VERSION ""

NS_ :

BS_:

BU_: BPCM ECM EVCU2 IDCM MCPA MCPB SGCP

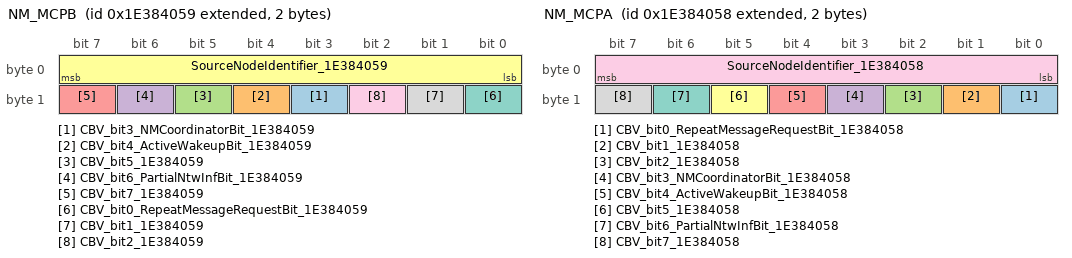
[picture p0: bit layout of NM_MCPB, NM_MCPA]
BO_ 2654486617 NM_MCPB: 2 MCPB
 SG_ CBV_bit3_NMCoordinatorBit_1E384059 : 11|1@0+ (1,0) [0|1] "" SGCP,EVCU2,MCPA,IDCM,BPCM,ECM
 SG_ CBV_bit4_ActiveWakeupBit_1E384059 : 12|1@0+ (1,0) [0|1] "" SGCP,EVCU2,MCPA,IDCM,BPCM,ECM
 SG_ CBV_bit5_1E384059 : 13|1@0+ (1,0) [0|1] "" SGCP,EVCU2,MCPA,IDCM,BPCM,ECM
 SG_ CBV_bit6_PartialNtwInfBit_1E384059 : 14|1@0+ (1,0) [0|1] "" SGCP,EVCU2,MCPA,IDCM,BPCM,ECM
 SG_ CBV_bit7_1E384059 : 15|1@0+ (1,0) [0|1] "" SGCP,EVCU2,MCPA,IDCM,BPCM,ECM
 SG_ SourceNodeIdentifier_1E384059 : 7|8@0+ (1,0) [0|255] "-"  SGCP,EVCU2,MCPA,IDCM,BPCM,ECM
 SG_ CBV_bit0_RepeatMessageRequestBit_1E384059 : 8|1@0+ (1,0) [0|1] "" SGCP,EVCU2,MCPA,IDCM,BPCM,ECM
 SG_ CBV_bit1_1E384059 : 9|1@0+ (1,0) [0|1] "" SGCP,EVCU2,MCPA,IDCM,BPCM,ECM
 SG_ CBV_bit2_1E384059 : 10|1@0+ (1,0) [0|1] "" SGCP,EVCU2,MCPA,IDCM,BPCM,ECM

BO_ 2654486616 NM_MCPA: 2 MCPA
 SG_ CBV_bit0_RepeatMessageRequestBit_1E384058 : 8|1@0+ (1,0) [0|1] "" SGCP,EVCU2,MCPB,IDCM,BPCM,ECM
 SG_ CBV_bit1_1E384058 : 9|1@0+ (1,0) [0|1] "" SGCP,EVCU2,MCPB,IDCM,BPCM,ECM
 SG_ CBV_bit2_1E384058 : 10|1@0+ (1,0) [0|1] "" SGCP,EVCU2,MCPB,IDCM,BPCM,ECM
 SG_ CBV_bit3_NMCoordinatorBit_1E384058 : 11|1@0+ (1,0) [0|1] "" SGCP,EVCU2,MCPB,IDCM,BPCM,ECM
 SG_ CBV_bit4_ActiveWakeupBit_1E384058 : 12|1@0+ (1,0) [0|1] "" SGCP,EVCU2,MCPB,IDCM,BPCM,ECM
 SG_ CBV_bit5_1E384058 : 13|1@0+ (1,0) [0|1] "" SGCP,EVCU2,MCPB,IDCM,BPCM,ECM
 SG_ CBV_bit6_PartialNtwInfBit_1E384058 : 14|1@0+ (1,0) [0|1] "" SGCP,EVCU2,MCPB,IDCM,BPCM,ECM
 SG_ CBV_bit7_1E384058 : 15|1@0+ (1,0) [0|1] "" SGCP,EVCU2,MCPB,IDCM,BPCM,ECM
 SG_ SourceNodeIdentifier_1E384058 : 7|8@0+ (1,0) [0|255] "-"  SGCP,EVCU2,MCPB,IDCM,BPCM,ECM

BO_ 2564682005 DIAGNOSTIC_ROE_MCPB: 8 MCPB
 SG_ N_PDU_18DDF115 : 7|64@0+ (1,0) [0|0] "" EVCU2

BO_ 2564682004 DIAGNOSTIC_ROE_MCPA: 8 MCPA
 SG_ N_PDU_18DDF114 : 7|64@0+ (1,0) [0|0] "" EVCU2

BO_ 2564682261 DIAGNOSTIC_ROE_FD_MCPB: 64 MCPB
 SG_ N_PDU_18DDF215 : 7|64@0+ (1,0) [0|0] "" EVCU2

BO_ 2564682260 DIAGNOSTIC_ROE_FD_MCPA: 64 MCPA
 SG_ N_PDU_18DDF214 : 7|64@0+ (1,0) [0|0] "" EVCU2

BO_ 2564485396 DIAGNOSTIC_RESPONSE_MCPA: 8 MCPA
 SG_ N_PDU_18DAF114 : 7|64@0+ (1,0) [0|0] "" EVCU2

BO_ 2564485653 DIAGNOSTIC_RESPONSE_FD_MCPB: 64 MCPB
 SG_ N_PDU_18DAF215 : 7|64@0+ (1,0) [0|0] "" EVCU2

BO_ 2564485652 DIAGNOSTIC_RESPONSE_FD_MCPA: 64 MCPA
 SG_ N_PDU_18DAF214 : 7|64@0+ (1,0) [0|0] "" EVCU2

BO_ 2564429297 DIAGNOSTIC_REQUEST_MCPB: 8 EVCU2
 SG_ N_PDU_18DA15F1 : 7|64@0+ (1,0) [0|0] "" MCPB

BO_ 2564429041 DIAGNOSTIC_REQUEST_MCPA: 8 EVCU2
 SG_ N_PDU_18DA14F1 : 7|64@0+ (1,0) [0|0] "" MCPA

BO_ 2564429298 DIAGNOSTIC_REQUEST_FD_MCPB: 64 EVCU2
 SG_ N_PDU_18DA15F2 : 7|64@0+ (1,0) [0|0] "" MCPB

BO_ 2564429042 DIAGNOSTIC_REQUEST_FD_MCPA: 64 EVCU2
 SG_ N_PDU_18DA14F2 : 7|64@0+ (1,0) [0|0] "" MCPA

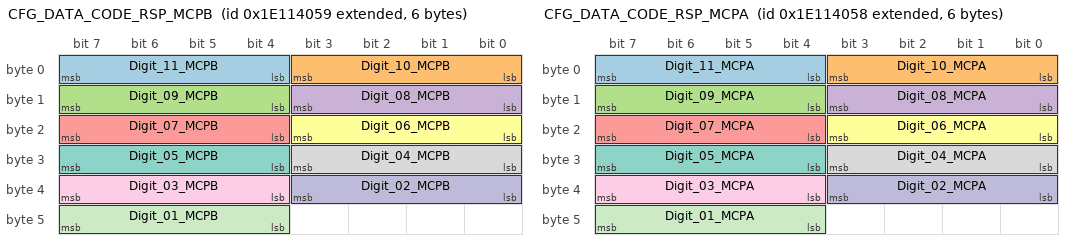
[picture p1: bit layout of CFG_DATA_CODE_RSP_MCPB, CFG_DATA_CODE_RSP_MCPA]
BO_ 2651930713 CFG_DATA_CODE_RSP_MCPB: 6 MCPB
 SG_ Digit_11_MCPB : 7|4@0+ (1,0) [0|15] "-"  EVCU2
 SG_ Digit_10_MCPB : 3|4@0+ (1,0) [0|15] "-"  EVCU2
 SG_ Digit_09_MCPB : 15|4@0+ (1,0) [0|15] "-"  EVCU2
 SG_ Digit_08_MCPB : 11|4@0+ (1,0) [0|15] "-"  EVCU2
 SG_ Digit_07_MCPB : 23|4@0+ (1,0) [0|15] "-"  EVCU2
 SG_ Digit_06_MCPB : 19|4@0+ (1,0) [0|15] "-"  EVCU2
 SG_ Digit_05_MCPB : 31|4@0+ (1,0) [0|15] "-"  EVCU2
 SG_ Digit_04_MCPB : 27|4@0+ (1,0) [0|15] "-"  EVCU2
 SG_ Digit_03_MCPB : 39|4@0+ (1,0) [0|15] "-"  EVCU2
 SG_ Digit_02_MCPB : 35|4@0+ (1,0) [0|15] "-"  EVCU2
 SG_ Digit_01_MCPB : 47|4@0+ (1,0) [0|15] "-"  EVCU2

BO_ 2651930712 CFG_DATA_CODE_RSP_MCPA: 6 MCPA
 SG_ Digit_11_MCPA : 7|4@0+ (1,0) [0|15] "-"  EVCU2
 SG_ Digit_10_MCPA : 3|4@0+ (1,0) [0|15] "-"  EVCU2
 SG_ Digit_09_MCPA : 15|4@0+ (1,0) [0|15] "-"  EVCU2
 SG_ Digit_08_MCPA : 11|4@0+ (1,0) [0|15] "-"  EVCU2
 SG_ Digit_07_MCPA : 23|4@0+ (1,0) [0|15] "-"  EVCU2
 SG_ Digit_06_MCPA : 19|4@0+ (1,0) [0|15] "-"  EVCU2
 SG_ Digit_05_MCPA : 31|4@0+ (1,0) [0|15] "-"  EVCU2
 SG_ Digit_04_MCPA : 27|4@0+ (1,0) [0|15] "-"  EVCU2
 SG_ Digit_03_MCPA : 39|4@0+ (1,0) [0|15] "-"  EVCU2
 SG_ Digit_02_MCPA : 35|4@0+ (1,0) [0|15] "-"  EVCU2
 SG_ Digit_01_MCPA : 47|4@0+ (1,0) [0|15] "-"  EVCU2

BO_ 244 BATTERY_HV: 64 BPCM
 SG_ ImpactHardwireV : 500|1@0+ (1,0) [0|1] "" EVCU2,MCPB,MCPA,IDCM
 SG_ ImpactHardwire : 501|1@0+ (1,0) [0|1] "" EVCU2,MCPB,MCPA,IDCM

BO_ 250 APM_VDCM: 32 IDCM
 SG_ APM_Water_Temp : 95|8@0+ (1,-40) [-40|214] "°C"  EVCU2
 SG_ APM_RecoveryAction : 101|8@0+ (1,0) [0|255] "" EVCU2
 SG_ APM_PSFB_Temp2 : 75|12@0+ (0.1,-40) [-40|369.4] "°C"  EVCU2
 SG_ APM_PSFB_Temp1 : 71|12@0+ (0.1,-40) [-40|369.4] "°C"  EVCU2
 SG_ APM_LV_V_Fbk : 47|12@0+ (0.009143,0) [0|37.431442] "V"  EVCU2
 SG_ APM_LV_I_Fbk : 23|12@0+ (0.076917,0) [0|314.898198] "A"  EVCU2
 SG_ APM_HV_V_Fbk : 51|12@0+ (0.445636,0) [0|1824.433784] "V"  EVCU2
 SG_ APM_HV_I_Fbk : 27|12@0+ (0.002718,0) [0|11.127492] "A"  EVCU2
 SG_ APM_Buck_Temp : 3|12@0+ (0.1,-40) [-40|369.4] "°C"  EVCU2
 SG_ APM_UtilPctOfDCDC : 154|7@0+ (1,0) [0|127] "%"  EVCU2
 SG_ APM_TempColdPlate : 146|8@0+ (1,-40) [-40|215] "degC"  EVCU2
 SG_ APM_PowerLimitMode : 112|1@0+ (1,0) [0|1] "" EVCU2
 SG_ APM_OutputPower : 179|10@0+ (3,0) [0|3069] "W"  EVCU2
 SG_ APM_InputPower : 173|10@0+ (3,0) [0|3069] "W"  EVCU2
 SG_ APM_IdcHvSetPFdbk : 140|10@0+ (0.2,-100) [-100|104.6] "Amp"  EVCU2
 SG_ APM_HvVsetPFdbk : 185|9@0+ (1,0) [0|511] "V"  EVCU2
 SG_ APM_HvOverVStatus : 114|1@0+ (1,0) [0|1] "" EVCU2
 SG_ APM_FailureType : 103|2@0+ (1,0) [0|3] "" EVCU2
 SG_ APM_FailureReason : 122|6@0+ (1,0) [0|63] "" EVCU2
 SG_ APM_EstPwrLoss : 132|8@0+ (2,0) [0|510] "W"  EVCU2
 SG_ APM_DeratingReason : 127|5@0+ (1,0) [0|31] "" EVCU2
 SG_ APM_DeratingModeStatus : 109|3@0+ (1,0) [0|7] "" EVCU2
 SG_ APM_CurrentLimitMode : 113|1@0+ (1,0) [0|1] "" EVCU2
 SG_ APM_CtrlSts_Fbk : 7|4@0+ (1,0) [0|15] "" EVCU2
 SG_ MessageCounter_APM_VDCM : 243|4@0+ (1,0) [0|15] "-"  EVCU2
 SG_ CRC_APM_VDCM : 255|8@0+ (1,0) [0|255] "-"  EVCU2
 SG_ APM_DeratingPower : 163|6@0+ (50,0) [0|3100] "W"  EVCU2

BO_ 2564485397 DIAGNOSTIC_RESPONSE_MCPB: 8 MCPB
 SG_ N_PDU_18DAF115 : 7|64@0+ (1,0) [0|0] "" EVCU2

BO_ 546 VDCM_OBCM2: 64 EVCU2
 SG_ VDCM_MaxChrgTime_sec : 47|8@0+ (10,0) [0|2550] "sec"  IDCM
 SG_ VDCM_MaxChrgTime_min : 39|8@0+ (1,0) [0|255] "min"  IDCM
 SG_ VDCM_EV_Batt_Max_T_Limit : 23|8@0+ (1,0) [0|255] "°C"  IDCM
 SG_ VDCM_EstChrgTime_min : 31|8@0+ (1,0) [0|255] "min"  IDCM
 SG_ VDCM_ChrgMode_Req : 15|8@0+ (1,0) [0|255] "" IDCM
 SG_ VDCM_ChrgCurrDeviationErr : 48|1@0+ (1,0) [0|1] "" IDCM
 SG_ VDCM_ChrgCompleteReason : 63|3@0+ (1,0) [0|7] "" IDCM
 SG_ VDCM_BattUnderVolt : 51|1@0+ (1,0) [0|1] "" IDCM
 SG_ VDCM_BattOverVolt : 52|1@0+ (1,0) [0|1] "" IDCM
 SG_ VDCM_BattFullSOC_prc : 7|8@0+ (1,0) [0|255] "%"  IDCM
 SG_ CPIM_Over_Temperature : 54|1@0+ (1,0) [0|1] "" IDCM
 SG_ CPIM_Error : 55|1@0+ (1,0) [0|1] "" IDCM
 SG_ WeldCheck_Complete : 258|1@0+ (1,0) [0|1] "" IDCM
 SG_ VDCM_SOCIsOOR : 273|2@0+ (1,0) [0|3] "" IDCM
 SG_ VDCM_ChargeCurrIsOOR : 287|2@0+ (1,0) [0|3] "" IDCM
 SG_ VDCM_CellVoltIsOOR : 275|2@0+ (1,0) [0|3] "" IDCM
 SG_ VDCM_BattTempIsOOR : 285|2@0+ (1,0) [0|3] "" IDCM
 SG_ ReadyToChargeState : 259|1@0+ (1,0) [0|1] "" IDCM
 SG_ HCP_SessionStopCmd : 260|1@0+ (1,0) [0|1] "" IDCM
 SG_ HCP_DC_Retry : 249|5@0+ (1,0) [0|31] "" IDCM
 SG_ DCChrg_BatSideCurrent_VDCM : 237|10@0+ (1,-50) [-50|973] "A"  IDCM
 SG_ BMS_Max_Pk_Volt_Allowed_VDCM : 196|10@0+ (1,0) [0|1022] "V"  IDCM
 SG_ BMS_Max_Cell_Volt_Allowed_Vldty : 98|1@0+ (1,0) [0|1] "" IDCM
 SG_ BMS_Max_Cell_Volt_Allowed_VDCM : 95|13@0+ (0.001,0) [0|8.19] "V"  IDCM
 SG_ BMS_HV_Trac_PreCha_Contac_Sts_V : 176|3@0+ (1,0) [0|7] "" MCPB,MCPA,IDCM,BPCM
 SG_ BMS_HV_Trac_Main_Contac_Sts_VDCM : 189|3@0+ (1,0) [0|7] "" MCPB,MCPA,IDCM,BPCM
 SG_ BMS_HV_Temperature_Min_VDCM : 118|11@0+ (0.1,-40) [-40|164.6] "°C"  IDCM
 SG_ BMS_HV_Temperature_Max_VDCM : 97|11@0+ (0.1,-40) [-40|164.6] "°C"  IDCM
 SG_ BMS_HV_SOC_AccuracySts_VDCM : 161|2@0+ (1,0) [0|2] "-"  IDCM
 SG_ BMS_HV_NumCellMinTemp_VDCM : 123|9@0+ (1,0) [0|510] "" IDCM
 SG_ BMS_HV_NumCellMaxVolt_VDCM : 130|8@0+ (1,0) [0|255] "" IDCM
 SG_ BMS_HV_NumCellMaxTemp_VDCM : 172|9@0+ (1,0) [0|510] "" IDCM
 SG_ BMS_HV_Low_Temp_Thrsh_VDCM : 159|11@0+ (0.1,-40) [-40|164.7] "°C"  IDCM
 SG_ BMS_HV_InternalVoltage_VDCM : 213|13@0+ (0.1,90.9) [90.9|910] "V"  MCPB,MCPA,IDCM,BPCM
 SG_ BMS_HV_High_Temp_Thrsh_VDCM : 138|11@0+ (0.1,-40) [-40|164.7] "°C"  IDCM
 SG_ BMS_HV_Common_Contactor_Sts_VDCM : 164|3@0+ (1,0) [0|6] "" MCPB,MCPA,IDCM,BPCM
 SG_ BMS_HV_Battery_GFD_Sts_VDCM : 179|3@0+ (1,0) [0|7] "" MCPB,MCPA,IDCM,BPCM
 SG_ BMS_HV_BatIntrlk_InternalStat_V : 175|3@0+ (1,0) [0|7] "" MCPB,MCPA,IDCM,BPCM
 SG_ BMS_HV_AC_Char_Main_Contac_Sts_ : 200|3@0+ (1,0) [0|7] "" MCPB,MCPA,IDCM,BPCM
 SG_ BMS_Cell_Volt_Min_Vldty_VDCM : 80|1@0+ (1,0) [0|1] "" IDCM
 SG_ BMS_Cell_Volt_Min_VDCM : 77|13@0+ (0.001,0) [0|8.19] "V"  IDCM
 SG_ BMS_Cell_Volt_Max_Vldty_VDCM : 78|1@0+ (1,0) [0|1] "" IDCM
 SG_ BMS_Cell_Volt_Max_VDCM : 59|13@0+ (0.001,0) [0|8.19] "V"  IDCM
 SG_ AC_Chrg_Branch_Voltage_VDCM : 243|10@0+ (1,0) [0|1023] "V"  IDCM
 SG_ BMS_HV_Char_PreCha_Contac_Sts_V : 199|3@0+ (1,0) [0|7] "" MCPB,MCPA,IDCM,BPCM
 SG_ BMS_HV_Char_Main_Contac_Sts_VDCM : 186|3@0+ (1,0) [0|7] "" MCPB,MCPA,IDCM,BPCM
 SG_ BMS_HV_TractionBusVoltage_VDCM : 311|10@0+ (1,0) [0|1023] "V"  MCPB,MCPA,IDCM,BPCM
 SG_ BMS_HV_Trac_Bus_Sts_VDCM : 283|3@0+ (1,0) [0|7] "" MCPB,MCPA,IDCM,BPCM
 SG_ BMS_HV_ChargingBusVoltage_VDCM : 289|10@0+ (1,0) [0|1023] "V"  MCPB,MCPA,IDCM,BPCM
 SG_ BMS_HV_Char_Bus_Sts_VDCM : 280|3@0+ (1,0) [0|7] "" MCPB,MCPA,IDCM,BPCM
 SG_ BMS_HV_BatState_VDCM : 293|4@0+ (1,0) [0|15] "" MCPB,MCPA,IDCM,BPCM
 SG_ BMS_HV_BatActualPower_VDCM : 317|15@0+ (0.1,-1638.3) [-1638.3|1638.4] "kW"  MCPB,MCPA,IDCM,BPCM
 SG_ VDCM_ChargingPermitting : 53|1@0+ (1,0) [0|1] "" IDCM
 SG_ GBT_Target_Voltage_Reached : 334|2@0+ (1,0) [0|3] "" IDCM
 SG_ GBT_Target_Cell_Voltage_Reached : 332|2@0+ (1,0) [0|3] "" IDCM
 SG_ GBT_Ready_to_Charge : 60|1@0+ (1,0) [0|1] "" IDCM
 SG_ GBT_Desired_SOC_Reached : 50|2@0+ (1,0) [0|3] "" IDCM
 SG_ GBT_Charger_Active_Interruption : 330|2@0+ (1,0) [0|3] "" IDCM
 SG_ MessageCounter_VO2 : 435|4@0+ (1,0) [0|15] "" IDCM,BPCM
 SG_ CRC_VO2 : 447|8@0+ (1,0) [0|255] "" IDCM,BPCM

BO_ 496 PARK_DATA: 24 MCPB
 SG_ MessageCounter_PARK_DATA : 115|4@0+ (1,0) [0|15] "" EVCU2
 SG_ CRC_PARK_DATA : 127|8@0+ (1,0) [0|255] "" EVCU2
 SG_ PlockFailSts : 4|3@0+ (1,0) [0|6] "" EVCU2
 SG_ Plock_PosSensor : 1|3@0+ (1,0) [0|6] "" EVCU2
 SG_ Plock_MotorPosSts : 29|3@0+ (1,0) [0|6] "" EVCU2
 SG_ MPR_PosSensor : 14|3@0+ (1,0) [0|6] "" EVCU2
 SG_ Plock_fdbk_sts : 7|3@0+ (1,0) [0|7] "" EVCU2

BO_ 544 OBCM_VDCM2: 64 IDCM
 SG_ Plug_Locked_by_EVSE : 52|2@0+ (1,0) [0|2] "" EVCU2
 SG_ HVCMS_EVSEID : 7|32@0+ (1,0) [0|4294967294] "" EVCU2
 SG_ ExtChargerSts : 42|2@0+ (1,0) [0|2] "" EVCU2
 SG_ EVSE_Error : 54|2@0+ (1,0) [0|2] "" EVCU2
 SG_ EVSE_ChrgStopControl : 40|2@0+ (1,0) [0|2] "" EVCU2
 SG_ Charger_WeldingDetectAvail : 44|2@0+ (1,0) [0|2] "" EVCU2
 SG_ Charger_StndbyReqReason : 47|3@0+ (1,0) [0|6] "" EVCU2
 SG_ Charger_StndbyReq : 33|2@0+ (1,0) [0|2] "" EVCU2
 SG_ Charger_FaultStates : 37|4@0+ (1,0) [0|14] "" EVCU2
 SG_ CC2VoltDetError : 39|2@0+ (1,0) [0|2] "" EVCU2
 SG_ OBCM_CSSts : 152|2@0+ (1,0) [0|3] "" EVCU2
 SG_ OBCM_CP3Sts : 158|3@0+ (1,0) [0|7] "" EVCU2
 SG_ OBCM_CP2Sts : 145|3@0+ (1,0) [0|7] "" EVCU2
 SG_ OBCM_CCSts : 155|3@0+ (1,0) [0|7] "" EVCU2
 SG_ OBCM_APAMSts : 147|2@0+ (1,0) [0|3] "" EVCU2
 SG_ TCP_Communication_Terminated : 162|1@0+ (1,0) [0|1] "" EVCU2
 SG_ OBCM_CP1Sts : 166|3@0+ (1,0) [0|7] "" EVCU2
 SG_ TxGBTMessageResponse : 61|5@0+ (1,0) [0|31] "" EVCU2
 SG_ TxGBTMessageRequest : 50|5@0+ (1,0) [0|31] "" EVCU2
 SG_ OBCM_Timeout : 56|1@0+ (1,0) [0|1] "" EVCU2
 SG_ EVCC_FailureSts : 163|1@0+ (1,0) [0|1] "" EVCU2
 SG_ CC2_VoltageValue : 71|8@0+ (0.1,0) [0|25.5] "V"  EVCU2
 SG_ GBT_EVSE_Charge_Permitting : 79|1@0+ (1,0) [0|1] "" EVCU2
 SG_ MessageCounter_OV2 : 435|4@0+ (1,0) [0|15] "" EVCU2
 SG_ CRC_OV2 : 447|8@0+ (1,0) [0|255] "" EVCU2
 SG_ EVSE_NotificationMaxDelay : 87|18@0+ (1,0) [0|262143] "s"  EVCU2

BO_ 1454 MCPB_DATA: 16 MCPB
 SG_ MCPB_Service_Lamp_Request : 22|1@0+ (1,0) [0|1] "" EVCU2

BO_ 1444 MCPA_DATA: 16 MCPA
 SG_ MCPA_Service_Lamp_Request : 22|1@0+ (1,0) [0|1] "" EVCU2

BO_ 1790 BATTERY_HV2: 32 BPCM
 SG_ BMS_HV_SOC_AccuracySts : 17|2@0+ (1,0) [0|2] "-"  EVCU2
 SG_ BMS_HV_Low_Temp_Thrsh : 12|11@0+ (0.1,-40) [-40|164.7] "°C"  EVCU2
 SG_ BMS_HV_High_Temp_Thrsh : 7|11@0+ (0.1,-40) [-40|164.7] "°C"  EVCU2
 SG_ HVBatCell_Voltage_Low_Thrsh : 49|13@0+ (0.001,0) [0|8.191] "" EVCU2
 SG_ HVBatCell_Voltage_High_Thrsh : 46|13@0+ (0.001,0) [0|8.191] "" EVCU2
 SG_ HEV_OnRq_BPCM : 31|1@0+ (1,0) [0|1] "" EVCU2
 SG_ BMS_HV_SOC_Min : 30|8@0+ (0.391257,0) [0|100] "%"  EVCU2
 SG_ BMS_HV_SOC_Max : 38|8@0+ (0.392157,0) [0|100] "%"  EVCU2

BO_ 105 VDCM_PWT3: 64 EVCU2
 SG_ T7_Sensor_Temp : 330|11@0+ (0.1,-40) [-40|164.7] "°C"  SGCP,MCPB,MCPA
 SG_ T7_CoolantTempVldty : 331|1@0+ (1,0) [0|1] "" SGCP,MCPB,MCPA
 SG_ T4_Sensor_Temp : 378|11@0+ (0.1,-40) [-40|164.7] "°C"  SGCP,MCPB,MCPA
 SG_ PwrElecSnsr_TEMP : 55|8@0+ (1,-40) [-40|215] "°C"  SGCP
 SG_ PwrElecPmp_TEMP : 47|8@0+ (1,-40) [-40|215] "°C"  SGCP
 SG_ ClrLgsDiagInfo : 431|1@0+ (1,0) [0|1] "" IDCM
 SG_ PIMRR_CoolantFlow : 318|7@0+ (0.5,0) [0|63.5] "Lpm"  SGCP

BO_ 260 PIM_RR: 64 MCPB
 SG_ INVRRInterlockSts : 253|2@0+ (1,0) [0|3] "" EVCU2
 SG_ InvRR_DC_Voltage : 191|10@0+ (1,0) [0|1022] "V"  EVCU2
 SG_ InvRR_DerateReason : 143|4@0+ (1,0) [0|15] "-"  EVCU2
 SG_ InvRR_ACVoltage : 104|10@0+ (1,0) [0|1022] "V"  EVCU2
 SG_ RPM_MCPB : 22|16@0+ (1,-32768) [-32768|32767] "rpm"  EVCU2
 SG_ MCPB_Torque_Achieved_V : 38|1@0+ (1,0) [0|1] "" EVCU2
 SG_ MCPB_Torque_Achieved : 251|13@0+ (0.125,-512) [-512|511.875] "Nm"  EVCU2
 SG_ MCPB_TorqAchieved_AEMD_V : 35|1@0+ (1,0) [0|1] "" EVCU2
 SG_ MCPB_TorqAchieved_AEMD : 302|13@0+ (0.125,-512) [-512|511.875] "Nm"  EVCU2
 SG_ MCPB_Spd_Lim : 343|16@0+ (1,-32767) [-32767|32678] "rpm"  EVCU2
 SG_ MCPB_RPM_V : 204|1@0+ (1,0) [0|1] "" EVCU2
 SG_ MCPB_MtrMinCpbltyTrq : 324|13@0+ (0.125,-512) [-512|511.875] "Nm"  EVCU2
 SG_ MCPB_MtrMaxCpbltyTrq : 305|13@0+ (0.125,-512) [-512|511.875] "Nm"  EVCU2
 SG_ MCPB_MtrIndex : 147|5@0+ (1,0) [0|31] "" EVCU2
 SG_ MCPB_MinTorq : 283|13@0+ (0.125,-512) [-512|511.875] "Nm"  EVCU2
 SG_ MCPB_MaxTorq : 264|13@0+ (0.125,-512) [-512|511.875] "Nm"  EVCU2
 SG_ MCPB_Invrtr_State : 151|4@0+ (1,0) [0|15] "" EVCU2
 SG_ MCPB_HV_CnctrOpn_Req : 34|1@0+ (1,0) [0|1] "" EVCU2
 SG_ MCPB_Dschrge_Status : 102|2@0+ (1,0) [0|3] "" EVCU2
 SG_ MCPB_DeratingFactor : 270|6@0+ (0.02,0) [0|1.26] "" EVCU2
 SG_ MCPB_DC_Volt_V : 36|1@0+ (1,0) [0|1] "" EVCU2
 SG_ MCPB_DC_Current_V : 37|1@0+ (1,0) [0|1] "" EVCU2
 SG_ MCPB_DC_Current : 391|15@0+ (0.1,-1638.4) [-1638.4|1638.3] "A"  EVCU2,BPCM
 SG_ MCPB_CpbltySpdDivVolt : 392|16@0+ (1,0) [0|65535] "V"  EVCU2
 SG_ MCPB_AccelRawV : 32|1@0+ (1,0) [0|1] "" EVCU2
 SG_ MCPB_AccelRaw : 359|16@0+ (1,0) [0|65535] "" EVCU2
 SG_ MCPB_6SO_Status : 47|2@0+ (1,0) [0|3] "" EVCU2
 SG_ MCPB_3PS_Pos : 33|1@0+ (1,0) [0|1] "" EVCU2
 SG_ MC_PRR1 : 499|4@0+ (1,0) [0|15] "" EVCU2,BPCM
 SG_ InvRR_CoolantTemp : 375|11@0+ (0.1,-40) [-40|164.7] "°C"  EVCU2
 SG_ CRC_PRR1 : 511|8@0+ (1,0) [0|255] "" EVCU2,BPCM
 SG_ MCPB_SPT_Stat : 158|2@0+ (1,0) [0|3] "" EVCU2

BO_ 1062 MCPA_DATA2: 64 MCPA
 SG_ MCPA_Temp : 7|8@0+ (1,-40) [-40|215] "°C"  EVCU2
 SG_ MCPA_Rotor_Temperature : 31|8@0+ (1,-40) [-40|215] "°C"  EVCU2
 SG_ MCPA_Inverter_Temp : 15|8@0+ (1,-40) [-40|215] "°C"  EVCU2
 SG_ MCPA_Control_Board_Temperature : 23|8@0+ (1,-40) [-40|215] "°C"  EVCU2
 SG_ CLrDiagInfo_MCPA : 248|1@0+ (1,0) [0|1] "" EVCU2
 SG_ MessageCounter_MCPA_DATA2 : 435|4@0+ (1,0) [0|15] "" EVCU2
 SG_ CRC_MCPA_DATA2 : 447|8@0+ (1,0) [0|255] "" EVCU2
 SG_ MCPA_PIM_DC_Side_Busbar_Temp : 423|8@0+ (1,-40) [-40|215] "°C"  EVCU2
 SG_ MCPA_Service_Lamp_Request_2 : 47|1@0+ (1,0) [0|1] "" EVCU2

BO_ 1031 HV_CHARGER1: 64 IDCM
 SG_ InputCurrentAvailable : 96|9@0+ (1,0) [0|300] "Amp"  EVCU2
 SG_ AC_Side_Volt3 : 164|13@0+ (0.1,0) [0|819] "Volts"  EVCU2
 SG_ AC_Side_Volt2 : 145|13@0+ (0.1,0) [0|819] "Volts"  EVCU2
 SG_ AC_Side_Volt1 : 142|13@0+ (0.1,0) [0|819] "Volts"  EVCU2
 SG_ AC_Side_Curr3 : 121|11@0+ (0.1,-100) [-100|104.6] "Amp"  EVCU2
 SG_ AC_Side_Curr2 : 65|11@0+ (0.1,-100) [-100|104.6] "Amp"  EVCU2
 SG_ AC_Side_Curr1 : 19|11@0+ (0.1,-100) [-100|104.6] "Amp"  EVCU2
 SG_ ProximitySts : 39|3@0+ (1,0) [0|7] "-"  EVCU2
 SG_ OBCM_SlacSts : 54|2@0+ (1,0) [0|3] "-"  EVCU2
 SG_ OBCM_SdpSts : 102|2@0+ (1,0) [0|3] "" EVCU2
 SG_ OBCInterlockSts : 86|2@0+ (1,0) [0|3] "" EVCU2
 SG_ OBC_DeratingReason : 7|4@0+ (1,0) [0|15] "-"  EVCU2
 SG_ J1772_State : 22|3@0+ (1,0) [0|7] "-"  EVCU2
 SG_ J1772_S2_Sts : 23|1@0+ (1,0) [0|1] "-"  EVCU2
 SG_ InputVoltage_isAC : 82|1@0+ (1,0) [0|1] "-"  EVCU2
 SG_ InputVoltage_is60Hz : 71|1@0+ (1,0) [0|1] "-"  EVCU2
 SG_ HV_Overvoltage : 69|1@0+ (1,0) [0|1] "-"  EVCU2
 SG_ HV_Overcurrent : 68|1@0+ (1,0) [0|1] "-"  EVCU2
 SG_ ControlPilotSts : 36|3@0+ (1,0) [0|7] "-"  EVCU2
 SG_ ChargeEnableSts : 181|2@0+ (1,0) [0|2] "-"  EVCU2
 SG_ ChargeCurrentAvailable : 49|10@0+ (0.1,0) [0|102.3] "Amp"  EVCU2
 SG_ ChargeCurrent : 33|10@0+ (0.1,0) [0|102.3] "Amp"  EVCU2
 SG_ BatterySideCurrent : 81|11@0+ (0.1,-50) [-50|154.7] "Amp"  EVCU2
 SG_ AC_Present : 70|1@0+ (1,0) [0|1] "-"  EVCU2
 SG_ AC_HighLoadWarning : 51|1@0+ (1,0) [0|1] "-"  EVCU2
 SG_ Supported_VerNumberMinor : 264|3@0+ (1,0) [0|7] "" EVCU2
 SG_ Supported_VerNumberMajor : 267|3@0+ (1,0) [0|7] "" EVCU2
 SG_ Supported_SchemaID : 270|3@0+ (1,0) [0|7] "" EVCU2
 SG_ Supported_ProtocolName : 257|3@0+ (1,0) [0|7] "" EVCU2
 SG_ MessageCounter_HV_CHARGER1 : 179|4@0+ (1,0) [0|15] "-"  EVCU2
 SG_ EVCC_FailureReason : 263|6@0+ (1,0) [0|63] "" EVCU2
 SG_ CRC_HV_CHARGER1 : 191|8@0+ (1,0) [0|255] "-"  EVCU2
 SG_ BatterySideVoltage : 119|14@0+ (0.1,0) [0|1638.3] "Volts"  EVCU2
 SG_ AC_LnLow : 50|1@0+ (1,0) [0|1] "" EVCU2
 SG_ AC_LnHi : 183|1@0+ (1,0) [0|1] "" EVCU2
 SG_ RCD : 274|1@0+ (1,0) [0|1] "-"  EVCU2
 SG_ EVSENominalVoltage : 273|10@0+ (1,0) [0|1023] "V"  EVCU2
 SG_ EVSEMaxCurrent : 288|9@0+ (1,0) [0|511] "A"  EVCU2

BO_ 300 INVTARGET1: 64 EVCU2
 SG_ UDCMax_Unlim_MCPB : 113|16@0+ (0.01,0) [0|655.35] "V"  MCPB
 SG_ UDCMax_Unlim_MCPA : 65|16@0+ (0.01,0) [0|655.35] "V"  MCPA
 SG_ TqGrdtLim_MCPB : 144|16@0+ (0.1,0) [0|6553.5] "Nm/s"  MCPB
 SG_ TqGrdtLim_MCPA : 97|16@0+ (0.1,0) [0|6553.5] "Nm/s"  MCPA
 SG_ TorqueCommand_MCPB : 201|13@0+ (0.125,-512) [-512|511.875] "Nm"  MCPB
 SG_ TorqueCommand_MCPA : 7|13@0+ (0.125,-512) [-512|511.875] "Nm"  MCPA
 SG_ TargetMotorRPM_MCPB : 216|16@0+ (0.5,-16384) [-16384|16383.5] "rpm"  MCPB
 SG_ TargetMotorRPM_MCPA : 22|16@0+ (0.5,-16384) [-16384|16383.5] "rpm"  MCPA
 SG_ SpdGrdtLim_MCPB : 273|11@0+ (20,0) [0|40940] "rpm/s"  MCPB
 SG_ SpdGrdtLim_MCPA : 160|11@0+ (20,0) [0|40940] "rpm/s"  MCPA
 SG_ Mtr_6SO_Request_MCPB : 145|1@0+ (1,0) [0|1] "" MCPB
 SG_ Mtr_6SO_Request_MCPA : 38|1@0+ (1,0) [0|1] "" MCPA
 SG_ ModeCommand_MCPB : 220|4@0+ (1,0) [0|15] "" MCPB
 SG_ ModeCommand_MCPA : 10|4@0+ (1,0) [0|15] "" MCPA
 SG_ MessageCounter_INVTARGET1 : 435|4@0+ (1,0) [0|15] "" SGCP,MCPB,MCPA
 SG_ CRC_INVTARGET1 : 447|8@0+ (1,0) [0|255] "" SGCP,MCPB,MCPA
 SG_ AEMD_MinOffset_MCPB : 252|12@0+ (0.125,-511.875) [-511.875|0] "Nm"  MCPB
 SG_ AEMD_MinOffset_MCPA : 41|12@0+ (0.125,-511.875) [-511.875|0] "Nm"  MCPA
 SG_ AEMD_MaxOffset_MCPB : 232|12@0+ (0.125,0) [0|511.875] "Nm"  MCPB
 SG_ AEMD_MaxOffset_MCPA : 37|12@0+ (0.125,0) [0|511.875] "Nm"  MCPA
 SG_ AEMD_Sclr_Gn_MCPB : 356|9@0+ (0.01,0) [0|5.11] "rad/s"  MCPB
 SG_ AEMD_Sclr_Gn_MCPA : 349|9@0+ (0.01,0) [0|5.11] "rad/s"  MCPA
 SG_ AEMD_Cutoff_FreqHigh_MCPB : 383|8@0+ (0.1,0) [0|25.5] "Hz"  MCPB
 SG_ AEMD_Cutoff_FreqHigh_MCPA : 375|8@0+ (0.1,0) [0|25.5] "Hz"  MCPA
 SG_ Pwr_Electronics_Loop_FlwRate_MC : 57|8@0+ (0.1,0) [0|25.5] "LPM"  MCPA
 SG_ AEMD_Cutoff_FreqLow_MCPB : 407|8@0+ (0.1,4.5) [4.5|30] "Hz"  MCPB
 SG_ AEMD_Cutoff_FreqLow_MCPA : 399|8@0+ (0.1,4.5) [4.5|30] "Hz"  MCPA
 SG_ Pwr_Elec_Loop_FlwRate_MC : 265|8@0+ (0.1,0) [0|25.5] "LPM"  MCPB

CM_ SG_ 1031 InputCurrentAvailable "J1772 input curent available";
CM_ SG_ 1031 AC_Side_Volt3 "AC line voltage3p, p3";
CM_ SG_ 1031 AC_Side_Volt2 "AC line voltage3p, p2";
CM_ SG_ 1031 AC_Side_Volt1 "AC line voltage3p, p1";
CM_ SG_ 1031 AC_Side_Curr3 "AC line current3p, p3";
CM_ SG_ 1031 AC_Side_Curr2 "AC line current3p, p2";
CM_ SG_ 1031 AC_Side_Curr1 "AC line current3p, p1";
CM_ SG_ 260 INVRRInterlockSts "Rear right inverter interlock state";
CM_ SG_ 260 InvRR_DC_Voltage "This signal indicates the Inverter Rear Right DC Voltage.";
CM_ SG_ 1031 ProximitySts "Proximity status based on the voltage level";
CM_ SG_ 1031 OBCM_SlacSts "Communication PLC protocol status, SLAC process";
CM_ SG_ 1031 OBCM_SdpSts "Network protocol implementation status";
CM_ SG_ 1031 OBCInterlockSts "OBCM interlock state";
CM_ SG_ 1031 OBC_DeratingReason "OBCM recovery action";
CM_ SG_ 1031 J1772_State "J1772 status";
CM_ SG_ 1031 InputVoltage_isAC "Input voltage is a/c (dc - [0], ac - [1])";
CM_ SG_ 1031 InputVoltage_is60Hz "Input voltage frrequency is 60 hz (50 hz - [0], 60 hz - [1])";
CM_ SG_ 1031 HV_Overvoltage "High voltage - over voltage";
CM_ SG_ 1031 HV_Overcurrent "High voltage over current";
CM_ SG_ 1031 ControlPilotSts "EVSE pilot status";
CM_ SG_ 1031 ChargeEnableSts "OBCM Feedback status.";
CM_ SG_ 1031 ChargeCurrentAvailable ".";
CM_ SG_ 1031 ChargeCurrent ".";
CM_ SG_ 1031 BatterySideCurrent "Battery side current";
CM_ SG_ 1031 AC_Present "AC line detection";
CM_ SG_ 1031 AC_HighLoadWarning "Infrastructure overload";
CM_ SG_ 250 APM_Water_Temp "This signal indicates the Estimated water temperature  into the cooling channel.";
CM_ SG_ 250 APM_RecoveryAction "This signal indicates the APM recovery action according to fault error";
CM_ SG_ 250 APM_PSFB_Temp2 "This signal indicates the Measured temperature on the phase shift full bridge converter hot spot 2";
CM_ SG_ 250 APM_PSFB_Temp1 "This signal indicates the Measured temperature on the phase shift full bridge converter hot spot 1";
CM_ SG_ 250 APM_LV_V_Fbk "This signal indicates the LV voltage feedback.";
CM_ SG_ 250 APM_LV_I_Fbk "This signal indicates the LV bus current feedback.";
CM_ SG_ 250 APM_HV_V_Fbk "This signal indicates the HV voltage feedback.";
CM_ SG_ 250 APM_HV_I_Fbk "This signal indicates the HV bus current feedback.";
CM_ SG_ 250 APM_Buck_Temp "This signal indicates the Buck stage hot spot temperature.";
CM_ SG_ 546 VDCM_MaxChrgTime_sec "For comm with charging station type A";
CM_ SG_ 546 VDCM_MaxChrgTime_min "For comm with charging station type A";
CM_ SG_ 546 VDCM_EV_Batt_Max_T_Limit "For comm with charging station type B";
CM_ SG_ 546 VDCM_EstChrgTime_min "For comm with charging station type A";
CM_ SG_ 546 VDCM_ChrgMode_Req "For comm with charging station type B";
CM_ SG_ 546 VDCM_BattFullSOC_prc "For comm with charging station type B";
CM_ SG_ 260 InvRR_DerateReason "Inverter Derating Reason.";
CM_ SG_ 260 InvRR_ACVoltage "AC RMS Voltage.";
CM_ SG_ 496 MessageCounter_PARK_DATA "This signal is a counter used for safety checks strategies. This counter is incremented of 1 (one) unit at each frame transmission.";
CM_ SG_ 496 CRC_PARK_DATA "CRC according to SAE J1850 standard at each frame transmission.";
CM_ SG_ 544 Charger_StndbyReq "For communication with charging station type B";
CM_ SG_ 544 CC2VoltDetError "For communication with charging station type B";
CM_ SG_ 1790 BMS_HV_SOC_AccuracySts "This signal indicates the Validity of the SOC value read";
CM_ SG_ 1790 BMS_HV_Low_Temp_Thrsh "This signal indicates the lowest battery pack temperature allowed.";
CM_ SG_ 1790 BMS_HV_High_Temp_Thrsh "This signal indicates the highest battery pack temperature allowed.";
CM_ SG_ 105 T7_Sensor_Temp "T7 Temperature sensor";
CM_ SG_ 105 T7_CoolantTempVldty "Inlet inverter temperature validity";
CM_ SG_ 105 T4_Sensor_Temp "T4 Temperature sensor";
CM_ SG_ 105 PwrElecSnsr_TEMP "PwrElecSensor_TEMP";
CM_ SG_ 105 PwrElecPmp_TEMP "PwrElecPmp temperature";
CM_ SG_ 105 ClrLgsDiagInfo "Clear Legislated Diagnostic Information";
CM_ SG_ 546 WeldCheck_Complete "Weld check complete";
CM_ SG_ 546 ReadyToChargeState "Bit to indicate if EV is ready to charge or not";
CM_ SG_ 546 HCP_SessionStopCmd "Session stop command to stop charging";
CM_ SG_ 546 HCP_DC_Retry "Retry command";
CM_ SG_ 546 DCChrg_BatSideCurrent_VDCM "DC Charging Current, measured in boost, read from EVSE in bypass";
CM_ SG_ 546 BMS_Max_Pk_Volt_Allowed_VDCM "This signal indicates the Maximum battery pack voltage allowed.";
CM_ SG_ 546 BMS_Max_Cell_Volt_Allowed_Vldty "This signal indicates the Max cell voltage allowed valid.";
CM_ SG_ 546 BMS_Max_Cell_Volt_Allowed_VDCM "This signal indicates the Max cell voltage allowed.";
CM_ SG_ 546 BMS_HV_Trac_PreCha_Contac_Sts_V "Traction pre-charge contactor Physical relay status";
CM_ SG_ 546 BMS_HV_Trac_Main_Contac_Sts_VDCM "Traction main contactor physical relay status";
CM_ SG_ 546 BMS_HV_Temperature_Min_VDCM "Battery Minimum Temperature";
CM_ SG_ 546 BMS_HV_Temperature_Max_VDCM "Battery Average Temperature";
CM_ SG_ 546 BMS_HV_SOC_AccuracySts_VDCM "This signal indicates the Validity of the SOC value read";
CM_ SG_ 546 BMS_HV_NumCellMinTemp_VDCM "This signal indicates the Numner of the battery cell with the lowest temperature.";
CM_ SG_ 546 BMS_HV_NumCellMaxVolt_VDCM "This signal indicates the ID No. of cell with max. voltage";
CM_ SG_ 546 BMS_HV_NumCellMaxTemp_VDCM "This signal indicates the Number of the battery cell with the highest temperature.";
CM_ SG_ 546 BMS_HV_Low_Temp_Thrsh_VDCM "This signal indicates the lowest battery pack temperature allowed.";
CM_ SG_ 546 BMS_HV_InternalVoltage_VDCM "This signal indicates the Battery internal voltage as interpreted from VDCM.";
CM_ SG_ 546 BMS_HV_High_Temp_Thrsh_VDCM "This signal indicates the highest battery pack temperature allowed.";
CM_ SG_ 546 BMS_HV_Common_Contactor_Sts_VDCM "HV Bus common contactor status";
CM_ SG_ 546 BMS_HV_Battery_GFD_Sts_VDCM "HV Battery ground fault detection(Isolation)";
CM_ SG_ 546 BMS_HV_BatIntrlk_InternalStat_V "HVIL Status internal";
CM_ SG_ 546 BMS_HV_AC_Char_Main_Contac_Sts_ "AC Charging main contactor physical relay status from VDCM";
CM_ SG_ 546 BMS_Cell_Volt_Min_Vldty_VDCM "This signal indicates the Min cell voltage validity.";
CM_ SG_ 546 BMS_Cell_Volt_Min_VDCM "This signal indicates the Min cell voltage.";
CM_ SG_ 546 BMS_Cell_Volt_Max_Vldty_VDCM "This signal indicates the Max cell voltage validity.";
CM_ SG_ 546 BMS_Cell_Volt_Max_VDCM "This signal indicates the Max cell voltage.";
CM_ SG_ 546 AC_Chrg_Branch_Voltage_VDCM "Voltage measured after AC charge switch interpreted by VDCM";
CM_ SG_ 260 RPM_MCPB "Motor B Speed Raw";
CM_ SG_ 260 MCPB_Torque_Achieved_V "Achieved Torque value Validity, [1] = True";
CM_ SG_ 260 MCPB_Torque_Achieved "Motr B Torque Achieved";
CM_ SG_ 260 MCPB_TorqAchieved_AEMD_V "Motor Torque Achieved Validity";
CM_ SG_ 260 MCPB_TorqAchieved_AEMD "Motor Torque Achieved";
CM_ SG_ 260 MCPB_Spd_Lim "Limited motor speed during reduced performance from MCP B";
CM_ SG_ 260 MCPB_RPM_V "Motor B Speed Validity, [1] = True";
CM_ SG_ 260 MCPB_MtrMinCpbltyTrq "Motor B Min Capability Torque";
CM_ SG_ 260 MCPB_MtrMaxCpbltyTrq "Motor B Max Capability Torque";
CM_ SG_ 260 MCPB_MtrIndex "Motor B Capability Curve Array Index";
CM_ SG_ 260 MCPB_MinTorq "Motor B Minimum Torque";
CM_ SG_ 260 MCPB_MaxTorq "Motor B Maximum Torque";
CM_ SG_ 260 MCPB_Invrtr_State "Inverter State of Operation of Motor B";
CM_ SG_ 260 MCPB_HV_CnctrOpn_Req "HV Battery pack contactor request";
CM_ SG_ 260 MCPB_Dschrge_Status "The active discharge status of MCPB";
CM_ SG_ 260 MCPB_DeratingFactor "Motor B Derating Factor";
CM_ SG_ 260 MCPB_DC_Volt_V "Achieved Torque value Validity, [1] = True";
CM_ SG_ 260 MCPB_DC_Current_V "Achieved Torque value Validity, [1] = True";
CM_ SG_ 260 MCPB_DC_Current "Motor B DC Current";
CM_ SG_ 260 MCPB_CpbltySpdDivVolt "Motor B Speed at Capability Curve";
CM_ SG_ 260 MCPB_AccelRawV "Motor B Acceleration Validity";
CM_ SG_ 260 MCPB_AccelRaw "Motor B Acceleration";
CM_ SG_ 260 MCPB_6SO_Status "Motor B 6SO Status";
CM_ SG_ 260 MCPB_3PS_Pos "3 phase motor short possible from MCP B; True = [1]";
CM_ SG_ 496 PlockFailSts "Park Lock Fail Sts";
CM_ SG_ 496 Plock_PosSensor "Par lock physical position sensor feedback";
CM_ SG_ 496 Plock_MotorPosSts "Park lock motor position status";
CM_ SG_ 496 MPR_PosSensor "Manual Park Release sensor feedback";
CM_ SG_ 544 OBCM_CSSts "Proximity signal of CHAdeMO charging Plug";
CM_ SG_ 544 OBCM_CP3Sts "CP3 line status for CHAdeMO";
CM_ SG_ 544 OBCM_CP2Sts "CP2 line status for CHAdeMO";
CM_ SG_ 544 OBCM_CCSts "Proximity signal of GBT charging contact";
CM_ SG_ 544 OBCM_APAMSts "Status of charging station LV supply on terminals A plus and A minus for GB/T charging";
CM_ SG_ 1454 MCPB_Service_Lamp_Request "The Service Lamp Request from the MCPB";
CM_ SG_ 1062 MCPA_Temp "Motor A temperature";
CM_ SG_ 1062 MCPA_Rotor_Temperature "Rotor Temperature from Motor";
CM_ SG_ 1062 MCPA_Inverter_Temp "Inverter B Temperature";
CM_ SG_ 1062 MCPA_Control_Board_Temperature "Control Board temperature from Motor";
CM_ SG_ 1062 CLrDiagInfo_MCPA "Legislative Diagnostic Clear information for MCPA";
CM_ SG_ 1444 MCPA_Service_Lamp_Request "The Service Light Request from the MCPA";
CM_ SG_ 300 UDCMax_Unlim_MCPB "Maximum DC voltage limit before linear generator derating Consider Max or Min torque. Default 52V";
CM_ SG_ 300 UDCMax_Unlim_MCPA "Maximum DC voltage limit before linear generator derating Consider Max or Min torque. Default 52V";
CM_ SG_ 300 TqGrdtLim_MCPB "Positive or Negative Torque Gradient applied for Torque Control Mode and Speed Control Mode. Default 1000Nm/s";
CM_ SG_ 300 TqGrdtLim_MCPA "Positive or Negative Torque Gradient applied for Torque Control Mode and Speed Control Mode. Default 1000Nm/s";
CM_ SG_ 300 TorqueCommand_MCPB "Torque command for MCPB";
CM_ SG_ 300 TorqueCommand_MCPA "Torque command for MCPA";
CM_ SG_ 300 TargetMotorRPM_MCPB "Target Motor RPM for MCPB";
CM_ SG_ 300 TargetMotorRPM_MCPA "Target Motor RPM for MCPA";
CM_ SG_ 300 SpdGrdtLim_MCPB "Positive or negative (symetric) Speed Request Gradient applicable on both sign only for Speed Control Mode. Default 25,000 rpm/s";
CM_ SG_ 300 SpdGrdtLim_MCPA "Positive or negative (symetric) Speed Request Gradient applicable on both sign only for Speed Control Mode. Default 25,000 rpm/s";
CM_ SG_ 300 Mtr_6SO_Request_MCPB "Six Switch Open Request  for MCPB (1=RequestActive; 0=RequestNotActive)";
CM_ SG_ 300 Mtr_6SO_Request_MCPA "Six Switch Open Request  for MCPA (1=RequestActive; 0=RequestNotActive)";
CM_ SG_ 300 ModeCommand_MCPB "Mode command for MCPB";
CM_ SG_ 300 ModeCommand_MCPA "Mode command for MCPA";
CM_ SG_ 300 MessageCounter_INVTARGET1 "This signal is a counter used for safety checks strategies. This counter is incremented of 1 (one) unit at each frame transmission.";
CM_ SG_ 300 CRC_INVTARGET1 "CRC according to SAE J1850 standard at each frame transmission.";
CM_ SG_ 300 AEMD_MinOffset_MCPB "MCPB AEMD Min Offset";
CM_ SG_ 300 AEMD_MinOffset_MCPA "MCPA AEMD Min Offset";
CM_ SG_ 300 AEMD_MaxOffset_MCPB "MCPB AEMD Max Offset";
CM_ SG_ 300 AEMD_MaxOffset_MCPA "MCPA AEMD Max Offset";
CM_ SG_ 1031 Supported_VerNumberMajor "Version Number Major accepted by  EVCC to support";
CM_ SG_ 1031 Supported_SchemaID "SchemaID accepted by  EVCC to support";
CM_ SG_ 1031 Supported_ProtocolName "Protocol accepted by  EVCC to support";
CM_ SG_ 1031 MessageCounter_HV_CHARGER1 "This signal is a counter used for safety checks strategies. This counter is incremented of 1 (one) unit at each frame transmission.";
CM_ SG_ 1031 EVCC_FailureReason "EVCC failure reason";
CM_ SG_ 1031 CRC_HV_CHARGER1 "CRC according to SAE J1850 standard at each frame transmission.";
CM_ SG_ 1031 BatterySideVoltage "Battery side voltage";
CM_ SG_ 1031 AC_LnLow "AC line voltage too low";
CM_ SG_ 1031 AC_LnHi "AC line voltage too High";
CM_ SG_ 1790 HVBatCell_Voltage_Low_Thrsh "HV Battery Cell Voltage Low Thrsh";
CM_ SG_ 1790 HVBatCell_Voltage_High_Thrsh "HV Battery Cell Voltage High Thrsh";
CM_ SG_ 1790 BMS_HV_SOC_Min "Minimum HV battery cell state of charge";
CM_ SG_ 1790 BMS_HV_SOC_Max "Maximum HV battery cell state of charge";
CM_ SG_ 250 APM_UtilPctOfDCDC "Utilization of DCDC output power capability";
CM_ SG_ 250 APM_TempColdPlate "Cold Plate Temperature";
CM_ SG_ 250 APM_PowerLimitMode "Low voltage at HV side";
CM_ SG_ 250 APM_OutputPower "APM Output Power";
CM_ SG_ 250 APM_InputPower "APM Input Power";
CM_ SG_ 250 APM_IdcHvSetPFdbk "Feedback of set point high voltage current";
CM_ SG_ 250 APM_HvVsetPFdbk "APM HV  Voltage set point feedback";
CM_ SG_ 250 APM_HvOverVStatus "over voltage at HV";
CM_ SG_ 250 APM_FailureType "APM Failure type";
CM_ SG_ 250 APM_FailureReason "FailureReason";
CM_ SG_ 250 APM_EstPwrLoss "Estimated Power Loss";
CM_ SG_ 250 APM_DeratingReason "APM Derating";
CM_ SG_ 250 APM_DeratingModeStatus "APM Derating status during operation";
CM_ SG_ 250 APM_CurrentLimitMode "Derating becasuse of too high current at HV";
CM_ SG_ 250 APM_CtrlSts_Fbk "This signal indicates the DC-DC feedback mode.";
CM_ SG_ 546 BMS_HV_Char_PreCha_Contac_Sts_V "Charging pre-charge contactor physical relay status";
CM_ SG_ 546 BMS_HV_Char_Main_Contac_Sts_VDCM "Charging main contactor physical relay status";
CM_ SG_ 2564485396 N_PDU_18DAF114 "This signal is used for diagnostic purposes";
CM_ SG_ 2564429041 N_PDU_18DA14F1 "This signal is used for diagnostic purposes";
CM_ SG_ 2654486617 CBV_bit3_NMCoordinatorBit_1E384059 "NM Coordinator Sleep Bit";
CM_ SG_ 2654486617 CBV_bit4_ActiveWakeupBit_1E384059 "Active Wakeup Bit";
CM_ SG_ 2654486617 CBV_bit6_PartialNtwInfBit_1E384059 "Partial Network Information Bit (PNI)";
CM_ SG_ 2654486617 SourceNodeIdentifier_1E384059 "Source Node Identifier";
CM_ SG_ 2654486617 CBV_bit0_RepeatMessageRequestBit_1E384059 "Repeat Message Request Bit";
CM_ SG_ 2654486616 CBV_bit0_RepeatMessageRequestBit_1E384058 "Repeat Message Request Bit";
CM_ SG_ 2654486616 CBV_bit3_NMCoordinatorBit_1E384058 "NM Coordinator Sleep Bit";
CM_ SG_ 2654486616 CBV_bit4_ActiveWakeupBit_1E384058 "Active Wakeup Bit";
CM_ SG_ 2654486616 CBV_bit6_PartialNtwInfBit_1E384058 "Partial Network Information Bit (PNI)";
CM_ SG_ 2654486616 SourceNodeIdentifier_1E384058 "Source Node Identifier";
CM_ SG_ 2564682005 N_PDU_18DDF115 "This signal is used for diagnostic purposes";
CM_ SG_ 2564682004 N_PDU_18DDF114 "This signal is used for diagnostic purposes";
CM_ SG_ 2564682261 N_PDU_18DDF215 "This signal is used for diagnostic purposes";
CM_ SG_ 2564682260 N_PDU_18DDF214 "This signal is used for diagnostic purposes";
CM_ SG_ 2564485653 N_PDU_18DAF215 "This signal is used for diagnostic purposes";
CM_ SG_ 2564485652 N_PDU_18DAF214 "This signal is used for diagnostic purposes";
CM_ SG_ 2564429297 N_PDU_18DA15F1 "This signal is used for diagnostic purposes";
CM_ SG_ 2564429298 N_PDU_18DA15F2 "This signal is used for diagnostic purposes";
CM_ SG_ 2564429042 N_PDU_18DA14F2 "This signal is used for diagnostic purposes";
CM_ SG_ 546 BMS_HV_TractionBusVoltage_VDCM "Battery link traction bus voltage";
CM_ SG_ 546 BMS_HV_Trac_Bus_Sts_VDCM "HV Traction Bus Status";
CM_ SG_ 546 BMS_HV_ChargingBusVoltage_VDCM "Battery link charging bus voltage";
CM_ SG_ 546 BMS_HV_Char_Bus_Sts_VDCM "HV Traction Bus Status";
CM_ SG_ 546 BMS_HV_BatState_VDCM "Battery state";
CM_ SG_ 546 BMS_HV_BatActualPower_VDCM "Battery Pack actual power";
CM_ SG_ 260 MC_PRR1 "This signal indicates the Message Counter SaeJ1850.";
CM_ SG_ 260 InvRR_CoolantTemp "PIM Coolant Temperature";
CM_ SG_ 260 CRC_PRR1 "This signal indicates the CRC SaeJ1850.";
CM_ SG_ 544 TCP_Communication_Terminated "TCP communication terminated";
CM_ SG_ 544 OBCM_CP1Sts "CP1 line status for CHAdeMO";
CM_ SG_ 244 ImpactHardwireV "This signal is used to indicate a Valid serial line comunication";
CM_ SG_ 244 ImpactHardwire "This signal is used to indicate that a crash happened";
CM_ SG_ 250 MessageCounter_APM_VDCM "This signal is a counter used for safety checks strategies. This counter is incremented of 1 (one) unit at each frame transmission.";
CM_ SG_ 250 CRC_APM_VDCM "CRC according to SAE J1850 standard at each frame transmission.";
CM_ SG_ 260 MCPB_SPT_Stat "Inverter Isolation Status";
CM_ SG_ 544 TxGBTMessageResponse "Last message communicated from SECC to EVCC for type B.";
CM_ SG_ 544 TxGBTMessageRequest "Last message communicated from EVCC to SECC for type B.";
CM_ SG_ 544 OBCM_Timeout "This signal indicates a timeout from the OBCM side.";
CM_ SG_ 544 EVCC_FailureSts "EVCC failure status";
CM_ SG_ 544 CC2_VoltageValue "This signal indicates the voltage value measured on the CC2 pin.";
CM_ SG_ 546 VDCM_ChargingPermitting "VDCM boolean value that allows the charge process for GBT applications";
CM_ SG_ 546 GBT_Target_Voltage_Reached "BMS end of charge for Targer Voltage Reached for GBT Applications.";
CM_ SG_ 546 GBT_Target_Cell_Voltage_Reached "BMS end of charge for Targer Cell Voltage Reached for GBT Applications.";
CM_ SG_ 546 GBT_Ready_to_Charge "VDCM boolean value for starting charging phase and Ending Charge for GBT applications";
CM_ SG_ 546 GBT_Desired_SOC_Reached "BMS end of charge for Targer SOC Reached for GBT Applications.";
CM_ SG_ 546 GBT_Charger_Active_Interruption "BMS end of charge for Active Interruption for GBT applications";
CM_ SG_ 544 GBT_EVSE_Charge_Permitting "EVSE boolean value that allows to charge for GBT applications.";
CM_ SG_ 300 AEMD_Sclr_Gn_MCPB "MCPB AEMD Scalar Gain";
CM_ SG_ 300 AEMD_Sclr_Gn_MCPA "MCPA AEMD Scalar Gain";
CM_ SG_ 300 AEMD_Cutoff_FreqHigh_MCPB "AEMD cut-off Frequency High for MCPB";
CM_ SG_ 300 AEMD_Cutoff_FreqHigh_MCPA "AEMD cut-off Frequency High for MCPA";
CM_ SG_ 496 Plock_fdbk_sts "Park lock status";
CM_ SG_ 2564485397 N_PDU_18DAF115 "This signal is used for diagnostic purposes";
CM_ SG_ 1031 RCD "Used to Indicate the current status of the Residual Current Device (RCD)";
CM_ SG_ 1031 EVSENominalVoltage "RMS of the maximum voltage vehicle can accept";
CM_ SG_ 1031 EVSEMaxCurrent "EV Maximum current supported per Phase";
CM_ SG_ 105 PIMRR_CoolantFlow "Rear PIM flow rate";
CM_ SG_ 1062 MessageCounter_MCPA_DATA2 "This signal is a counter used for safety checks strategies. This counter is incremented of 1 (one) unit at each frame transmission.";
CM_ SG_ 1062 CRC_MCPA_DATA2 "CRC according to SAE J1850 standard at each frame transmission.";
CM_ SG_ 1062 MCPA_PIM_DC_Side_Busbar_Temp "MCPA busbar temperature in DC side";
CM_ SG_ 1062 MCPA_Service_Lamp_Request_2 "The Service Light Request from the MCPA";
CM_ SG_ 300 Pwr_Electronics_Loop_FlwRate_MC "Inverter cooling liquid flow rate information";
CM_ SG_ 300 AEMD_Cutoff_FreqLow_MCPB "AEMD cut-off Frequency Low for MCPB";
CM_ SG_ 300 AEMD_Cutoff_FreqLow_MCPA "AEMD cut-off Frequency Low for MCPA";
CM_ SG_ 300 Pwr_Elec_Loop_FlwRate_MC "Inverter cooling liquid flow rate information";
CM_ SG_ 546 MessageCounter_VO2 "This signal is a counter used for safety checks strategies. This counter is incremented of 1 (one) unit at each frame transmission.";
CM_ SG_ 546 CRC_VO2 "CRC according to SAE J1850 standard at each frame transmission.";
CM_ SG_ 544 MessageCounter_OV2 "This signal is a counter used for safety checks strategies. This counter is incremented of 1 (one) unit at each frame transmission.";
CM_ SG_ 544 CRC_OV2 "CRC according to SAE J1850 standard at each frame transmission.";
CM_ SG_ 544 EVSE_NotificationMaxDelay "This signal is used to indicate the time until SECC expects the EVCC to react on the action request.";
BA_DEF_ SG_ "GenSigTimeoutTime_ECM" INT 0 65535;
BA_DEF_ SG_ "GenSigTimeoutTime_BPCM" INT 0 65535;
BA_DEF_ SG_ "SystemSignalLongSymbol" STRING ;
BA_DEF_ SG_ "GenSigSendType" ENUM "NotUsed","OnWrite","OnWriteWithRepetition","OnChange","OnChangeWithRepetition","IfActive","IfActiveWithRepetition","NoSigSendType";
BA_DEF_ SG_ "GenSigInactiveValue" INT 0 2147483647;
BA_DEF_ SG_ "GenSigStartValue" INT 0 2147483647;
BA_DEF_ BO_ "CANFD_BRS" ENUM "0","1";
BA_DEF_ BO_ "VFrameFormat" ENUM "StandardCAN","ExtendedCAN","reserved","reserved","reserved","reserved","reserved","reserved","reserved","reserved","reserved","reserved","reserved","reserved","StandardCAN_FD","ExtendedCAN_FD";
BA_DEF_ BO_ "DiagConnection" HEX 0 65535;
BA_DEF_ BO_ "DiagState" ENUM "No","Yes";
BA_DEF_ BO_ "NmAsrMessage" ENUM "No","Yes";
BA_DEF_ BO_ "GenMsgDelayTime" INT 0 65535;
BA_DEF_ BO_ "GenMsgCycleTime" INT 0 65535;
BA_DEF_ BO_ "GenMsgCycleTimeFast" INT 0 65535;
BA_DEF_ BO_ "GenMsgStartDelayTime" INT 0 65535;
BA_DEF_ BO_ "GenMsgILSupport" ENUM "No","Yes";
BA_DEF_ BO_ "GenMsgNrOfRepetition" INT 0 255;
BA_DEF_ BO_ "GenMsgSendType" ENUM "Cyclic","NotUsed","NotUsed","NotUsed","NotUsed","NotUsed","NotUsed","NotUsed","NoMsgSendType";
BA_DEF_ BO_ "NmMessage" ENUM "No","Yes";
BA_DEF_ BO_ "DiagResponse" ENUM "No","Yes";
BA_DEF_ BO_ "Type" ENUM "P","C","PE","COC","PE_Cntrl","E","E_Cntrl","OC","S","BAF","DC","EM","MM","ISO-TP","-";
BA_DEF_ BO_ "DiagRequest" ENUM "No","Yes";
BA_DEF_ SG_ "GenSigTimeoutTime_SGCP" INT 0 65535;
BA_DEF_ SG_ "GenSigTimeoutTime_MCPB" INT 0 65535;
BA_DEF_ SG_ "GenSigTimeoutTime_MCPA" INT 0 65535;
BA_DEF_ SG_ "GenSigTimeoutTime_IDCM" INT 0 65535;
BA_DEF_ SG_ "GenSigTimeoutTime_EVCU2" INT 0 65535;
BA_DEF_DEF_ "GenSigTimeoutTime_ECM" 2500;
BA_DEF_DEF_ "GenSigTimeoutTime_BPCM" 2500;
BA_DEF_DEF_ "SystemSignalLongSymbol" "";
BA_DEF_DEF_ "GenSigSendType" "NoSigSendType";
BA_DEF_DEF_ "GenSigInactiveValue" 0;
BA_DEF_DEF_ "GenSigStartValue" 0;
BA_DEF_DEF_ "CANFD_BRS" "0";
BA_DEF_DEF_ "VFrameFormat" "StandardCAN_FD";
BA_DEF_DEF_ "DiagConnection" 0;
BA_DEF_DEF_ "DiagState" "No";
BA_DEF_DEF_ "NmAsrMessage" "No";
BA_DEF_DEF_ "GenMsgDelayTime" 0;
BA_DEF_DEF_ "GenMsgCycleTime" 0;
BA_DEF_DEF_ "GenMsgCycleTimeFast" 0;
BA_DEF_DEF_ "GenMsgStartDelayTime" 0;
BA_DEF_DEF_ "GenMsgILSupport" "No";
BA_DEF_DEF_ "GenMsgNrOfRepetition" 0;
BA_DEF_DEF_ "GenMsgSendType" "NoMsgSendType";
BA_DEF_DEF_ "NmMessage" "No";
BA_DEF_DEF_ "DiagResponse" "No";
BA_DEF_DEF_ "Type" "-";
BA_DEF_DEF_ "DiagRequest" "No";
BA_DEF_DEF_ "GenSigTimeoutTime_SGCP" 2500;
BA_DEF_DEF_ "GenSigTimeoutTime_MCPB" 2500;
BA_DEF_DEF_ "GenSigTimeoutTime_MCPA" 2500;
BA_DEF_DEF_ "GenSigTimeoutTime_IDCM" 2500;
BA_DEF_DEF_ "GenSigTimeoutTime_EVCU2" 2500;
BA_ "CANFD_BRS" BO_ 2654486617 1;
BA_ "VFrameFormat" BO_ 2654486617 15;
BA_ "NmAsrMessage" BO_ 2654486617 1;
BA_ "NmMessage" BO_ 2654486617 1;
BA_ "Type" BO_ 2654486617 8;
BA_ "CANFD_BRS" BO_ 2654486616 1;
BA_ "VFrameFormat" BO_ 2654486616 15;
BA_ "NmAsrMessage" BO_ 2654486616 1;
BA_ "NmMessage" BO_ 2654486616 1;
BA_ "Type" BO_ 2654486616 8;
BA_ "VFrameFormat" BO_ 2564682005 1;
BA_ "DiagConnection" BO_ 2564682005 61717;
BA_ "DiagResponse" BO_ 2564682005 1;
BA_ "Type" BO_ 2564682005 8;
BA_ "VFrameFormat" BO_ 2564682004 1;
BA_ "DiagConnection" BO_ 2564682004 61716;
BA_ "DiagResponse" BO_ 2564682004 1;
BA_ "Type" BO_ 2564682004 8;
BA_ "CANFD_BRS" BO_ 2564682261 1;
BA_ "VFrameFormat" BO_ 2564682261 15;
BA_ "DiagConnection" BO_ 2564682261 61973;
BA_ "DiagResponse" BO_ 2564682261 1;
BA_ "Type" BO_ 2564682261 8;
BA_ "CANFD_BRS" BO_ 2564682260 1;
BA_ "VFrameFormat" BO_ 2564682260 15;
BA_ "DiagConnection" BO_ 2564682260 61972;
BA_ "DiagResponse" BO_ 2564682260 1;
BA_ "Type" BO_ 2564682260 8;
BA_ "DiagConnection" BO_ 2564485396 61716;
BA_ "DiagResponse" BO_ 2564485396 1;
BA_ "Type" BO_ 2564485396 8;
BA_ "VFrameFormat" BO_ 2564485396 1;
BA_ "CANFD_BRS" BO_ 2564485653 1;
BA_ "VFrameFormat" BO_ 2564485653 15;
BA_ "DiagConnection" BO_ 2564485653 61973;
BA_ "DiagResponse" BO_ 2564485653 1;
BA_ "Type" BO_ 2564485653 8;
BA_ "CANFD_BRS" BO_ 2564485652 1;
BA_ "VFrameFormat" BO_ 2564485652 15;
BA_ "DiagConnection" BO_ 2564485652 61972;
BA_ "DiagResponse" BO_ 2564485652 1;
BA_ "Type" BO_ 2564485652 8;
BA_ "VFrameFormat" BO_ 2564429297 1;
BA_ "DiagConnection" BO_ 2564429297 61717;
BA_ "Type" BO_ 2564429297 8;
BA_ "DiagRequest" BO_ 2564429297 1;
BA_ "Type" BO_ 2564429041 8;
BA_ "DiagRequest" BO_ 2564429041 1;
BA_ "VFrameFormat" BO_ 2564429041 1;
BA_ "DiagConnection" BO_ 2564429041 61716;
BA_ "CANFD_BRS" BO_ 2564429298 1;
BA_ "VFrameFormat" BO_ 2564429298 15;
BA_ "DiagConnection" BO_ 2564429298 61973;
BA_ "Type" BO_ 2564429298 8;
BA_ "DiagRequest" BO_ 2564429298 1;
BA_ "CANFD_BRS" BO_ 2564429042 1;
BA_ "VFrameFormat" BO_ 2564429042 15;
BA_ "DiagConnection" BO_ 2564429042 61972;
BA_ "Type" BO_ 2564429042 8;
BA_ "DiagRequest" BO_ 2564429042 1;
BA_ "CANFD_BRS" BO_ 2651930713 1;
BA_ "VFrameFormat" BO_ 2651930713 15;
BA_ "GenMsgILSupport" BO_ 2651930713 1;
BA_ "Type" BO_ 2651930713 11;
BA_ "CANFD_BRS" BO_ 2651930712 1;
BA_ "VFrameFormat" BO_ 2651930712 15;
BA_ "GenMsgILSupport" BO_ 2651930712 1;
BA_ "Type" BO_ 2651930712 11;
BA_ "CANFD_BRS" BO_ 244 1;
BA_ "GenMsgCycleTime" BO_ 244 10;
BA_ "GenMsgILSupport" BO_ 244 1;
BA_ "GenMsgSendType" BO_ 244 0;
BA_ "Type" BO_ 244 1;
BA_ "CANFD_BRS" BO_ 250 1;
BA_ "GenMsgCycleTime" BO_ 250 20;
BA_ "GenMsgILSupport" BO_ 250 1;
BA_ "GenMsgSendType" BO_ 250 0;
BA_ "Type" BO_ 250 1;
BA_ "VFrameFormat" BO_ 2564485397 1;
BA_ "DiagConnection" BO_ 2564485397 61717;
BA_ "DiagResponse" BO_ 2564485397 1;
BA_ "Type" BO_ 2564485397 8;
BA_ "CANFD_BRS" BO_ 546 1;
BA_ "GenMsgCycleTime" BO_ 546 20;
BA_ "GenMsgILSupport" BO_ 546 1;
BA_ "GenMsgSendType" BO_ 546 0;
BA_ "Type" BO_ 546 1;
BA_ "CANFD_BRS" BO_ 496 1;
BA_ "GenMsgCycleTime" BO_ 496 10;
BA_ "GenMsgILSupport" BO_ 496 1;
BA_ "GenMsgSendType" BO_ 496 0;
BA_ "Type" BO_ 496 1;
BA_ "CANFD_BRS" BO_ 544 1;
BA_ "GenMsgCycleTime" BO_ 544 20;
BA_ "GenMsgILSupport" BO_ 544 1;
BA_ "GenMsgSendType" BO_ 544 0;
BA_ "Type" BO_ 544 1;
BA_ "CANFD_BRS" BO_ 1454 1;
BA_ "GenMsgDelayTime" BO_ 1454 20;
BA_ "GenMsgCycleTime" BO_ 1454 1000;
BA_ "GenMsgCycleTimeFast" BO_ 1454 20;
BA_ "GenMsgILSupport" BO_ 1454 1;
BA_ "GenMsgNrOfRepetition" BO_ 1454 3;
BA_ "GenMsgSendType" BO_ 1454 0;
BA_ "Type" BO_ 1454 3;
BA_ "CANFD_BRS" BO_ 1444 1;
BA_ "GenMsgDelayTime" BO_ 1444 20;
BA_ "GenMsgCycleTime" BO_ 1444 1000;
BA_ "GenMsgCycleTimeFast" BO_ 1444 20;
BA_ "GenMsgILSupport" BO_ 1444 1;
BA_ "GenMsgNrOfRepetition" BO_ 1444 3;
BA_ "GenMsgSendType" BO_ 1444 0;
BA_ "Type" BO_ 1444 3;
BA_ "CANFD_BRS" BO_ 1790 1;
BA_ "GenMsgDelayTime" BO_ 1790 20;
BA_ "GenMsgCycleTime" BO_ 1790 500;
BA_ "GenMsgILSupport" BO_ 1790 1;
BA_ "GenMsgSendType" BO_ 1790 0;
BA_ "Type" BO_ 1790 3;
BA_ "GenMsgILSupport" BO_ 105 1;
BA_ "GenMsgSendType" BO_ 105 0;
BA_ "Type" BO_ 105 3;
BA_ "CANFD_BRS" BO_ 105 1;
BA_ "GenMsgDelayTime" BO_ 105 100;
BA_ "GenMsgCycleTime" BO_ 105 1000;
BA_ "CANFD_BRS" BO_ 260 1;
BA_ "GenMsgCycleTime" BO_ 260 10;
BA_ "GenMsgILSupport" BO_ 260 1;
BA_ "GenMsgSendType" BO_ 260 0;
BA_ "Type" BO_ 260 1;
BA_ "CANFD_BRS" BO_ 1062 1;
BA_ "GenMsgCycleTime" BO_ 1062 100;
BA_ "GenMsgILSupport" BO_ 1062 1;
BA_ "GenMsgSendType" BO_ 1062 0;
BA_ "Type" BO_ 1062 1;
BA_ "CANFD_BRS" BO_ 1031 1;
BA_ "GenMsgCycleTime" BO_ 1031 100;
BA_ "GenMsgILSupport" BO_ 1031 1;
BA_ "GenMsgSendType" BO_ 1031 0;
BA_ "Type" BO_ 1031 1;
BA_ "CANFD_BRS" BO_ 300 1;
BA_ "GenMsgCycleTime" BO_ 300 10;
BA_ "GenMsgILSupport" BO_ 300 1;
BA_ "GenMsgSendType" BO_ 300 0;
BA_ "Type" BO_ 300 1;
BA_ "GenSigTimeoutTime_ECM" SG_ 105 ClrLgsDiagInfo 0;
BA_ "GenSigTimeoutTime_BPCM" SG_ 105 ClrLgsDiagInfo 0;
BA_ "GenSigTimeoutTime_SGCP" SG_ 105 ClrLgsDiagInfo 0;
BA_ "GenSigTimeoutTime_MCPB" SG_ 105 ClrLgsDiagInfo 0;
BA_ "GenSigTimeoutTime_MCPA" SG_ 105 ClrLgsDiagInfo 0;
BA_ "GenSigTimeoutTime_EVCU2" SG_ 105 ClrLgsDiagInfo 0;
BA_ "GenSigTimeoutTime_BPCM" SG_ 105 PwrElecPmp_TEMP 0;
BA_ "GenSigStartValue" SG_ 105 PwrElecPmp_TEMP 255;
BA_ "GenSigTimeoutTime_MCPB" SG_ 105 PwrElecPmp_TEMP 0;
BA_ "GenSigTimeoutTime_MCPA" SG_ 105 PwrElecPmp_TEMP 0;
BA_ "GenSigTimeoutTime_IDCM" SG_ 105 PwrElecPmp_TEMP 0;
BA_ "GenSigTimeoutTime_EVCU2" SG_ 105 PwrElecPmp_TEMP 0;
BA_ "GenSigTimeoutTime_ECM" SG_ 105 T7_CoolantTempVldty 0;
BA_ "GenSigTimeoutTime_BPCM" SG_ 105 T7_CoolantTempVldty 0;
BA_ "GenSigSendType" SG_ 105 T7_CoolantTempVldty 3;
BA_ "GenSigTimeoutTime_IDCM" SG_ 105 T7_CoolantTempVldty 0;
BA_ "GenSigTimeoutTime_EVCU2" SG_ 105 T7_CoolantTempVldty 0;
BA_ "GenSigTimeoutTime_MCPB" SG_ 546 VDCM_MaxChrgTime_sec 0;
BA_ "GenSigTimeoutTime_MCPA" SG_ 546 VDCM_MaxChrgTime_sec 0;
BA_ "GenSigTimeoutTime_EVCU2" SG_ 546 VDCM_MaxChrgTime_sec 0;
BA_ "GenSigTimeoutTime_ECM" SG_ 546 VDCM_MaxChrgTime_sec 0;
BA_ "GenSigTimeoutTime_BPCM" SG_ 546 VDCM_MaxChrgTime_sec 0;
BA_ "GenSigStartValue" SG_ 546 VDCM_MaxChrgTime_sec 255;
BA_ "GenSigTimeoutTime_SGCP" SG_ 546 VDCM_MaxChrgTime_sec 0;
BA_ "GenSigTimeoutTime_ECM" SG_ 546 VDCM_MaxChrgTime_min 0;
BA_ "GenSigTimeoutTime_BPCM" SG_ 546 VDCM_MaxChrgTime_min 0;
BA_ "GenSigStartValue" SG_ 546 VDCM_MaxChrgTime_min 255;
BA_ "GenSigTimeoutTime_SGCP" SG_ 546 VDCM_MaxChrgTime_min 0;
BA_ "GenSigTimeoutTime_MCPB" SG_ 546 VDCM_MaxChrgTime_min 0;
BA_ "GenSigTimeoutTime_MCPA" SG_ 546 VDCM_MaxChrgTime_min 0;
BA_ "GenSigTimeoutTime_EVCU2" SG_ 546 VDCM_MaxChrgTime_min 0;
BA_ "GenSigTimeoutTime_ECM" SG_ 546 VDCM_EV_Batt_Max_T_Limit 0;
BA_ "GenSigTimeoutTime_BPCM" SG_ 546 VDCM_EV_Batt_Max_T_Limit 0;
BA_ "GenSigStartValue" SG_ 546 VDCM_EV_Batt_Max_T_Limit 60;
BA_ "GenSigTimeoutTime_SGCP" SG_ 546 VDCM_EV_Batt_Max_T_Limit 0;
BA_ "GenSigTimeoutTime_MCPB" SG_ 546 VDCM_EV_Batt_Max_T_Limit 0;
BA_ "GenSigTimeoutTime_MCPA" SG_ 546 VDCM_EV_Batt_Max_T_Limit 0;
BA_ "GenSigTimeoutTime_EVCU2" SG_ 546 VDCM_EV_Batt_Max_T_Limit 0;
BA_ "GenSigTimeoutTime_ECM" SG_ 546 VDCM_EstChrgTime_min 0;
BA_ "GenSigTimeoutTime_BPCM" SG_ 546 VDCM_EstChrgTime_min 0;
BA_ "GenSigStartValue" SG_ 546 VDCM_EstChrgTime_min 255;
BA_ "GenSigTimeoutTime_SGCP" SG_ 546 VDCM_EstChrgTime_min 0;
BA_ "GenSigTimeoutTime_MCPB" SG_ 546 VDCM_EstChrgTime_min 0;
BA_ "GenSigTimeoutTime_MCPA" SG_ 546 VDCM_EstChrgTime_min 0;
BA_ "GenSigTimeoutTime_EVCU2" SG_ 546 VDCM_EstChrgTime_min 0;
BA_ "GenSigTimeoutTime_ECM" SG_ 546 VDCM_BattUnderVolt 0;
BA_ "GenSigTimeoutTime_BPCM" SG_ 546 VDCM_BattUnderVolt 0;
BA_ "GenSigTimeoutTime_SGCP" SG_ 546 VDCM_BattUnderVolt 0;
BA_ "GenSigTimeoutTime_MCPB" SG_ 546 VDCM_BattUnderVolt 0;
BA_ "GenSigTimeoutTime_MCPA" SG_ 546 VDCM_BattUnderVolt 0;
BA_ "GenSigTimeoutTime_EVCU2" SG_ 546 VDCM_BattUnderVolt 0;
BA_ "GenSigTimeoutTime_ECM" SG_ 546 VDCM_BattOverVolt 0;
BA_ "GenSigTimeoutTime_BPCM" SG_ 546 VDCM_BattOverVolt 0;
BA_ "GenSigTimeoutTime_SGCP" SG_ 546 VDCM_BattOverVolt 0;
BA_ "GenSigTimeoutTime_MCPB" SG_ 546 VDCM_BattOverVolt 0;
BA_ "GenSigTimeoutTime_MCPA" SG_ 546 VDCM_BattOverVolt 0;
BA_ "GenSigTimeoutTime_EVCU2" SG_ 546 VDCM_BattOverVolt 0;
BA_ "GenSigTimeoutTime_ECM" SG_ 546 VDCM_BattFullSOC_prc 0;
BA_ "GenSigTimeoutTime_BPCM" SG_ 546 VDCM_BattFullSOC_prc 0;
BA_ "GenSigTimeoutTime_ECM" SG_ 546 WeldCheck_Complete 0;
BA_ "GenSigTimeoutTime_BPCM" SG_ 546 WeldCheck_Complete 0;
BA_ "GenSigTimeoutTime_SGCP" SG_ 546 WeldCheck_Complete 0;
BA_ "GenSigTimeoutTime_MCPB" SG_ 546 WeldCheck_Complete 0;
BA_ "GenSigTimeoutTime_MCPA" SG_ 546 WeldCheck_Complete 0;
BA_ "GenSigTimeoutTime_EVCU2" SG_ 546 WeldCheck_Complete 0;
BA_ "GenSigTimeoutTime_ECM" SG_ 546 VDCM_SOCIsOOR 0;
BA_ "GenSigTimeoutTime_BPCM" SG_ 546 VDCM_SOCIsOOR 0;
BA_ "GenSigTimeoutTime_SGCP" SG_ 546 VDCM_SOCIsOOR 0;
BA_ "GenSigTimeoutTime_MCPB" SG_ 546 VDCM_SOCIsOOR 0;
BA_ "GenSigTimeoutTime_MCPA" SG_ 546 VDCM_SOCIsOOR 0;
BA_ "GenSigTimeoutTime_EVCU2" SG_ 546 VDCM_SOCIsOOR 0;
BA_ "GenSigTimeoutTime_SGCP" SG_ 546 GBT_Charger_Active_Interruption 0;
BA_ "GenSigTimeoutTime_MCPB" SG_ 546 GBT_Charger_Active_Interruption 0;
BA_ "GenSigTimeoutTime_MCPA" SG_ 546 GBT_Charger_Active_Interruption 0;
BA_ "GenSigTimeoutTime_EVCU2" SG_ 546 GBT_Charger_Active_Interruption 0;
BA_ "GenSigTimeoutTime_ECM" SG_ 546 GBT_Ready_to_Charge 0;
BA_ "GenSigTimeoutTime_BPCM" SG_ 546 GBT_Ready_to_Charge 0;
BA_ "GenSigTimeoutTime_SGCP" SG_ 546 GBT_Ready_to_Charge 0;
BA_ "GenSigTimeoutTime_MCPB" SG_ 546 GBT_Ready_to_Charge 0;
BA_ "GenSigTimeoutTime_MCPA" SG_ 546 GBT_Ready_to_Charge 0;
BA_ "GenSigTimeoutTime_EVCU2" SG_ 546 GBT_Ready_to_Charge 0;
BA_ "GenSigTimeoutTime_ECM" SG_ 546 GBT_Target_Cell_Voltage_Reached 0;
BA_ "GenSigTimeoutTime_BPCM" SG_ 546 GBT_Target_Cell_Voltage_Reached 0;
BA_ "GenSigTimeoutTime_SGCP" SG_ 546 GBT_Target_Cell_Voltage_Reached 0;
BA_ "GenSigTimeoutTime_MCPB" SG_ 546 GBT_Target_Cell_Voltage_Reached 0;
BA_ "GenSigTimeoutTime_MCPA" SG_ 546 GBT_Target_Cell_Voltage_Reached 0;
BA_ "GenSigTimeoutTime_EVCU2" SG_ 546 GBT_Target_Cell_Voltage_Reached 0;
BA_ "GenSigTimeoutTime_ECM" SG_ 546 GBT_Target_Voltage_Reached 0;
BA_ "GenSigTimeoutTime_BPCM" SG_ 546 GBT_Target_Voltage_Reached 0;
BA_ "GenSigTimeoutTime_SGCP" SG_ 546 GBT_Target_Voltage_Reached 0;
BA_ "GenSigTimeoutTime_MCPB" SG_ 546 GBT_Target_Voltage_Reached 0;
BA_ "GenSigTimeoutTime_MCPA" SG_ 546 GBT_Target_Voltage_Reached 0;
BA_ "GenSigTimeoutTime_EVCU2" SG_ 546 GBT_Target_Voltage_Reached 0;
BA_ "GenSigTimeoutTime_ECM" SG_ 546 VDCM_ChargingPermitting 0;
BA_ "GenSigTimeoutTime_BPCM" SG_ 546 VDCM_ChargingPermitting 0;
BA_ "GenSigTimeoutTime_SGCP" SG_ 546 VDCM_ChargingPermitting 0;
BA_ "GenSigTimeoutTime_MCPB" SG_ 546 VDCM_ChargingPermitting 0;
BA_ "GenSigTimeoutTime_MCPA" SG_ 546 VDCM_ChargingPermitting 0;
BA_ "GenSigTimeoutTime_EVCU2" SG_ 546 VDCM_ChargingPermitting 0;
BA_ "GenSigTimeoutTime_ECM" SG_ 546 BMS_HV_BatActualPower_VDCM 0;
BA_ "GenSigTimeoutTime_SGCP" SG_ 546 BMS_HV_BatActualPower_VDCM 0;
BA_ "GenSigTimeoutTime_EVCU2" SG_ 546 BMS_HV_BatActualPower_VDCM 0;
BA_ "GenSigTimeoutTime_ECM" SG_ 546 BMS_HV_BatState_VDCM 0;
BA_ "GenSigTimeoutTime_SGCP" SG_ 546 BMS_HV_BatState_VDCM 0;
BA_ "GenSigTimeoutTime_EVCU2" SG_ 546 BMS_HV_BatState_VDCM 0;
BA_ "GenSigTimeoutTime_ECM" SG_ 546 BMS_HV_ChargingBusVoltage_VDCM 0;
BA_ "GenSigTimeoutTime_SGCP" SG_ 546 BMS_HV_ChargingBusVoltage_VDCM 0;
BA_ "GenSigTimeoutTime_EVCU2" SG_ 546 BMS_HV_ChargingBusVoltage_VDCM 0;
BA_ "GenSigTimeoutTime_ECM" SG_ 546 BMS_HV_Char_Bus_Sts_VDCM 0;
BA_ "GenSigTimeoutTime_SGCP" SG_ 546 BMS_HV_Char_Bus_Sts_VDCM 0;
BA_ "GenSigTimeoutTime_EVCU2" SG_ 546 BMS_HV_Char_Bus_Sts_VDCM 0;
BA_ "GenSigTimeoutTime_ECM" SG_ 546 BMS_HV_Char_PreCha_Contac_Sts_V 0;
BA_ "SystemSignalLongSymbol" SG_ 546 BMS_HV_Char_PreCha_Contac_Sts_V "BMS_HV_Char_PreCha_Contac_Sts_VDCM";
BA_ "GenSigTimeoutTime_SGCP" SG_ 546 BMS_HV_Char_PreCha_Contac_Sts_V 0;
BA_ "GenSigTimeoutTime_EVCU2" SG_ 546 BMS_HV_Char_PreCha_Contac_Sts_V 0;
BA_ "GenSigTimeoutTime_ECM" SG_ 546 AC_Chrg_Branch_Voltage_VDCM 0;
BA_ "GenSigTimeoutTime_BPCM" SG_ 546 AC_Chrg_Branch_Voltage_VDCM 0;
BA_ "GenSigTimeoutTime_SGCP" SG_ 546 AC_Chrg_Branch_Voltage_VDCM 0;
BA_ "GenSigTimeoutTime_MCPB" SG_ 546 AC_Chrg_Branch_Voltage_VDCM 0;
BA_ "GenSigTimeoutTime_MCPA" SG_ 546 AC_Chrg_Branch_Voltage_VDCM 0;
BA_ "GenSigTimeoutTime_EVCU2" SG_ 546 AC_Chrg_Branch_Voltage_VDCM 0;
BA_ "GenSigTimeoutTime_ECM" SG_ 546 BMS_Cell_Volt_Max_VDCM 0;
BA_ "GenSigTimeoutTime_BPCM" SG_ 546 BMS_Cell_Volt_Max_VDCM 0;
BA_ "GenSigTimeoutTime_SGCP" SG_ 546 BMS_Cell_Volt_Max_VDCM 0;
BA_ "GenSigTimeoutTime_MCPB" SG_ 546 BMS_Cell_Volt_Max_VDCM 0;
BA_ "GenSigTimeoutTime_MCPA" SG_ 546 BMS_Cell_Volt_Max_VDCM 0;
BA_ "GenSigTimeoutTime_EVCU2" SG_ 546 BMS_Cell_Volt_Max_VDCM 0;
BA_ "GenSigTimeoutTime_ECM" SG_ 546 BMS_Cell_Volt_Max_Vldty_VDCM 0;
BA_ "GenSigTimeoutTime_BPCM" SG_ 546 BMS_Cell_Volt_Max_Vldty_VDCM 0;
BA_ "GenSigTimeoutTime_SGCP" SG_ 546 BMS_Cell_Volt_Max_Vldty_VDCM 0;
BA_ "GenSigTimeoutTime_MCPB" SG_ 546 BMS_Cell_Volt_Max_Vldty_VDCM 0;
BA_ "GenSigTimeoutTime_MCPA" SG_ 546 BMS_Cell_Volt_Max_Vldty_VDCM 0;
BA_ "GenSigTimeoutTime_EVCU2" SG_ 546 BMS_Cell_Volt_Max_Vldty_VDCM 0;
BA_ "GenSigTimeoutTime_ECM" SG_ 546 BMS_Cell_Volt_Min_VDCM 0;
BA_ "GenSigTimeoutTime_BPCM" SG_ 546 BMS_Cell_Volt_Min_VDCM 0;
BA_ "GenSigTimeoutTime_SGCP" SG_ 546 BMS_Cell_Volt_Min_VDCM 0;
BA_ "GenSigTimeoutTime_MCPB" SG_ 546 BMS_Cell_Volt_Min_VDCM 0;
BA_ "GenSigTimeoutTime_MCPA" SG_ 546 BMS_Cell_Volt_Min_VDCM 0;
BA_ "GenSigTimeoutTime_EVCU2" SG_ 546 BMS_Cell_Volt_Min_VDCM 0;
BA_ "GenSigTimeoutTime_ECM" SG_ 546 BMS_Cell_Volt_Min_Vldty_VDCM 0;
BA_ "GenSigTimeoutTime_BPCM" SG_ 546 BMS_Cell_Volt_Min_Vldty_VDCM 0;
BA_ "GenSigTimeoutTime_SGCP" SG_ 546 BMS_Cell_Volt_Min_Vldty_VDCM 0;
BA_ "GenSigTimeoutTime_MCPB" SG_ 546 BMS_Cell_Volt_Min_Vldty_VDCM 0;
BA_ "GenSigTimeoutTime_MCPA" SG_ 546 BMS_Cell_Volt_Min_Vldty_VDCM 0;
BA_ "GenSigTimeoutTime_EVCU2" SG_ 546 BMS_Cell_Volt_Min_Vldty_VDCM 0;
BA_ "GenSigTimeoutTime_ECM" SG_ 546 BMS_HV_AC_Char_Main_Contac_Sts_ 0;
BA_ "SystemSignalLongSymbol" SG_ 546 BMS_HV_AC_Char_Main_Contac_Sts_ "BMS_HV_AC_Char_Main_Contac_Sts_VDCM";
BA_ "GenSigTimeoutTime_SGCP" SG_ 546 BMS_HV_AC_Char_Main_Contac_Sts_ 0;
BA_ "GenSigTimeoutTime_EVCU2" SG_ 546 BMS_HV_AC_Char_Main_Contac_Sts_ 0;
BA_ "GenSigTimeoutTime_ECM" SG_ 546 BMS_HV_BatIntrlk_InternalStat_V 0;
BA_ "SystemSignalLongSymbol" SG_ 546 BMS_HV_BatIntrlk_InternalStat_V "BMS_HV_BatIntrlk_InternalStat_VDCM";
BA_ "GenSigTimeoutTime_SGCP" SG_ 546 BMS_HV_BatIntrlk_InternalStat_V 0;
BA_ "GenSigTimeoutTime_EVCU2" SG_ 546 BMS_HV_BatIntrlk_InternalStat_V 0;
BA_ "GenSigTimeoutTime_ECM" SG_ 546 BMS_HV_Battery_GFD_Sts_VDCM 0;
BA_ "GenSigTimeoutTime_SGCP" SG_ 546 BMS_HV_Battery_GFD_Sts_VDCM 0;
BA_ "GenSigTimeoutTime_EVCU2" SG_ 546 BMS_HV_Battery_GFD_Sts_VDCM 0;
BA_ "GenSigTimeoutTime_ECM" SG_ 546 BMS_HV_Char_Main_Contac_Sts_VDCM 0;
BA_ "GenSigTimeoutTime_SGCP" SG_ 546 BMS_HV_Char_Main_Contac_Sts_VDCM 0;
BA_ "GenSigTimeoutTime_EVCU2" SG_ 546 BMS_HV_Char_Main_Contac_Sts_VDCM 0;
BA_ "GenSigTimeoutTime_ECM" SG_ 546 BMS_HV_InternalVoltage_VDCM 0;
BA_ "GenSigTimeoutTime_ECM" SG_ 546 BMS_HV_Low_Temp_Thrsh_VDCM 0;
BA_ "GenSigTimeoutTime_BPCM" SG_ 546 BMS_HV_Low_Temp_Thrsh_VDCM 0;
BA_ "GenSigTimeoutTime_SGCP" SG_ 546 BMS_HV_Low_Temp_Thrsh_VDCM 0;
BA_ "GenSigTimeoutTime_MCPB" SG_ 546 BMS_HV_Low_Temp_Thrsh_VDCM 0;
BA_ "GenSigTimeoutTime_MCPA" SG_ 546 BMS_HV_Low_Temp_Thrsh_VDCM 0;
BA_ "GenSigTimeoutTime_EVCU2" SG_ 546 BMS_HV_Low_Temp_Thrsh_VDCM 0;
BA_ "GenSigTimeoutTime_ECM" SG_ 546 BMS_HV_NumCellMaxTemp_VDCM 0;
BA_ "GenSigTimeoutTime_BPCM" SG_ 546 BMS_HV_NumCellMaxTemp_VDCM 0;
BA_ "GenSigTimeoutTime_SGCP" SG_ 546 BMS_HV_NumCellMaxTemp_VDCM 0;
BA_ "GenSigTimeoutTime_MCPB" SG_ 546 BMS_HV_NumCellMaxTemp_VDCM 0;
BA_ "GenSigTimeoutTime_MCPA" SG_ 546 BMS_HV_NumCellMaxTemp_VDCM 0;
BA_ "GenSigTimeoutTime_EVCU2" SG_ 546 BMS_HV_NumCellMaxTemp_VDCM 0;
BA_ "GenSigTimeoutTime_ECM" SG_ 546 BMS_HV_NumCellMaxVolt_VDCM 0;
BA_ "GenSigTimeoutTime_BPCM" SG_ 546 BMS_HV_NumCellMaxVolt_VDCM 0;
BA_ "GenSigTimeoutTime_SGCP" SG_ 546 BMS_HV_NumCellMaxVolt_VDCM 0;
BA_ "GenSigTimeoutTime_MCPB" SG_ 546 BMS_HV_NumCellMaxVolt_VDCM 0;
BA_ "GenSigTimeoutTime_MCPA" SG_ 546 BMS_HV_NumCellMaxVolt_VDCM 0;
BA_ "GenSigTimeoutTime_EVCU2" SG_ 546 BMS_HV_NumCellMaxVolt_VDCM 0;
BA_ "GenSigTimeoutTime_ECM" SG_ 546 BMS_HV_Trac_PreCha_Contac_Sts_V 0;
BA_ "SystemSignalLongSymbol" SG_ 546 BMS_HV_Trac_PreCha_Contac_Sts_V "BMS_HV_Trac_PreCha_Contac_Sts_VDCM";
BA_ "GenSigTimeoutTime_SGCP" SG_ 546 BMS_HV_Trac_PreCha_Contac_Sts_V 0;
BA_ "GenSigTimeoutTime_EVCU2" SG_ 546 BMS_HV_Trac_PreCha_Contac_Sts_V 0;
BA_ "GenSigTimeoutTime_ECM" SG_ 546 BMS_Max_Cell_Volt_Allowed_Vldty 0;
BA_ "GenSigTimeoutTime_BPCM" SG_ 546 BMS_Max_Cell_Volt_Allowed_Vldty 0;
BA_ "SystemSignalLongSymbol" SG_ 546 BMS_Max_Cell_Volt_Allowed_Vldty "BMS_Max_Cell_Volt_Allowed_Vldty_VDCM";
BA_ "GenSigTimeoutTime_SGCP" SG_ 546 BMS_Max_Cell_Volt_Allowed_Vldty 0;
BA_ "GenSigTimeoutTime_MCPB" SG_ 546 BMS_Max_Cell_Volt_Allowed_Vldty 0;
BA_ "GenSigTimeoutTime_MCPA" SG_ 546 BMS_Max_Cell_Volt_Allowed_Vldty 0;
BA_ "GenSigTimeoutTime_EVCU2" SG_ 546 BMS_Max_Cell_Volt_Allowed_Vldty 0;
BA_ "GenSigTimeoutTime_ECM" SG_ 2654486617 CBV_bit7_1E384059 0;
BA_ "GenSigTimeoutTime_BPCM" SG_ 2654486617 CBV_bit7_1E384059 0;
BA_ "GenSigTimeoutTime_SGCP" SG_ 2654486617 CBV_bit7_1E384059 0;
BA_ "GenSigTimeoutTime_MCPB" SG_ 2654486617 CBV_bit7_1E384059 0;
BA_ "GenSigTimeoutTime_MCPA" SG_ 2654486617 CBV_bit7_1E384059 0;
BA_ "GenSigTimeoutTime_IDCM" SG_ 2654486617 CBV_bit7_1E384059 0;
BA_ "GenSigTimeoutTime_EVCU2" SG_ 2654486617 CBV_bit7_1E384059 0;
BA_ "GenSigTimeoutTime_ECM" SG_ 2654486617 CBV_bit6_PartialNtwInfBit_1E384059 0;
BA_ "GenSigTimeoutTime_BPCM" SG_ 2654486617 CBV_bit6_PartialNtwInfBit_1E384059 0;
BA_ "GenSigTimeoutTime_SGCP" SG_ 2654486617 CBV_bit6_PartialNtwInfBit_1E384059 0;
BA_ "GenSigTimeoutTime_MCPB" SG_ 2654486617 CBV_bit6_PartialNtwInfBit_1E384059 0;
BA_ "GenSigTimeoutTime_MCPA" SG_ 2654486617 CBV_bit6_PartialNtwInfBit_1E384059 0;
BA_ "GenSigTimeoutTime_IDCM" SG_ 2654486617 CBV_bit6_PartialNtwInfBit_1E384059 0;
BA_ "GenSigTimeoutTime_EVCU2" SG_ 2654486617 CBV_bit6_PartialNtwInfBit_1E384059 0;
BA_ "GenSigTimeoutTime_ECM" SG_ 2654486617 CBV_bit5_1E384059 0;
BA_ "GenSigTimeoutTime_BPCM" SG_ 2654486617 CBV_bit5_1E384059 0;
BA_ "GenSigTimeoutTime_SGCP" SG_ 2654486617 CBV_bit5_1E384059 0;
BA_ "GenSigTimeoutTime_MCPB" SG_ 2654486617 CBV_bit5_1E384059 0;
BA_ "GenSigTimeoutTime_MCPA" SG_ 2654486617 CBV_bit5_1E384059 0;
BA_ "GenSigTimeoutTime_IDCM" SG_ 2654486617 CBV_bit5_1E384059 0;
BA_ "GenSigTimeoutTime_EVCU2" SG_ 2654486617 CBV_bit5_1E384059 0;
BA_ "GenSigTimeoutTime_ECM" SG_ 2654486617 CBV_bit4_ActiveWakeupBit_1E384059 0;
BA_ "GenSigTimeoutTime_BPCM" SG_ 2654486617 CBV_bit4_ActiveWakeupBit_1E384059 0;
BA_ "GenSigTimeoutTime_SGCP" SG_ 2654486617 CBV_bit4_ActiveWakeupBit_1E384059 0;
BA_ "GenSigTimeoutTime_MCPB" SG_ 2654486617 CBV_bit4_ActiveWakeupBit_1E384059 0;
BA_ "GenSigTimeoutTime_ECM" SG_ 2651930713 Digit_11_MCPB 0;
BA_ "GenSigTimeoutTime_BPCM" SG_ 2651930713 Digit_11_MCPB 0;
BA_ "GenSigTimeoutTime_SGCP" SG_ 2651930713 Digit_11_MCPB 0;
BA_ "GenSigTimeoutTime_MCPB" SG_ 2651930713 Digit_11_MCPB 0;
BA_ "GenSigTimeoutTime_MCPA" SG_ 2651930713 Digit_11_MCPB 0;
BA_ "GenSigTimeoutTime_IDCM" SG_ 2651930713 Digit_11_MCPB 0;
BA_ "GenSigTimeoutTime_ECM" SG_ 2651930713 Digit_10_MCPB 0;
BA_ "GenSigTimeoutTime_BPCM" SG_ 2651930713 Digit_10_MCPB 0;
BA_ "GenSigTimeoutTime_SGCP" SG_ 2651930713 Digit_10_MCPB 0;
BA_ "GenSigTimeoutTime_MCPB" SG_ 2651930713 Digit_10_MCPB 0;
BA_ "GenSigTimeoutTime_MCPA" SG_ 2651930713 Digit_10_MCPB 0;
BA_ "GenSigTimeoutTime_IDCM" SG_ 2651930713 Digit_10_MCPB 0;
BA_ "GenSigTimeoutTime_ECM" SG_ 2651930713 Digit_09_MCPB 0;
BA_ "GenSigTimeoutTime_BPCM" SG_ 2651930713 Digit_09_MCPB 0;
BA_ "GenSigTimeoutTime_SGCP" SG_ 2651930713 Digit_09_MCPB 0;
BA_ "GenSigTimeoutTime_MCPB" SG_ 2651930713 Digit_09_MCPB 0;
BA_ "GenSigTimeoutTime_MCPA" SG_ 2651930713 Digit_09_MCPB 0;
BA_ "GenSigTimeoutTime_IDCM" SG_ 2651930713 Digit_09_MCPB 0;
BA_ "GenSigTimeoutTime_ECM" SG_ 2651930713 Digit_08_MCPB 0;
BA_ "GenSigTimeoutTime_BPCM" SG_ 2651930713 Digit_08_MCPB 0;
BA_ "GenSigTimeoutTime_SGCP" SG_ 2651930713 Digit_08_MCPB 0;
BA_ "GenSigTimeoutTime_MCPB" SG_ 2651930713 Digit_08_MCPB 0;
BA_ "GenSigTimeoutTime_MCPA" SG_ 2651930713 Digit_08_MCPB 0;
BA_ "GenSigTimeoutTime_IDCM" SG_ 2651930713 Digit_08_MCPB 0;
BA_ "GenSigTimeoutTime_ECM" SG_ 2651930713 Digit_07_MCPB 0;
BA_ "GenSigTimeoutTime_BPCM" SG_ 2651930713 Digit_07_MCPB 0;
BA_ "GenSigTimeoutTime_SGCP" SG_ 2651930713 Digit_07_MCPB 0;
BA_ "GenSigTimeoutTime_MCPB" SG_ 2651930713 Digit_07_MCPB 0;
BA_ "GenSigTimeoutTime_MCPA" SG_ 2651930713 Digit_07_MCPB 0;
BA_ "GenSigTimeoutTime_IDCM" SG_ 2651930713 Digit_07_MCPB 0;
BA_ "GenSigTimeoutTime_ECM" SG_ 2651930713 Digit_06_MCPB 0;
BA_ "GenSigTimeoutTime_BPCM" SG_ 2651930713 Digit_06_MCPB 0;
BA_ "GenSigTimeoutTime_SGCP" SG_ 2651930713 Digit_06_MCPB 0;
BA_ "GenSigTimeoutTime_MCPB" SG_ 2651930713 Digit_06_MCPB 0;
BA_ "GenSigTimeoutTime_MCPA" SG_ 2651930713 Digit_06_MCPB 0;
BA_ "GenSigTimeoutTime_IDCM" SG_ 2651930713 Digit_06_MCPB 0;
BA_ "GenSigTimeoutTime_ECM" SG_ 2651930713 Digit_05_MCPB 0;
BA_ "GenSigTimeoutTime_BPCM" SG_ 2651930713 Digit_05_MCPB 0;
BA_ "GenSigTimeoutTime_SGCP" SG_ 2651930713 Digit_05_MCPB 0;
BA_ "GenSigTimeoutTime_MCPB" SG_ 2651930713 Digit_05_MCPB 0;
BA_ "GenSigTimeoutTime_MCPA" SG_ 2651930713 Digit_05_MCPB 0;
BA_ "GenSigTimeoutTime_IDCM" SG_ 2651930713 Digit_05_MCPB 0;
BA_ "GenSigTimeoutTime_ECM" SG_ 2651930713 Digit_04_MCPB 0;
BA_ "GenSigTimeoutTime_BPCM" SG_ 2651930713 Digit_04_MCPB 0;
BA_ "GenSigTimeoutTime_SGCP" SG_ 2651930713 Digit_04_MCPB 0;
BA_ "GenSigTimeoutTime_MCPB" SG_ 2651930713 Digit_04_MCPB 0;
BA_ "GenSigTimeoutTime_MCPA" SG_ 2651930713 Digit_04_MCPB 0;
BA_ "GenSigTimeoutTime_IDCM" SG_ 2651930713 Digit_04_MCPB 0;
BA_ "GenSigTimeoutTime_ECM" SG_ 2651930712 Digit_10_MCPA 0;
BA_ "GenSigTimeoutTime_BPCM" SG_ 2651930712 Digit_10_MCPA 0;
BA_ "GenSigTimeoutTime_SGCP" SG_ 2651930712 Digit_10_MCPA 0;
BA_ "GenSigTimeoutTime_MCPB" SG_ 2651930712 Digit_10_MCPA 0;
BA_ "GenSigTimeoutTime_MCPA" SG_ 2651930712 Digit_10_MCPA 0;
BA_ "GenSigTimeoutTime_IDCM" SG_ 2651930712 Digit_10_MCPA 0;
BA_ "GenSigTimeoutTime_ECM" SG_ 2651930712 Digit_09_MCPA 0;
BA_ "GenSigTimeoutTime_BPCM" SG_ 2651930712 Digit_09_MCPA 0;
BA_ "GenSigTimeoutTime_SGCP" SG_ 2651930712 Digit_09_MCPA 0;
BA_ "GenSigTimeoutTime_MCPB" SG_ 2651930712 Digit_09_MCPA 0;
BA_ "GenSigTimeoutTime_MCPA" SG_ 2651930712 Digit_09_MCPA 0;
BA_ "GenSigTimeoutTime_IDCM" SG_ 2651930712 Digit_09_MCPA 0;
BA_ "GenSigTimeoutTime_ECM" SG_ 2651930713 Digit_03_MCPB 0;
BA_ "GenSigTimeoutTime_BPCM" SG_ 2651930713 Digit_03_MCPB 0;
BA_ "GenSigTimeoutTime_SGCP" SG_ 2651930713 Digit_03_MCPB 0;
BA_ "GenSigTimeoutTime_MCPB" SG_ 2651930713 Digit_03_MCPB 0;
BA_ "GenSigTimeoutTime_MCPA" SG_ 2651930713 Digit_03_MCPB 0;
BA_ "GenSigTimeoutTime_IDCM" SG_ 2651930713 Digit_03_MCPB 0;
BA_ "GenSigTimeoutTime_ECM" SG_ 2651930713 Digit_02_MCPB 0;
BA_ "GenSigTimeoutTime_BPCM" SG_ 2651930713 Digit_02_MCPB 0;
BA_ "GenSigTimeoutTime_SGCP" SG_ 2651930713 Digit_02_MCPB 0;
BA_ "GenSigTimeoutTime_MCPB" SG_ 2651930713 Digit_02_MCPB 0;
BA_ "GenSigTimeoutTime_MCPA" SG_ 2651930713 Digit_02_MCPB 0;
BA_ "GenSigTimeoutTime_IDCM" SG_ 2651930713 Digit_02_MCPB 0;
BA_ "GenSigTimeoutTime_ECM" SG_ 2651930713 Digit_01_MCPB 0;
BA_ "GenSigTimeoutTime_BPCM" SG_ 2651930713 Digit_01_MCPB 0;
BA_ "GenSigSendType" SG_ 2651930713 Digit_01_MCPB 1;
BA_ "GenSigTimeoutTime_SGCP" SG_ 2651930713 Digit_01_MCPB 0;
BA_ "GenSigTimeoutTime_MCPB" SG_ 2651930713 Digit_01_MCPB 0;
BA_ "GenSigTimeoutTime_MCPA" SG_ 2651930713 Digit_01_MCPB 0;
BA_ "GenSigTimeoutTime_IDCM" SG_ 2651930713 Digit_01_MCPB 0;
BA_ "GenSigTimeoutTime_ECM" SG_ 2651930712 Digit_11_MCPA 0;
BA_ "GenSigTimeoutTime_BPCM" SG_ 2651930712 Digit_11_MCPA 0;
BA_ "GenSigTimeoutTime_SGCP" SG_ 2651930712 Digit_11_MCPA 0;
BA_ "GenSigTimeoutTime_MCPB" SG_ 2651930712 Digit_11_MCPA 0;
BA_ "GenSigTimeoutTime_MCPA" SG_ 2651930712 Digit_11_MCPA 0;
BA_ "GenSigTimeoutTime_IDCM" SG_ 2651930712 Digit_11_MCPA 0;
BA_ "GenSigTimeoutTime_SGCP" SG_ 2651930712 Digit_06_MCPA 0;
BA_ "GenSigTimeoutTime_MCPB" SG_ 2651930712 Digit_06_MCPA 0;
BA_ "GenSigTimeoutTime_MCPA" SG_ 2651930712 Digit_06_MCPA 0;
BA_ "GenSigTimeoutTime_IDCM" SG_ 2651930712 Digit_06_MCPA 0;
BA_ "GenSigTimeoutTime_ECM" SG_ 2651930712 Digit_05_MCPA 0;
BA_ "GenSigTimeoutTime_BPCM" SG_ 2651930712 Digit_05_MCPA 0;
BA_ "GenSigTimeoutTime_SGCP" SG_ 2651930712 Digit_05_MCPA 0;
BA_ "GenSigTimeoutTime_MCPB" SG_ 2651930712 Digit_05_MCPA 0;
BA_ "GenSigTimeoutTime_MCPA" SG_ 2651930712 Digit_05_MCPA 0;
BA_ "GenSigTimeoutTime_IDCM" SG_ 2651930712 Digit_05_MCPA 0;
BA_ "GenSigTimeoutTime_ECM" SG_ 1454 MCPB_Service_Lamp_Request 0;
BA_ "GenSigTimeoutTime_BPCM" SG_ 1454 MCPB_Service_Lamp_Request 0;
BA_ "GenSigTimeoutTime_SGCP" SG_ 1454 MCPB_Service_Lamp_Request 0;
BA_ "GenSigTimeoutTime_MCPB" SG_ 1454 MCPB_Service_Lamp_Request 0;
BA_ "GenSigTimeoutTime_MCPA" SG_ 1454 MCPB_Service_Lamp_Request 0;
BA_ "GenSigTimeoutTime_IDCM" SG_ 1454 MCPB_Service_Lamp_Request 0;
BA_ "GenSigTimeoutTime_ECM" SG_ 1444 MCPA_Service_Lamp_Request 0;
BA_ "GenSigTimeoutTime_BPCM" SG_ 1444 MCPA_Service_Lamp_Request 0;
BA_ "GenSigTimeoutTime_SGCP" SG_ 1444 MCPA_Service_Lamp_Request 0;
BA_ "GenSigTimeoutTime_MCPB" SG_ 1444 MCPA_Service_Lamp_Request 0;
BA_ "GenSigTimeoutTime_MCPA" SG_ 1444 MCPA_Service_Lamp_Request 0;
BA_ "GenSigTimeoutTime_IDCM" SG_ 1444 MCPA_Service_Lamp_Request 0;
BA_ "GenSigTimeoutTime_ECM" SG_ 2564682260 N_PDU_18DDF214 0;
BA_ "GenSigTimeoutTime_BPCM" SG_ 2564682260 N_PDU_18DDF214 0;
BA_ "GenSigTimeoutTime_SGCP" SG_ 2564682260 N_PDU_18DDF214 0;
BA_ "GenSigTimeoutTime_MCPB" SG_ 2564682260 N_PDU_18DDF214 0;
BA_ "GenSigTimeoutTime_MCPA" SG_ 2564682260 N_PDU_18DDF214 0;
BA_ "GenSigTimeoutTime_IDCM" SG_ 2564682260 N_PDU_18DDF214 0;
BA_ "GenSigTimeoutTime_EVCU2" SG_ 2564682260 N_PDU_18DDF214 0;
BA_ "GenSigTimeoutTime_ECM" SG_ 2564485396 N_PDU_18DAF114 0;
BA_ "GenSigTimeoutTime_BPCM" SG_ 2564485396 N_PDU_18DAF114 0;
BA_ "GenSigTimeoutTime_SGCP" SG_ 2564485396 N_PDU_18DAF114 0;
BA_ "GenSigTimeoutTime_MCPB" SG_ 2564485396 N_PDU_18DAF114 0;
BA_ "GenSigTimeoutTime_MCPA" SG_ 2564485396 N_PDU_18DAF114 0;
BA_ "GenSigTimeoutTime_IDCM" SG_ 2564485396 N_PDU_18DAF114 0;
BA_ "GenSigTimeoutTime_EVCU2" SG_ 2564485396 N_PDU_18DAF114 0;
BA_ "GenSigTimeoutTime_ECM" SG_ 2654486616 CBV_bit4_ActiveWakeupBit_1E384058 0;
BA_ "GenSigTimeoutTime_BPCM" SG_ 2654486616 CBV_bit4_ActiveWakeupBit_1E384058 0;
BA_ "GenSigTimeoutTime_SGCP" SG_ 2654486616 CBV_bit4_ActiveWakeupBit_1E384058 0;
BA_ "GenSigTimeoutTime_MCPB" SG_ 2654486616 CBV_bit4_ActiveWakeupBit_1E384058 0;
BA_ "GenSigTimeoutTime_MCPA" SG_ 2654486616 CBV_bit4_ActiveWakeupBit_1E384058 0;
BA_ "GenSigTimeoutTime_IDCM" SG_ 2654486616 CBV_bit4_ActiveWakeupBit_1E384058 0;
BA_ "GenSigTimeoutTime_EVCU2" SG_ 2654486616 CBV_bit4_ActiveWakeupBit_1E384058 0;
BA_ "GenSigTimeoutTime_ECM" SG_ 2654486616 CBV_bit5_1E384058 0;
BA_ "GenSigTimeoutTime_BPCM" SG_ 2654486616 CBV_bit5_1E384058 0;
BA_ "GenSigTimeoutTime_SGCP" SG_ 2654486616 CBV_bit5_1E384058 0;
BA_ "GenSigTimeoutTime_MCPB" SG_ 2654486616 CBV_bit5_1E384058 0;
BA_ "GenSigTimeoutTime_MCPA" SG_ 2654486616 CBV_bit5_1E384058 0;
BA_ "GenSigTimeoutTime_IDCM" SG_ 2654486616 CBV_bit5_1E384058 0;
BA_ "GenSigTimeoutTime_EVCU2" SG_ 2654486616 CBV_bit5_1E384058 0;
BA_ "GenSigTimeoutTime_IDCM" SG_ 2654486616 CBV_bit6_PartialNtwInfBit_1E384058 0;
BA_ "GenSigTimeoutTime_EVCU2" SG_ 2654486616 CBV_bit6_PartialNtwInfBit_1E384058 0;
BA_ "GenSigTimeoutTime_ECM" SG_ 2654486616 CBV_bit6_PartialNtwInfBit_1E384058 0;
BA_ "GenSigTimeoutTime_BPCM" SG_ 2654486616 CBV_bit6_PartialNtwInfBit_1E384058 0;
BA_ "GenSigTimeoutTime_SGCP" SG_ 2654486616 CBV_bit6_PartialNtwInfBit_1E384058 0;
BA_ "GenSigTimeoutTime_MCPB" SG_ 2654486616 CBV_bit6_PartialNtwInfBit_1E384058 0;
BA_ "GenSigTimeoutTime_MCPA" SG_ 2654486616 CBV_bit6_PartialNtwInfBit_1E384058 0;
BA_ "GenSigTimeoutTime_ECM" SG_ 2654486616 CBV_bit7_1E384058 0;
BA_ "GenSigTimeoutTime_BPCM" SG_ 2654486616 CBV_bit7_1E384058 0;
BA_ "GenSigTimeoutTime_SGCP" SG_ 2654486616 CBV_bit7_1E384058 0;
BA_ "GenSigTimeoutTime_MCPB" SG_ 2654486616 CBV_bit7_1E384058 0;
BA_ "GenSigTimeoutTime_MCPA" SG_ 2654486616 CBV_bit7_1E384058 0;
BA_ "GenSigTimeoutTime_IDCM" SG_ 2654486616 CBV_bit7_1E384058 0;
BA_ "GenSigTimeoutTime_EVCU2" SG_ 2654486616 CBV_bit7_1E384058 0;
BA_ "GenSigTimeoutTime_ECM" SG_ 2564682004 N_PDU_18DDF114 0;
BA_ "GenSigTimeoutTime_BPCM" SG_ 2564682004 N_PDU_18DDF114 0;
BA_ "GenSigTimeoutTime_SGCP" SG_ 2564682004 N_PDU_18DDF114 0;
BA_ "GenSigTimeoutTime_MCPB" SG_ 2564682004 N_PDU_18DDF114 0;
BA_ "GenSigTimeoutTime_MCPA" SG_ 2564682004 N_PDU_18DDF114 0;
BA_ "GenSigTimeoutTime_ECM" SG_ 2654486616 SourceNodeIdentifier_1E384058 0;
BA_ "GenSigTimeoutTime_BPCM" SG_ 2654486616 SourceNodeIdentifier_1E384058 0;
BA_ "GenSigTimeoutTime_SGCP" SG_ 2654486616 SourceNodeIdentifier_1E384058 0;
BA_ "GenSigTimeoutTime_MCPB" SG_ 2654486616 SourceNodeIdentifier_1E384058 0;
BA_ "GenSigTimeoutTime_MCPA" SG_ 2654486616 SourceNodeIdentifier_1E384058 0;
BA_ "GenSigTimeoutTime_IDCM" SG_ 2654486616 SourceNodeIdentifier_1E384058 0;
BA_ "GenSigTimeoutTime_EVCU2" SG_ 2654486616 SourceNodeIdentifier_1E384058 0;
BA_ "GenSigTimeoutTime_ECM" SG_ 2654486616 CBV_bit0_RepeatMessageRequestBit_1E384058 0;
BA_ "GenSigTimeoutTime_BPCM" SG_ 2654486616 CBV_bit0_RepeatMessageRequestBit_1E384058 0;
BA_ "GenSigTimeoutTime_SGCP" SG_ 2654486616 CBV_bit0_RepeatMessageRequestBit_1E384058 0;
BA_ "GenSigTimeoutTime_MCPB" SG_ 2654486616 CBV_bit0_RepeatMessageRequestBit_1E384058 0;
BA_ "GenSigTimeoutTime_MCPA" SG_ 2654486616 CBV_bit0_RepeatMessageRequestBit_1E384058 0;
BA_ "GenSigTimeoutTime_IDCM" SG_ 2654486616 CBV_bit0_RepeatMessageRequestBit_1E384058 0;
BA_ "GenSigTimeoutTime_EVCU2" SG_ 2654486616 CBV_bit0_RepeatMessageRequestBit_1E384058 0;
BA_ "GenSigTimeoutTime_ECM" SG_ 2654486616 CBV_bit1_1E384058 0;
BA_ "GenSigTimeoutTime_BPCM" SG_ 2654486616 CBV_bit1_1E384058 0;
BA_ "GenSigTimeoutTime_SGCP" SG_ 2654486616 CBV_bit1_1E384058 0;
BA_ "GenSigTimeoutTime_MCPB" SG_ 2654486616 CBV_bit1_1E384058 0;
BA_ "GenSigTimeoutTime_MCPA" SG_ 2654486616 CBV_bit1_1E384058 0;
BA_ "GenSigTimeoutTime_IDCM" SG_ 2654486616 CBV_bit1_1E384058 0;
BA_ "GenSigTimeoutTime_EVCU2" SG_ 2654486616 CBV_bit1_1E384058 0;
BA_ "GenSigTimeoutTime_ECM" SG_ 2654486616 CBV_bit2_1E384058 0;
BA_ "GenSigTimeoutTime_BPCM" SG_ 2654486616 CBV_bit2_1E384058 0;
BA_ "GenSigTimeoutTime_SGCP" SG_ 2654486616 CBV_bit2_1E384058 0;
BA_ "GenSigTimeoutTime_MCPB" SG_ 2654486616 CBV_bit2_1E384058 0;
BA_ "GenSigTimeoutTime_MCPA" SG_ 2654486616 CBV_bit2_1E384058 0;
BA_ "GenSigTimeoutTime_IDCM" SG_ 2654486616 CBV_bit2_1E384058 0;
BA_ "GenSigTimeoutTime_EVCU2" SG_ 2654486616 CBV_bit2_1E384058 0;
BA_ "GenSigTimeoutTime_ECM" SG_ 2654486616 CBV_bit3_NMCoordinatorBit_1E384058 0;
BA_ "GenSigTimeoutTime_BPCM" SG_ 2654486616 CBV_bit3_NMCoordinatorBit_1E384058 0;
BA_ "GenSigTimeoutTime_SGCP" SG_ 2654486616 CBV_bit3_NMCoordinatorBit_1E384058 0;
BA_ "GenSigTimeoutTime_MCPB" SG_ 2654486616 CBV_bit3_NMCoordinatorBit_1E384058 0;
BA_ "GenSigTimeoutTime_MCPA" SG_ 2654486616 CBV_bit3_NMCoordinatorBit_1E384058 0;
BA_ "GenSigTimeoutTime_IDCM" SG_ 2654486616 CBV_bit3_NMCoordinatorBit_1E384058 0;
BA_ "GenSigTimeoutTime_EVCU2" SG_ 2654486616 CBV_bit3_NMCoordinatorBit_1E384058 0;
BA_ "GenSigTimeoutTime_IDCM" SG_ 2564682004 N_PDU_18DDF114 0;
BA_ "GenSigTimeoutTime_EVCU2" SG_ 2564682004 N_PDU_18DDF114 0;
BA_ "GenSigTimeoutTime_ECM" SG_ 2564485652 N_PDU_18DAF214 0;
BA_ "GenSigTimeoutTime_BPCM" SG_ 2564485652 N_PDU_18DAF214 0;
BA_ "GenSigTimeoutTime_SGCP" SG_ 2564485652 N_PDU_18DAF214 0;
BA_ "GenSigTimeoutTime_MCPB" SG_ 2564485652 N_PDU_18DAF214 0;
BA_ "GenSigTimeoutTime_MCPA" SG_ 2564485652 N_PDU_18DAF214 0;
BA_ "GenSigTimeoutTime_IDCM" SG_ 2564485652 N_PDU_18DAF214 0;
BA_ "GenSigTimeoutTime_EVCU2" SG_ 2564485652 N_PDU_18DAF214 0;
BA_ "GenSigTimeoutTime_SGCP" SG_ 1062 MCPA_PIM_DC_Side_Busbar_Temp 0;
BA_ "GenSigTimeoutTime_MCPB" SG_ 1062 MCPA_PIM_DC_Side_Busbar_Temp 0;
BA_ "GenSigTimeoutTime_MCPA" SG_ 1062 MCPA_PIM_DC_Side_Busbar_Temp 0;
BA_ "GenSigTimeoutTime_IDCM" SG_ 1062 MCPA_PIM_DC_Side_Busbar_Temp 0;
BA_ "GenSigTimeoutTime_ECM" SG_ 1062 MCPA_PIM_DC_Side_Busbar_Temp 0;
BA_ "GenSigTimeoutTime_BPCM" SG_ 1062 MCPA_PIM_DC_Side_Busbar_Temp 0;
BA_ "GenSigTimeoutTime_ECM" SG_ 1062 MCPA_Service_Lamp_Request_2 0;
BA_ "GenSigTimeoutTime_BPCM" SG_ 1062 MCPA_Service_Lamp_Request_2 0;
BA_ "GenSigTimeoutTime_SGCP" SG_ 1062 MCPA_Service_Lamp_Request_2 0;
BA_ "GenSigTimeoutTime_MCPB" SG_ 1062 MCPA_Service_Lamp_Request_2 0;
BA_ "GenSigTimeoutTime_MCPA" SG_ 1062 MCPA_Service_Lamp_Request_2 0;
BA_ "GenSigTimeoutTime_IDCM" SG_ 1062 MCPA_Service_Lamp_Request_2 0;
BA_ "GenSigTimeoutTime_ECM" SG_ 1062 MCPA_Control_Board_Temperature 0;
BA_ "GenSigTimeoutTime_BPCM" SG_ 1062 MCPA_Control_Board_Temperature 0;
BA_ "GenSigStartValue" SG_ 1062 MCPA_Control_Board_Temperature 255;
BA_ "GenSigTimeoutTime_SGCP" SG_ 1062 MCPA_Control_Board_Temperature 0;
BA_ "GenSigTimeoutTime_MCPB" SG_ 1062 MCPA_Control_Board_Temperature 0;
BA_ "GenSigTimeoutTime_MCPA" SG_ 1062 MCPA_Control_Board_Temperature 0;
BA_ "GenSigTimeoutTime_IDCM" SG_ 1062 MCPA_Control_Board_Temperature 0;
BA_ "GenSigTimeoutTime_ECM" SG_ 1062 CLrDiagInfo_MCPA 0;
BA_ "GenSigTimeoutTime_BPCM" SG_ 1062 CLrDiagInfo_MCPA 0;
BA_ "GenSigTimeoutTime_SGCP" SG_ 1062 CLrDiagInfo_MCPA 0;
BA_ "GenSigTimeoutTime_MCPB" SG_ 1062 CLrDiagInfo_MCPA 0;
BA_ "GenSigTimeoutTime_MCPA" SG_ 1062 CLrDiagInfo_MCPA 0;
BA_ "GenSigTimeoutTime_IDCM" SG_ 1062 CLrDiagInfo_MCPA 0;
BA_ "GenSigTimeoutTime_ECM" SG_ 1062 MessageCounter_MCPA_DATA2 0;
BA_ "GenSigTimeoutTime_BPCM" SG_ 1062 MessageCounter_MCPA_DATA2 0;
BA_ "GenSigTimeoutTime_SGCP" SG_ 1062 MessageCounter_MCPA_DATA2 0;
BA_ "GenSigTimeoutTime_MCPB" SG_ 1062 MessageCounter_MCPA_DATA2 0;
BA_ "GenSigTimeoutTime_MCPA" SG_ 1062 MessageCounter_MCPA_DATA2 0;
BA_ "GenSigTimeoutTime_IDCM" SG_ 1062 MessageCounter_MCPA_DATA2 0;
BA_ "GenSigTimeoutTime_ECM" SG_ 1062 CRC_MCPA_DATA2 0;
BA_ "GenSigTimeoutTime_BPCM" SG_ 1062 CRC_MCPA_DATA2 0;
BA_ "GenSigTimeoutTime_SGCP" SG_ 1062 CRC_MCPA_DATA2 0;
BA_ "GenSigTimeoutTime_MCPB" SG_ 1062 CRC_MCPA_DATA2 0;
BA_ "GenSigTimeoutTime_MCPA" SG_ 1062 CRC_MCPA_DATA2 0;
BA_ "GenSigTimeoutTime_IDCM" SG_ 1062 CRC_MCPA_DATA2 0;
BA_ "GenSigTimeoutTime_ECM" SG_ 1062 MCPA_Rotor_Temperature 0;
BA_ "GenSigTimeoutTime_BPCM" SG_ 1062 MCPA_Rotor_Temperature 0;
BA_ "GenSigStartValue" SG_ 1062 MCPA_Rotor_Temperature 255;
BA_ "GenSigTimeoutTime_SGCP" SG_ 1062 MCPA_Rotor_Temperature 0;
BA_ "GenSigTimeoutTime_MCPB" SG_ 1062 MCPA_Rotor_Temperature 0;
BA_ "GenSigTimeoutTime_MCPA" SG_ 1062 MCPA_Rotor_Temperature 0;
BA_ "GenSigTimeoutTime_IDCM" SG_ 1062 MCPA_Rotor_Temperature 0;
BA_ "GenSigTimeoutTime_ECM" SG_ 1062 MCPA_Inverter_Temp 0;
BA_ "GenSigTimeoutTime_BPCM" SG_ 1062 MCPA_Inverter_Temp 0;
BA_ "GenSigStartValue" SG_ 1062 MCPA_Inverter_Temp 40;
BA_ "GenSigTimeoutTime_SGCP" SG_ 1062 MCPA_Inverter_Temp 0;
BA_ "GenSigTimeoutTime_MCPB" SG_ 1062 MCPA_Inverter_Temp 0;
BA_ "GenSigTimeoutTime_MCPA" SG_ 1062 MCPA_Inverter_Temp 0;
BA_ "GenSigTimeoutTime_IDCM" SG_ 1062 MCPA_Inverter_Temp 0;
BA_ "GenSigStartValue" SG_ 1062 MCPA_Temp 40;
BA_ "GenSigTimeoutTime_SGCP" SG_ 1062 MCPA_Temp 0;
BA_ "GenSigTimeoutTime_MCPB" SG_ 1062 MCPA_Temp 0;
BA_ "GenSigTimeoutTime_MCPA" SG_ 1062 MCPA_Temp 0;
BA_ "GenSigTimeoutTime_IDCM" SG_ 1062 MCPA_Temp 0;
BA_ "GenSigTimeoutTime_ECM" SG_ 1062 MCPA_Temp 0;
BA_ "GenSigTimeoutTime_BPCM" SG_ 1062 MCPA_Temp 0;
BA_ "GenSigTimeoutTime_ECM" SG_ 244 ImpactHardwireV 0;
BA_ "GenSigTimeoutTime_BPCM" SG_ 244 ImpactHardwireV 0;
BA_ "GenSigTimeoutTime_SGCP" SG_ 244 ImpactHardwireV 0;
BA_ "GenSigTimeoutTime_ECM" SG_ 244 ImpactHardwire 0;
BA_ "GenSigTimeoutTime_BPCM" SG_ 244 ImpactHardwire 0;
BA_ "GenSigTimeoutTime_SGCP" SG_ 244 ImpactHardwire 0;
BA_ "GenSigTimeoutTime_ECM" SG_ 1790 BMS_HV_SOC_AccuracySts 0;
BA_ "GenSigTimeoutTime_BPCM" SG_ 1790 BMS_HV_SOC_AccuracySts 0;
BA_ "GenSigSendType" SG_ 1790 BMS_HV_SOC_AccuracySts 3;
BA_ "GenSigTimeoutTime_SGCP" SG_ 1790 BMS_HV_SOC_AccuracySts 0;
BA_ "GenSigTimeoutTime_MCPB" SG_ 1790 BMS_HV_SOC_AccuracySts 0;
BA_ "GenSigTimeoutTime_MCPA" SG_ 1790 BMS_HV_SOC_AccuracySts 0;
BA_ "GenSigTimeoutTime_IDCM" SG_ 1790 BMS_HV_SOC_AccuracySts 0;
BA_ "GenSigTimeoutTime_ECM" SG_ 1790 BMS_HV_Low_Temp_Thrsh 0;
BA_ "GenSigTimeoutTime_BPCM" SG_ 1790 BMS_HV_Low_Temp_Thrsh 0;
BA_ "GenSigTimeoutTime_SGCP" SG_ 1790 BMS_HV_Low_Temp_Thrsh 0;
BA_ "GenSigTimeoutTime_MCPB" SG_ 1790 BMS_HV_Low_Temp_Thrsh 0;
BA_ "GenSigTimeoutTime_MCPA" SG_ 1790 BMS_HV_Low_Temp_Thrsh 0;
BA_ "GenSigTimeoutTime_IDCM" SG_ 1790 BMS_HV_Low_Temp_Thrsh 0;
BA_ "GenSigTimeoutTime_ECM" SG_ 1790 BMS_HV_SOC_Min 0;
BA_ "GenSigTimeoutTime_BPCM" SG_ 1790 BMS_HV_SOC_Min 0;
BA_ "GenSigSendType" SG_ 1790 BMS_HV_SOC_Min 3;
BA_ "GenSigStartValue" SG_ 1790 BMS_HV_SOC_Min 50;
BA_ "GenSigTimeoutTime_SGCP" SG_ 1790 BMS_HV_SOC_Min 0;
BA_ "GenSigTimeoutTime_MCPB" SG_ 1790 BMS_HV_SOC_Min 0;
BA_ "GenSigTimeoutTime_MCPA" SG_ 1790 BMS_HV_SOC_Min 0;
BA_ "GenSigTimeoutTime_IDCM" SG_ 1790 BMS_HV_SOC_Min 0;
BA_ "GenSigTimeoutTime_ECM" SG_ 1790 BMS_HV_SOC_Max 0;
BA_ "GenSigTimeoutTime_BPCM" SG_ 1790 BMS_HV_SOC_Max 0;
BA_ "GenSigSendType" SG_ 1790 BMS_HV_SOC_Max 3;
BA_ "GenSigStartValue" SG_ 1790 BMS_HV_SOC_Max 50;
BA_ "GenSigTimeoutTime_SGCP" SG_ 1790 BMS_HV_SOC_Max 0;
BA_ "GenSigTimeoutTime_MCPB" SG_ 1790 BMS_HV_SOC_Max 0;
BA_ "GenSigTimeoutTime_MCPA" SG_ 1790 BMS_HV_SOC_Max 0;
BA_ "GenSigTimeoutTime_IDCM" SG_ 1790 BMS_HV_SOC_Max 0;
BA_ "GenSigTimeoutTime_ECM" SG_ 1790 BMS_HV_High_Temp_Thrsh 0;
BA_ "GenSigTimeoutTime_BPCM" SG_ 1790 BMS_HV_High_Temp_Thrsh 0;
BA_ "GenSigTimeoutTime_SGCP" SG_ 1790 BMS_HV_High_Temp_Thrsh 0;
BA_ "GenSigTimeoutTime_MCPB" SG_ 1790 BMS_HV_High_Temp_Thrsh 0;
BA_ "GenSigTimeoutTime_MCPA" SG_ 1790 BMS_HV_High_Temp_Thrsh 0;
BA_ "GenSigTimeoutTime_IDCM" SG_ 1790 BMS_HV_High_Temp_Thrsh 0;
BA_ "GenSigTimeoutTime_ECM" SG_ 1790 HVBatCell_Voltage_Low_Thrsh 0;
BA_ "GenSigTimeoutTime_BPCM" SG_ 1790 HVBatCell_Voltage_Low_Thrsh 0;
BA_ "GenSigTimeoutTime_SGCP" SG_ 1790 HVBatCell_Voltage_Low_Thrsh 0;
BA_ "GenSigTimeoutTime_MCPB" SG_ 1790 HVBatCell_Voltage_Low_Thrsh 0;
BA_ "GenSigTimeoutTime_MCPA" SG_ 1790 HVBatCell_Voltage_Low_Thrsh 0;
BA_ "GenSigTimeoutTime_IDCM" SG_ 1790 HVBatCell_Voltage_Low_Thrsh 0;
BA_ "GenSigTimeoutTime_ECM" SG_ 1790 HVBatCell_Voltage_High_Thrsh 0;
BA_ "GenSigTimeoutTime_BPCM" SG_ 1790 HVBatCell_Voltage_High_Thrsh 0;
BA_ "GenSigTimeoutTime_SGCP" SG_ 1790 HVBatCell_Voltage_High_Thrsh 0;
BA_ "GenSigTimeoutTime_MCPB" SG_ 1790 HVBatCell_Voltage_High_Thrsh 0;
BA_ "GenSigTimeoutTime_MCPA" SG_ 1790 HVBatCell_Voltage_High_Thrsh 0;
BA_ "GenSigTimeoutTime_IDCM" SG_ 1790 HVBatCell_Voltage_High_Thrsh 0;
BA_ "GenSigTimeoutTime_ECM" SG_ 1790 HEV_OnRq_BPCM 0;
BA_ "GenSigTimeoutTime_BPCM" SG_ 1790 HEV_OnRq_BPCM 0;
BA_ "GenSigSendType" SG_ 1790 HEV_OnRq_BPCM 3;
BA_ "GenSigTimeoutTime_SGCP" SG_ 1790 HEV_OnRq_BPCM 0;
BA_ "GenSigTimeoutTime_MCPB" SG_ 1790 HEV_OnRq_BPCM 0;
BA_ "GenSigTimeoutTime_MCPA" SG_ 1790 HEV_OnRq_BPCM 0;
BA_ "GenSigTimeoutTime_IDCM" SG_ 1790 HEV_OnRq_BPCM 0;
BA_ "GenSigTimeoutTime_ECM" SG_ 2564429297 N_PDU_18DA15F1 0;
BA_ "GenSigTimeoutTime_BPCM" SG_ 2564429297 N_PDU_18DA15F1 0;
BA_ "GenSigTimeoutTime_SGCP" SG_ 2564429297 N_PDU_18DA15F1 0;
BA_ "GenSigTimeoutTime_MCPB" SG_ 2564429297 N_PDU_18DA15F1 0;
BA_ "GenSigTimeoutTime_MCPA" SG_ 2564429297 N_PDU_18DA15F1 0;
BA_ "GenSigTimeoutTime_IDCM" SG_ 2564429297 N_PDU_18DA15F1 0;
BA_ "GenSigTimeoutTime_EVCU2" SG_ 2564429297 N_PDU_18DA15F1 0;
BA_ "GenSigTimeoutTime_ECM" SG_ 2564429041 N_PDU_18DA14F1 0;
BA_ "GenSigTimeoutTime_BPCM" SG_ 2564429041 N_PDU_18DA14F1 0;
BA_ "GenSigTimeoutTime_SGCP" SG_ 2564429041 N_PDU_18DA14F1 0;
BA_ "GenSigTimeoutTime_MCPB" SG_ 2564429041 N_PDU_18DA14F1 0;
BA_ "GenSigTimeoutTime_MCPA" SG_ 2564429041 N_PDU_18DA14F1 0;
BA_ "GenSigTimeoutTime_IDCM" SG_ 2564429041 N_PDU_18DA14F1 0;
BA_ "GenSigTimeoutTime_EVCU2" SG_ 2564429041 N_PDU_18DA14F1 0;
BA_ "GenSigTimeoutTime_ECM" SG_ 2564429298 N_PDU_18DA15F2 0;
BA_ "GenSigTimeoutTime_BPCM" SG_ 2564429298 N_PDU_18DA15F2 0;
BA_ "GenSigTimeoutTime_SGCP" SG_ 2564429298 N_PDU_18DA15F2 0;
BA_ "GenSigTimeoutTime_MCPB" SG_ 2564429298 N_PDU_18DA15F2 0;
BA_ "GenSigTimeoutTime_MCPA" SG_ 2564429298 N_PDU_18DA15F2 0;
BA_ "GenSigTimeoutTime_IDCM" SG_ 2564429298 N_PDU_18DA15F2 0;
BA_ "GenSigTimeoutTime_EVCU2" SG_ 2564429298 N_PDU_18DA15F2 0;
BA_ "GenSigTimeoutTime_ECM" SG_ 2564429042 N_PDU_18DA14F2 0;
BA_ "GenSigTimeoutTime_BPCM" SG_ 2564429042 N_PDU_18DA14F2 0;
BA_ "GenSigTimeoutTime_SGCP" SG_ 2564429042 N_PDU_18DA14F2 0;
BA_ "GenSigTimeoutTime_MCPB" SG_ 2564429042 N_PDU_18DA14F2 0;
BA_ "GenSigTimeoutTime_MCPA" SG_ 2564429042 N_PDU_18DA14F2 0;
BA_ "GenSigTimeoutTime_IDCM" SG_ 2564429042 N_PDU_18DA14F2 0;
BA_ "GenSigTimeoutTime_EVCU2" SG_ 2564429042 N_PDU_18DA14F2 0;
BA_ "GenSigTimeoutTime_IDCM" SG_ 250 APM_UtilPctOfDCDC 0;
BA_ "GenSigTimeoutTime_ECM" SG_ 544 EVSE_NotificationMaxDelay 0;
BA_ "GenSigTimeoutTime_BPCM" SG_ 544 EVSE_NotificationMaxDelay 0;
BA_ "GenSigStartValue" SG_ 544 EVSE_NotificationMaxDelay 1;
BA_ "GenSigTimeoutTime_SGCP" SG_ 544 EVSE_NotificationMaxDelay 0;
BA_ "GenSigTimeoutTime_MCPB" SG_ 544 EVSE_NotificationMaxDelay 0;
BA_ "GenSigTimeoutTime_MCPA" SG_ 544 EVSE_NotificationMaxDelay 0;
BA_ "GenSigTimeoutTime_IDCM" SG_ 544 EVSE_NotificationMaxDelay 0;
BA_ "GenSigTimeoutTime_ECM" SG_ 1031 InputCurrentAvailable 0;
BA_ "GenSigTimeoutTime_BPCM" SG_ 1031 InputCurrentAvailable 0;
BA_ "GenSigTimeoutTime_SGCP" SG_ 1031 InputCurrentAvailable 0;
BA_ "GenSigTimeoutTime_MCPB" SG_ 1031 InputCurrentAvailable 0;
BA_ "GenSigTimeoutTime_MCPA" SG_ 1031 InputCurrentAvailable 0;
BA_ "GenSigTimeoutTime_IDCM" SG_ 1031 InputCurrentAvailable 0;
BA_ "GenSigTimeoutTime_ECM" SG_ 1031 AC_Side_Volt3 0;
BA_ "GenSigTimeoutTime_BPCM" SG_ 1031 AC_Side_Volt3 0;
BA_ "GenSigTimeoutTime_SGCP" SG_ 1031 AC_Side_Volt3 0;
BA_ "GenSigTimeoutTime_MCPB" SG_ 1031 AC_Side_Volt3 0;
BA_ "GenSigTimeoutTime_MCPA" SG_ 1031 AC_Side_Volt3 0;
BA_ "GenSigTimeoutTime_IDCM" SG_ 1031 AC_Side_Volt3 0;
BA_ "GenSigTimeoutTime_ECM" SG_ 1031 AC_Side_Volt2 0;
BA_ "GenSigTimeoutTime_BPCM" SG_ 1031 AC_Side_Volt2 0;
BA_ "GenSigTimeoutTime_SGCP" SG_ 1031 AC_Side_Volt2 0;
BA_ "GenSigTimeoutTime_MCPB" SG_ 1031 AC_Side_Volt2 0;
BA_ "GenSigTimeoutTime_MCPA" SG_ 1031 AC_Side_Volt2 0;
BA_ "GenSigTimeoutTime_IDCM" SG_ 1031 AC_Side_Volt2 0;
BA_ "GenSigTimeoutTime_ECM" SG_ 1031 AC_Side_Volt1 0;
BA_ "GenSigTimeoutTime_BPCM" SG_ 1031 AC_Side_Volt1 0;
BA_ "GenSigTimeoutTime_SGCP" SG_ 1031 AC_Side_Volt1 0;
BA_ "GenSigTimeoutTime_MCPB" SG_ 1031 AC_Side_Volt1 0;
BA_ "GenSigTimeoutTime_MCPA" SG_ 1031 AC_Side_Volt1 0;
BA_ "GenSigTimeoutTime_IDCM" SG_ 1031 AC_Side_Volt1 0;
BA_ "GenSigTimeoutTime_ECM" SG_ 1031 AC_Side_Curr3 0;
BA_ "GenSigTimeoutTime_BPCM" SG_ 1031 AC_Side_Curr3 0;
BA_ "GenSigStartValue" SG_ 1031 AC_Side_Curr3 1000;
BA_ "GenSigTimeoutTime_SGCP" SG_ 1031 AC_Side_Curr3 0;
BA_ "GenSigTimeoutTime_MCPB" SG_ 1031 AC_Side_Curr3 0;
BA_ "GenSigTimeoutTime_MCPA" SG_ 1031 AC_Side_Curr3 0;
BA_ "GenSigTimeoutTime_IDCM" SG_ 1031 AC_Side_Curr3 0;
BA_ "GenSigTimeoutTime_ECM" SG_ 1031 AC_Side_Curr2 0;
BA_ "GenSigTimeoutTime_BPCM" SG_ 1031 AC_Side_Curr2 0;
BA_ "GenSigStartValue" SG_ 1031 AC_Side_Curr2 1000;
BA_ "GenSigTimeoutTime_SGCP" SG_ 1031 AC_Side_Curr2 0;
BA_ "GenSigTimeoutTime_MCPB" SG_ 1031 AC_Side_Curr2 0;
BA_ "GenSigTimeoutTime_MCPA" SG_ 1031 AC_Side_Curr2 0;
BA_ "GenSigTimeoutTime_IDCM" SG_ 1031 AC_Side_Curr2 0;
BA_ "GenSigTimeoutTime_ECM" SG_ 250 APM_Water_Temp 0;
BA_ "GenSigTimeoutTime_BPCM" SG_ 250 APM_Water_Temp 0;
BA_ "GenSigTimeoutTime_SGCP" SG_ 250 APM_Water_Temp 0;
BA_ "GenSigTimeoutTime_MCPB" SG_ 250 APM_Water_Temp 0;
BA_ "GenSigTimeoutTime_MCPA" SG_ 250 APM_Water_Temp 0;
BA_ "GenSigTimeoutTime_IDCM" SG_ 250 APM_Water_Temp 0;
BA_ "GenSigTimeoutTime_ECM" SG_ 250 APM_RecoveryAction 0;
BA_ "GenSigTimeoutTime_BPCM" SG_ 250 APM_RecoveryAction 0;
BA_ "GenSigTimeoutTime_SGCP" SG_ 250 APM_RecoveryAction 0;
BA_ "GenSigTimeoutTime_MCPB" SG_ 250 APM_RecoveryAction 0;
BA_ "GenSigTimeoutTime_MCPA" SG_ 250 APM_RecoveryAction 0;
BA_ "GenSigTimeoutTime_IDCM" SG_ 250 APM_RecoveryAction 0;
BA_ "GenSigTimeoutTime_ECM" SG_ 250 APM_PSFB_Temp2 0;
BA_ "GenSigTimeoutTime_BPCM" SG_ 250 APM_PSFB_Temp2 0;
BA_ "GenSigTimeoutTime_SGCP" SG_ 250 APM_PSFB_Temp2 0;
BA_ "GenSigTimeoutTime_MCPB" SG_ 250 APM_PSFB_Temp2 0;
BA_ "GenSigTimeoutTime_MCPA" SG_ 250 APM_PSFB_Temp2 0;
BA_ "GenSigTimeoutTime_IDCM" SG_ 250 APM_PSFB_Temp2 0;
BA_ "GenSigTimeoutTime_ECM" SG_ 250 APM_PSFB_Temp1 0;
BA_ "GenSigTimeoutTime_BPCM" SG_ 250 APM_PSFB_Temp1 0;
BA_ "GenSigTimeoutTime_SGCP" SG_ 250 APM_PSFB_Temp1 0;
BA_ "GenSigTimeoutTime_MCPB" SG_ 250 APM_PSFB_Temp1 0;
BA_ "GenSigTimeoutTime_MCPA" SG_ 250 APM_PSFB_Temp1 0;
BA_ "GenSigTimeoutTime_IDCM" SG_ 250 APM_PSFB_Temp1 0;
BA_ "GenSigTimeoutTime_ECM" SG_ 250 APM_LV_V_Fbk 0;
BA_ "GenSigTimeoutTime_BPCM" SG_ 250 APM_LV_V_Fbk 0;
BA_ "GenSigTimeoutTime_SGCP" SG_ 250 APM_LV_V_Fbk 0;
BA_ "GenSigTimeoutTime_MCPB" SG_ 250 APM_LV_V_Fbk 0;
BA_ "GenSigTimeoutTime_MCPA" SG_ 250 APM_LV_V_Fbk 0;
BA_ "GenSigTimeoutTime_IDCM" SG_ 250 APM_LV_V_Fbk 0;
BA_ "GenSigTimeoutTime_ECM" SG_ 250 APM_LV_I_Fbk 0;
BA_ "GenSigTimeoutTime_BPCM" SG_ 250 APM_LV_I_Fbk 0;
BA_ "GenSigTimeoutTime_SGCP" SG_ 250 APM_LV_I_Fbk 0;
BA_ "GenSigTimeoutTime_MCPB" SG_ 250 APM_LV_I_Fbk 0;
BA_ "GenSigTimeoutTime_MCPA" SG_ 250 APM_LV_I_Fbk 0;
BA_ "GenSigTimeoutTime_IDCM" SG_ 250 APM_LV_I_Fbk 0;
BA_ "GenSigTimeoutTime_ECM" SG_ 250 APM_HV_V_Fbk 0;
BA_ "GenSigTimeoutTime_BPCM" SG_ 250 APM_HV_V_Fbk 0;
BA_ "GenSigTimeoutTime_SGCP" SG_ 250 APM_HV_V_Fbk 0;
BA_ "GenSigTimeoutTime_MCPB" SG_ 250 APM_HV_V_Fbk 0;
BA_ "GenSigTimeoutTime_MCPA" SG_ 250 APM_HV_V_Fbk 0;
BA_ "GenSigTimeoutTime_IDCM" SG_ 250 APM_HV_V_Fbk 0;
BA_ "GenSigTimeoutTime_ECM" SG_ 250 APM_HV_I_Fbk 0;
BA_ "GenSigTimeoutTime_BPCM" SG_ 250 APM_HV_I_Fbk 0;
BA_ "GenSigTimeoutTime_SGCP" SG_ 250 APM_HV_I_Fbk 0;
BA_ "GenSigTimeoutTime_MCPB" SG_ 250 APM_HV_I_Fbk 0;
BA_ "GenSigTimeoutTime_MCPA" SG_ 250 APM_HV_I_Fbk 0;
BA_ "GenSigTimeoutTime_IDCM" SG_ 250 APM_HV_I_Fbk 0;
BA_ "GenSigTimeoutTime_ECM" SG_ 250 APM_Buck_Temp 0;
BA_ "GenSigTimeoutTime_BPCM" SG_ 250 APM_Buck_Temp 0;
BA_ "GenSigTimeoutTime_SGCP" SG_ 250 APM_Buck_Temp 0;
BA_ "GenSigTimeoutTime_MCPB" SG_ 250 APM_Buck_Temp 0;
BA_ "GenSigTimeoutTime_MCPA" SG_ 250 APM_Buck_Temp 0;
BA_ "GenSigTimeoutTime_IDCM" SG_ 250 APM_Buck_Temp 0;
BA_ "GenSigTimeoutTime_ECM" SG_ 250 CRC_APM_VDCM 0;
BA_ "GenSigTimeoutTime_BPCM" SG_ 250 CRC_APM_VDCM 0;
BA_ "GenSigTimeoutTime_SGCP" SG_ 250 CRC_APM_VDCM 0;
BA_ "GenSigTimeoutTime_MCPB" SG_ 250 CRC_APM_VDCM 0;
BA_ "GenSigTimeoutTime_MCPA" SG_ 250 CRC_APM_VDCM 0;
BA_ "GenSigTimeoutTime_IDCM" SG_ 250 CRC_APM_VDCM 0;
BA_ "GenSigTimeoutTime_ECM" SG_ 250 MessageCounter_APM_VDCM 0;
BA_ "GenSigTimeoutTime_BPCM" SG_ 250 MessageCounter_APM_VDCM 0;
BA_ "GenSigTimeoutTime_SGCP" SG_ 250 MessageCounter_APM_VDCM 0;
BA_ "GenSigTimeoutTime_MCPB" SG_ 250 MessageCounter_APM_VDCM 0;
BA_ "GenSigTimeoutTime_MCPA" SG_ 250 MessageCounter_APM_VDCM 0;
BA_ "GenSigTimeoutTime_IDCM" SG_ 250 MessageCounter_APM_VDCM 0;
BA_ "GenSigTimeoutTime_ECM" SG_ 544 ExtChargerSts 0;
BA_ "GenSigTimeoutTime_BPCM" SG_ 544 ExtChargerSts 0;
BA_ "GenSigStartValue" SG_ 544 ExtChargerSts 2;
BA_ "GenSigTimeoutTime_SGCP" SG_ 544 ExtChargerSts 0;
BA_ "GenSigTimeoutTime_MCPB" SG_ 544 ExtChargerSts 0;
BA_ "GenSigTimeoutTime_MCPA" SG_ 544 ExtChargerSts 0;
BA_ "GenSigTimeoutTime_IDCM" SG_ 544 ExtChargerSts 0;
BA_ "GenSigTimeoutTime_ECM" SG_ 544 EVSE_Error 0;
BA_ "GenSigTimeoutTime_BPCM" SG_ 544 EVSE_Error 0;
BA_ "GenSigStartValue" SG_ 544 EVSE_Error 2;
BA_ "GenSigTimeoutTime_SGCP" SG_ 544 EVSE_Error 0;
BA_ "GenSigTimeoutTime_MCPB" SG_ 544 EVSE_Error 0;
BA_ "GenSigTimeoutTime_MCPA" SG_ 544 EVSE_Error 0;
BA_ "GenSigTimeoutTime_IDCM" SG_ 544 EVSE_Error 0;
BA_ "GenSigTimeoutTime_ECM" SG_ 544 EVSE_ChrgStopControl 0;
BA_ "GenSigTimeoutTime_BPCM" SG_ 544 EVSE_ChrgStopControl 0;
BA_ "GenSigStartValue" SG_ 544 EVSE_ChrgStopControl 2;
BA_ "GenSigTimeoutTime_SGCP" SG_ 544 EVSE_ChrgStopControl 0;
BA_ "GenSigTimeoutTime_MCPB" SG_ 544 EVSE_ChrgStopControl 0;
BA_ "GenSigTimeoutTime_MCPA" SG_ 544 EVSE_ChrgStopControl 0;
BA_ "GenSigTimeoutTime_IDCM" SG_ 544 EVSE_ChrgStopControl 0;
BA_ "GenSigTimeoutTime_ECM" SG_ 544 Charger_WeldingDetectAvail 0;
BA_ "GenSigTimeoutTime_BPCM" SG_ 544 Charger_WeldingDetectAvail 0;
BA_ "GenSigStartValue" SG_ 544 Charger_WeldingDetectAvail 2;
BA_ "GenSigTimeoutTime_SGCP" SG_ 544 Charger_WeldingDetectAvail 0;
BA_ "GenSigTimeoutTime_MCPB" SG_ 544 Charger_WeldingDetectAvail 0;
BA_ "GenSigTimeoutTime_MCPA" SG_ 544 Charger_WeldingDetectAvail 0;
BA_ "GenSigTimeoutTime_IDCM" SG_ 544 Charger_WeldingDetectAvail 0;
BA_ "GenSigTimeoutTime_ECM" SG_ 544 Plug_Locked_by_EVSE 0;
BA_ "GenSigTimeoutTime_BPCM" SG_ 544 Plug_Locked_by_EVSE 0;
BA_ "GenSigStartValue" SG_ 544 Plug_Locked_by_EVSE 2;
BA_ "GenSigTimeoutTime_SGCP" SG_ 544 Plug_Locked_by_EVSE 0;
BA_ "GenSigTimeoutTime_MCPB" SG_ 544 Plug_Locked_by_EVSE 0;
BA_ "GenSigTimeoutTime_MCPA" SG_ 544 Plug_Locked_by_EVSE 0;
BA_ "GenSigTimeoutTime_IDCM" SG_ 544 Plug_Locked_by_EVSE 0;
BA_ "GenSigTimeoutTime_ECM" SG_ 544 HVCMS_EVSEID 0;
BA_ "GenSigTimeoutTime_BPCM" SG_ 544 HVCMS_EVSEID 0;
BA_ "GenSigTimeoutTime_SGCP" SG_ 544 HVCMS_EVSEID 0;
BA_ "GenSigTimeoutTime_MCPB" SG_ 544 HVCMS_EVSEID 0;
BA_ "GenSigTimeoutTime_MCPA" SG_ 544 HVCMS_EVSEID 0;
BA_ "GenSigTimeoutTime_IDCM" SG_ 544 HVCMS_EVSEID 0;
BA_ "GenSigTimeoutTime_ECM" SG_ 544 Charger_StndbyReqReason 0;
BA_ "GenSigTimeoutTime_BPCM" SG_ 544 Charger_StndbyReqReason 0;
BA_ "GenSigStartValue" SG_ 544 Charger_StndbyReqReason 6;
BA_ "GenSigTimeoutTime_SGCP" SG_ 544 Charger_StndbyReqReason 0;
BA_ "GenSigTimeoutTime_MCPB" SG_ 544 Charger_StndbyReqReason 0;
BA_ "GenSigTimeoutTime_MCPA" SG_ 544 Charger_StndbyReqReason 0;
BA_ "GenSigTimeoutTime_IDCM" SG_ 544 Charger_StndbyReqReason 0;
BA_ "GenSigTimeoutTime_ECM" SG_ 544 Charger_StndbyReq 0;
BA_ "GenSigTimeoutTime_BPCM" SG_ 544 Charger_StndbyReq 0;
BA_ "GenSigStartValue" SG_ 544 Charger_StndbyReq 2;
BA_ "GenSigTimeoutTime_SGCP" SG_ 544 Charger_StndbyReq 0;
BA_ "GenSigTimeoutTime_MCPB" SG_ 544 Charger_StndbyReq 0;
BA_ "GenSigTimeoutTime_MCPA" SG_ 544 Charger_StndbyReq 0;
BA_ "GenSigTimeoutTime_IDCM" SG_ 544 Charger_StndbyReq 0;
BA_ "GenSigTimeoutTime_ECM" SG_ 544 Charger_FaultStates 0;
BA_ "GenSigTimeoutTime_BPCM" SG_ 544 Charger_FaultStates 0;
BA_ "GenSigStartValue" SG_ 544 Charger_FaultStates 14;
BA_ "GenSigTimeoutTime_SGCP" SG_ 544 Charger_FaultStates 0;
BA_ "GenSigTimeoutTime_MCPB" SG_ 544 Charger_FaultStates 0;
BA_ "GenSigTimeoutTime_MCPA" SG_ 544 Charger_FaultStates 0;
BA_ "GenSigTimeoutTime_IDCM" SG_ 544 Charger_FaultStates 0;
BA_ "GenSigTimeoutTime_ECM" SG_ 544 OBCM_CP3Sts 0;
BA_ "GenSigTimeoutTime_BPCM" SG_ 544 OBCM_CP3Sts 0;
BA_ "GenSigTimeoutTime_SGCP" SG_ 544 OBCM_CP3Sts 0;
BA_ "GenSigTimeoutTime_MCPB" SG_ 544 OBCM_CP3Sts 0;
BA_ "GenSigTimeoutTime_MCPA" SG_ 544 OBCM_CP3Sts 0;
BA_ "GenSigTimeoutTime_IDCM" SG_ 544 OBCM_CP3Sts 0;
BA_ "GenSigTimeoutTime_ECM" SG_ 544 TCP_Communication_Terminated 0;
BA_ "GenSigTimeoutTime_BPCM" SG_ 544 TCP_Communication_Terminated 0;
BA_ "GenSigTimeoutTime_ECM" SG_ 544 OBCM_CSSts 0;
BA_ "GenSigTimeoutTime_BPCM" SG_ 544 OBCM_CSSts 0;
BA_ "GenSigTimeoutTime_SGCP" SG_ 544 OBCM_CSSts 0;
BA_ "GenSigTimeoutTime_MCPB" SG_ 544 OBCM_CSSts 0;
BA_ "GenSigTimeoutTime_ECM" SG_ 544 OBCM_CP2Sts 0;
BA_ "GenSigTimeoutTime_BPCM" SG_ 544 OBCM_CP2Sts 0;
BA_ "GenSigTimeoutTime_SGCP" SG_ 544 OBCM_CP2Sts 0;
BA_ "GenSigTimeoutTime_MCPB" SG_ 544 OBCM_CP2Sts 0;
BA_ "GenSigTimeoutTime_MCPA" SG_ 544 OBCM_CP2Sts 0;
BA_ "GenSigTimeoutTime_IDCM" SG_ 544 OBCM_CP2Sts 0;
BA_ "GenSigTimeoutTime_ECM" SG_ 544 OBCM_CCSts 0;
BA_ "GenSigTimeoutTime_BPCM" SG_ 544 OBCM_CCSts 0;
BA_ "GenSigTimeoutTime_SGCP" SG_ 544 OBCM_CCSts 0;
BA_ "GenSigTimeoutTime_MCPB" SG_ 544 OBCM_CCSts 0;
BA_ "GenSigTimeoutTime_MCPA" SG_ 544 OBCM_CCSts 0;
BA_ "GenSigTimeoutTime_IDCM" SG_ 544 OBCM_CCSts 0;
BA_ "GenSigTimeoutTime_SGCP" SG_ 544 OBCM_APAMSts 0;
BA_ "GenSigTimeoutTime_MCPB" SG_ 544 OBCM_APAMSts 0;
BA_ "GenSigTimeoutTime_MCPA" SG_ 544 OBCM_APAMSts 0;
BA_ "GenSigTimeoutTime_IDCM" SG_ 544 OBCM_APAMSts 0;
BA_ "GenSigTimeoutTime_ECM" SG_ 544 OBCM_APAMSts 0;
BA_ "GenSigTimeoutTime_BPCM" SG_ 544 OBCM_APAMSts 0;
BA_ "GenSigTimeoutTime_ECM" SG_ 300 TorqueCommand_MCPB 0;
BA_ "GenSigTimeoutTime_BPCM" SG_ 300 TorqueCommand_MCPB 0;
BA_ "GenSigStartValue" SG_ 300 TorqueCommand_MCPB 4096;
BA_ "GenSigTimeoutTime_SGCP" SG_ 300 TorqueCommand_MCPB 0;
BA_ "GenSigTimeoutTime_MCPA" SG_ 300 TorqueCommand_MCPB 0;
BA_ "GenSigTimeoutTime_IDCM" SG_ 300 TorqueCommand_MCPB 0;
BA_ "GenSigTimeoutTime_EVCU2" SG_ 300 TorqueCommand_MCPB 0;
BA_ "GenSigTimeoutTime_ECM" SG_ 300 TorqueCommand_MCPA 0;
BA_ "GenSigTimeoutTime_BPCM" SG_ 300 TorqueCommand_MCPA 0;
BA_ "GenSigStartValue" SG_ 300 TorqueCommand_MCPA 4096;
BA_ "GenSigTimeoutTime_SGCP" SG_ 300 TorqueCommand_MCPA 0;
BA_ "GenSigTimeoutTime_MCPB" SG_ 300 TorqueCommand_MCPA 0;
BA_ "GenSigTimeoutTime_IDCM" SG_ 300 TorqueCommand_MCPA 0;
BA_ "GenSigTimeoutTime_EVCU2" SG_ 300 TorqueCommand_MCPA 0;
BA_ "GenSigTimeoutTime_ECM" SG_ 300 TargetMotorRPM_MCPB 0;
BA_ "GenSigTimeoutTime_BPCM" SG_ 300 TargetMotorRPM_MCPB 0;
BA_ "GenSigStartValue" SG_ 300 TargetMotorRPM_MCPB 32768;
BA_ "GenSigTimeoutTime_SGCP" SG_ 300 TargetMotorRPM_MCPB 0;
BA_ "GenSigTimeoutTime_MCPA" SG_ 300 TargetMotorRPM_MCPB 0;
BA_ "GenSigTimeoutTime_IDCM" SG_ 300 TargetMotorRPM_MCPB 0;
BA_ "GenSigTimeoutTime_EVCU2" SG_ 300 TargetMotorRPM_MCPB 0;
BA_ "GenSigTimeoutTime_ECM" SG_ 300 TargetMotorRPM_MCPA 0;
BA_ "GenSigTimeoutTime_BPCM" SG_ 300 TargetMotorRPM_MCPA 0;
BA_ "GenSigStartValue" SG_ 300 TargetMotorRPM_MCPA 32768;
BA_ "GenSigTimeoutTime_SGCP" SG_ 300 TargetMotorRPM_MCPA 0;
BA_ "GenSigTimeoutTime_MCPB" SG_ 300 TargetMotorRPM_MCPA 0;
BA_ "GenSigTimeoutTime_IDCM" SG_ 300 TargetMotorRPM_MCPA 0;
BA_ "GenSigTimeoutTime_EVCU2" SG_ 300 TargetMotorRPM_MCPA 0;
BA_ "GenSigTimeoutTime_ECM" SG_ 300 SpdGrdtLim_MCPB 0;
BA_ "GenSigTimeoutTime_BPCM" SG_ 300 SpdGrdtLim_MCPB 0;
BA_ "GenSigTimeoutTime_SGCP" SG_ 300 SpdGrdtLim_MCPB 0;
BA_ "GenSigTimeoutTime_MCPA" SG_ 300 SpdGrdtLim_MCPB 0;
BA_ "GenSigTimeoutTime_IDCM" SG_ 300 SpdGrdtLim_MCPB 0;
BA_ "GenSigTimeoutTime_EVCU2" SG_ 300 SpdGrdtLim_MCPB 0;
BA_ "GenSigTimeoutTime_ECM" SG_ 300 SpdGrdtLim_MCPA 0;
BA_ "GenSigTimeoutTime_BPCM" SG_ 300 SpdGrdtLim_MCPA 0;
BA_ "GenSigTimeoutTime_SGCP" SG_ 300 SpdGrdtLim_MCPA 0;
BA_ "GenSigTimeoutTime_MCPB" SG_ 300 SpdGrdtLim_MCPA 0;
BA_ "GenSigTimeoutTime_IDCM" SG_ 300 SpdGrdtLim_MCPA 0;
BA_ "GenSigTimeoutTime_EVCU2" SG_ 300 SpdGrdtLim_MCPA 0;
BA_ "GenSigTimeoutTime_ECM" SG_ 300 Mtr_6SO_Request_MCPB 0;
BA_ "GenSigTimeoutTime_BPCM" SG_ 300 Mtr_6SO_Request_MCPB 0;
BA_ "GenSigTimeoutTime_SGCP" SG_ 300 Mtr_6SO_Request_MCPB 0;
BA_ "GenSigTimeoutTime_MCPA" SG_ 300 Mtr_6SO_Request_MCPB 0;
BA_ "GenSigTimeoutTime_IDCM" SG_ 300 Mtr_6SO_Request_MCPB 0;
BA_ "GenSigTimeoutTime_EVCU2" SG_ 300 Mtr_6SO_Request_MCPB 0;
BA_ "GenSigTimeoutTime_ECM" SG_ 300 Mtr_6SO_Request_MCPA 0;
BA_ "GenSigTimeoutTime_BPCM" SG_ 300 Mtr_6SO_Request_MCPA 0;
BA_ "GenSigTimeoutTime_ECM" SG_ 300 UDCMax_Unlim_MCPB 0;
BA_ "GenSigTimeoutTime_BPCM" SG_ 300 UDCMax_Unlim_MCPB 0;
BA_ "GenSigTimeoutTime_SGCP" SG_ 300 UDCMax_Unlim_MCPB 0;
BA_ "GenSigTimeoutTime_MCPA" SG_ 300 UDCMax_Unlim_MCPB 0;
BA_ "GenSigTimeoutTime_IDCM" SG_ 300 UDCMax_Unlim_MCPB 0;
BA_ "GenSigTimeoutTime_EVCU2" SG_ 300 UDCMax_Unlim_MCPB 0;
BA_ "GenSigTimeoutTime_ECM" SG_ 300 TqGrdtLim_MCPB 0;
BA_ "GenSigTimeoutTime_BPCM" SG_ 300 TqGrdtLim_MCPB 0;
BA_ "GenSigTimeoutTime_SGCP" SG_ 300 TqGrdtLim_MCPB 0;
BA_ "GenSigTimeoutTime_MCPA" SG_ 300 TqGrdtLim_MCPB 0;
BA_ "GenSigTimeoutTime_IDCM" SG_ 300 TqGrdtLim_MCPB 0;
BA_ "GenSigTimeoutTime_EVCU2" SG_ 300 TqGrdtLim_MCPB 0;
BA_ "GenSigTimeoutTime_ECM" SG_ 300 TqGrdtLim_MCPA 0;
BA_ "GenSigTimeoutTime_BPCM" SG_ 300 TqGrdtLim_MCPA 0;
BA_ "GenSigTimeoutTime_SGCP" SG_ 300 TqGrdtLim_MCPA 0;
BA_ "GenSigTimeoutTime_MCPB" SG_ 300 TqGrdtLim_MCPA 0;
BA_ "GenSigTimeoutTime_IDCM" SG_ 300 TqGrdtLim_MCPA 0;
BA_ "GenSigTimeoutTime_EVCU2" SG_ 300 TqGrdtLim_MCPA 0;
BA_ "GenSigTimeoutTime_ECM" SG_ 300 UDCMax_Unlim_MCPA 0;
BA_ "GenSigTimeoutTime_BPCM" SG_ 300 UDCMax_Unlim_MCPA 0;
BA_ "GenSigTimeoutTime_SGCP" SG_ 300 UDCMax_Unlim_MCPA 0;
BA_ "GenSigTimeoutTime_MCPB" SG_ 300 UDCMax_Unlim_MCPA 0;
BA_ "GenSigTimeoutTime_IDCM" SG_ 300 UDCMax_Unlim_MCPA 0;
BA_ "GenSigTimeoutTime_EVCU2" SG_ 300 UDCMax_Unlim_MCPA 0;
BA_ "GenSigTimeoutTime_ECM" SG_ 105 T4_Sensor_Temp 0;
BA_ "GenSigTimeoutTime_BPCM" SG_ 105 T4_Sensor_Temp 0;
BA_ "GenSigSendType" SG_ 105 T4_Sensor_Temp 3;
BA_ "GenSigTimeoutTime_IDCM" SG_ 105 T4_Sensor_Temp 0;
BA_ "GenSigTimeoutTime_EVCU2" SG_ 105 T4_Sensor_Temp 0;
BA_ "GenSigTimeoutTime_IDCM" SG_ 105 T7_Sensor_Temp 0;
BA_ "GenSigTimeoutTime_EVCU2" SG_ 105 T7_Sensor_Temp 0;
BA_ "GenSigTimeoutTime_ECM" SG_ 105 T7_Sensor_Temp 0;
BA_ "GenSigTimeoutTime_BPCM" SG_ 105 T7_Sensor_Temp 0;
BA_ "GenSigSendType" SG_ 105 T7_Sensor_Temp 3;
BA_ "GenSigTimeoutTime_ECM" SG_ 105 PwrElecSnsr_TEMP 0;
BA_ "GenSigTimeoutTime_BPCM" SG_ 105 PwrElecSnsr_TEMP 0;
BA_ "GenSigStartValue" SG_ 105 PwrElecSnsr_TEMP 255;
BA_ "GenSigTimeoutTime_MCPB" SG_ 105 PwrElecSnsr_TEMP 0;
BA_ "GenSigTimeoutTime_MCPA" SG_ 105 PwrElecSnsr_TEMP 0;
BA_ "GenSigTimeoutTime_IDCM" SG_ 105 PwrElecSnsr_TEMP 0;
BA_ "GenSigTimeoutTime_EVCU2" SG_ 105 PwrElecSnsr_TEMP 0;
BA_ "GenSigTimeoutTime_ECM" SG_ 105 PwrElecPmp_TEMP 0;
BA_ "GenSigTimeoutTime_ECM" SG_ 300 AEMD_Cutoff_FreqLow_MCPA 0;
BA_ "GenSigTimeoutTime_BPCM" SG_ 300 AEMD_Cutoff_FreqLow_MCPA 0;
BA_ "GenSigTimeoutTime_SGCP" SG_ 300 Mtr_6SO_Request_MCPA 0;
BA_ "GenSigTimeoutTime_MCPB" SG_ 300 Mtr_6SO_Request_MCPA 0;
BA_ "GenSigTimeoutTime_IDCM" SG_ 300 Mtr_6SO_Request_MCPA 0;
BA_ "GenSigTimeoutTime_EVCU2" SG_ 300 Mtr_6SO_Request_MCPA 0;
BA_ "GenSigTimeoutTime_ECM" SG_ 300 Pwr_Elec_Loop_FlwRate_MC 0;
BA_ "GenSigTimeoutTime_BPCM" SG_ 300 Pwr_Elec_Loop_FlwRate_MC 0;
BA_ "SystemSignalLongSymbol" SG_ 300 Pwr_Elec_Loop_FlwRate_MC "Pwr_Electronics_Loop_FlwRate_MCPB";
BA_ "GenSigTimeoutTime_SGCP" SG_ 300 Pwr_Elec_Loop_FlwRate_MC 0;
BA_ "GenSigTimeoutTime_MCPA" SG_ 300 Pwr_Elec_Loop_FlwRate_MC 0;
BA_ "GenSigTimeoutTime_IDCM" SG_ 300 Pwr_Elec_Loop_FlwRate_MC 0;
BA_ "GenSigTimeoutTime_EVCU2" SG_ 300 Pwr_Elec_Loop_FlwRate_MC 0;
BA_ "GenSigTimeoutTime_ECM" SG_ 300 Pwr_Electronics_Loop_FlwRate_MC 0;
BA_ "GenSigTimeoutTime_BPCM" SG_ 300 Pwr_Electronics_Loop_FlwRate_MC 0;
BA_ "SystemSignalLongSymbol" SG_ 300 Pwr_Electronics_Loop_FlwRate_MC "Pwr_Electronics_Loop_FlwRate_MCPA";
BA_ "GenSigTimeoutTime_SGCP" SG_ 300 Pwr_Electronics_Loop_FlwRate_MC 0;
BA_ "GenSigTimeoutTime_MCPB" SG_ 300 Pwr_Electronics_Loop_FlwRate_MC 0;
BA_ "GenSigTimeoutTime_IDCM" SG_ 300 Pwr_Electronics_Loop_FlwRate_MC 0;
BA_ "GenSigTimeoutTime_EVCU2" SG_ 300 Pwr_Electronics_Loop_FlwRate_MC 0;
BA_ "GenSigTimeoutTime_ECM" SG_ 300 AEMD_Cutoff_FreqLow_MCPB 0;
BA_ "GenSigTimeoutTime_BPCM" SG_ 300 AEMD_Cutoff_FreqLow_MCPB 0;
BA_ "GenSigTimeoutTime_SGCP" SG_ 300 AEMD_Cutoff_FreqLow_MCPB 0;
BA_ "GenSigTimeoutTime_MCPA" SG_ 300 AEMD_Cutoff_FreqLow_MCPB 0;
BA_ "GenSigTimeoutTime_IDCM" SG_ 300 AEMD_Cutoff_FreqLow_MCPB 0;
BA_ "GenSigTimeoutTime_EVCU2" SG_ 300 AEMD_Cutoff_FreqLow_MCPB 0;
BA_ "GenSigTimeoutTime_ECM" SG_ 300 AEMD_Sclr_Gn_MCPB 0;
BA_ "GenSigTimeoutTime_BPCM" SG_ 300 AEMD_Sclr_Gn_MCPB 0;
BA_ "GenSigTimeoutTime_SGCP" SG_ 300 AEMD_Sclr_Gn_MCPB 0;
BA_ "GenSigTimeoutTime_MCPA" SG_ 300 AEMD_Sclr_Gn_MCPB 0;
BA_ "GenSigTimeoutTime_IDCM" SG_ 300 AEMD_Sclr_Gn_MCPB 0;
BA_ "GenSigTimeoutTime_EVCU2" SG_ 300 AEMD_Sclr_Gn_MCPB 0;
BA_ "GenSigTimeoutTime_ECM" SG_ 300 AEMD_Sclr_Gn_MCPA 0;
BA_ "GenSigTimeoutTime_BPCM" SG_ 300 AEMD_Sclr_Gn_MCPA 0;
BA_ "GenSigTimeoutTime_SGCP" SG_ 300 AEMD_Sclr_Gn_MCPA 0;
BA_ "GenSigTimeoutTime_MCPB" SG_ 300 AEMD_Sclr_Gn_MCPA 0;
BA_ "GenSigTimeoutTime_IDCM" SG_ 300 AEMD_Sclr_Gn_MCPA 0;
BA_ "GenSigTimeoutTime_EVCU2" SG_ 300 AEMD_Sclr_Gn_MCPA 0;
BA_ "GenSigTimeoutTime_ECM" SG_ 300 AEMD_Cutoff_FreqHigh_MCPB 0;
BA_ "GenSigTimeoutTime_BPCM" SG_ 300 AEMD_Cutoff_FreqHigh_MCPB 0;
BA_ "GenSigTimeoutTime_SGCP" SG_ 300 AEMD_Cutoff_FreqHigh_MCPB 0;
BA_ "GenSigTimeoutTime_MCPA" SG_ 300 AEMD_Cutoff_FreqHigh_MCPB 0;
BA_ "GenSigTimeoutTime_IDCM" SG_ 300 AEMD_Cutoff_FreqHigh_MCPB 0;
BA_ "GenSigTimeoutTime_EVCU2" SG_ 300 AEMD_Cutoff_FreqHigh_MCPB 0;
BA_ "GenSigTimeoutTime_ECM" SG_ 300 AEMD_Cutoff_FreqHigh_MCPA 0;
BA_ "GenSigTimeoutTime_BPCM" SG_ 300 AEMD_Cutoff_FreqHigh_MCPA 0;
BA_ "GenSigTimeoutTime_SGCP" SG_ 300 AEMD_Cutoff_FreqHigh_MCPA 0;
BA_ "GenSigTimeoutTime_MCPB" SG_ 300 AEMD_Cutoff_FreqHigh_MCPA 0;
BA_ "GenSigTimeoutTime_IDCM" SG_ 300 AEMD_Cutoff_FreqHigh_MCPA 0;
BA_ "GenSigTimeoutTime_EVCU2" SG_ 300 AEMD_Cutoff_FreqHigh_MCPA 0;
BA_ "GenSigTimeoutTime_ECM" SG_ 300 ModeCommand_MCPB 0;
BA_ "GenSigTimeoutTime_BPCM" SG_ 300 ModeCommand_MCPB 0;
BA_ "GenSigTimeoutTime_SGCP" SG_ 300 ModeCommand_MCPB 0;
BA_ "GenSigTimeoutTime_MCPA" SG_ 300 ModeCommand_MCPB 0;
BA_ "GenSigTimeoutTime_IDCM" SG_ 300 ModeCommand_MCPB 0;
BA_ "GenSigTimeoutTime_EVCU2" SG_ 300 ModeCommand_MCPB 0;
BA_ "GenSigTimeoutTime_ECM" SG_ 300 ModeCommand_MCPA 0;
BA_ "GenSigTimeoutTime_BPCM" SG_ 300 ModeCommand_MCPA 0;
BA_ "GenSigTimeoutTime_SGCP" SG_ 300 ModeCommand_MCPA 0;
BA_ "GenSigTimeoutTime_MCPB" SG_ 300 ModeCommand_MCPA 0;
BA_ "GenSigTimeoutTime_IDCM" SG_ 300 ModeCommand_MCPA 0;
BA_ "GenSigTimeoutTime_EVCU2" SG_ 300 ModeCommand_MCPA 0;
BA_ "GenSigTimeoutTime_ECM" SG_ 300 MessageCounter_INVTARGET1 0;
BA_ "GenSigTimeoutTime_BPCM" SG_ 300 MessageCounter_INVTARGET1 0;
BA_ "GenSigTimeoutTime_IDCM" SG_ 300 MessageCounter_INVTARGET1 0;
BA_ "GenSigTimeoutTime_EVCU2" SG_ 300 MessageCounter_INVTARGET1 0;
BA_ "GenSigTimeoutTime_ECM" SG_ 300 CRC_INVTARGET1 0;
BA_ "GenSigTimeoutTime_BPCM" SG_ 300 CRC_INVTARGET1 0;
BA_ "GenSigTimeoutTime_IDCM" SG_ 300 CRC_INVTARGET1 0;
BA_ "GenSigTimeoutTime_EVCU2" SG_ 300 CRC_INVTARGET1 0;
BA_ "GenSigTimeoutTime_ECM" SG_ 300 AEMD_MinOffset_MCPB 0;
BA_ "GenSigTimeoutTime_BPCM" SG_ 300 AEMD_MinOffset_MCPB 0;
BA_ "GenSigStartValue" SG_ 300 AEMD_MinOffset_MCPB 4095;
BA_ "GenSigTimeoutTime_SGCP" SG_ 300 AEMD_MinOffset_MCPB 0;
BA_ "GenSigTimeoutTime_MCPA" SG_ 300 AEMD_MinOffset_MCPB 0;
BA_ "GenSigTimeoutTime_IDCM" SG_ 300 AEMD_MinOffset_MCPB 0;
BA_ "GenSigTimeoutTime_EVCU2" SG_ 300 AEMD_MinOffset_MCPB 0;
BA_ "GenSigTimeoutTime_ECM" SG_ 300 AEMD_MinOffset_MCPA 0;
BA_ "GenSigTimeoutTime_BPCM" SG_ 300 AEMD_MinOffset_MCPA 0;
BA_ "GenSigStartValue" SG_ 300 AEMD_MinOffset_MCPA 4095;
BA_ "GenSigTimeoutTime_SGCP" SG_ 300 AEMD_MinOffset_MCPA 0;
BA_ "GenSigTimeoutTime_MCPB" SG_ 300 AEMD_MinOffset_MCPA 0;
BA_ "GenSigTimeoutTime_IDCM" SG_ 300 AEMD_MinOffset_MCPA 0;
BA_ "GenSigTimeoutTime_EVCU2" SG_ 300 AEMD_MinOffset_MCPA 0;
BA_ "GenSigTimeoutTime_ECM" SG_ 300 AEMD_MaxOffset_MCPB 0;
BA_ "GenSigTimeoutTime_BPCM" SG_ 300 AEMD_MaxOffset_MCPB 0;
BA_ "GenSigTimeoutTime_SGCP" SG_ 300 AEMD_MaxOffset_MCPB 0;
BA_ "GenSigTimeoutTime_MCPA" SG_ 300 AEMD_MaxOffset_MCPB 0;
BA_ "GenSigTimeoutTime_IDCM" SG_ 300 AEMD_MaxOffset_MCPB 0;
BA_ "GenSigTimeoutTime_EVCU2" SG_ 300 AEMD_MaxOffset_MCPB 0;
BA_ "GenSigTimeoutTime_ECM" SG_ 300 AEMD_MaxOffset_MCPA 0;
BA_ "GenSigTimeoutTime_BPCM" SG_ 300 AEMD_MaxOffset_MCPA 0;
BA_ "GenSigTimeoutTime_SGCP" SG_ 300 AEMD_MaxOffset_MCPA 0;
BA_ "GenSigTimeoutTime_MCPB" SG_ 300 AEMD_MaxOffset_MCPA 0;
BA_ "GenSigTimeoutTime_IDCM" SG_ 300 AEMD_MaxOffset_MCPA 0;
BA_ "GenSigTimeoutTime_EVCU2" SG_ 300 AEMD_MaxOffset_MCPA 0;
BA_ "GenSigTimeoutTime_ECM" SG_ 250 APM_FailureType 0;
BA_ "GenSigTimeoutTime_BPCM" SG_ 250 APM_FailureType 0;
BA_ "GenSigTimeoutTime_SGCP" SG_ 250 APM_FailureType 0;
BA_ "GenSigTimeoutTime_MCPB" SG_ 250 APM_FailureType 0;
BA_ "GenSigTimeoutTime_MCPA" SG_ 250 APM_FailureType 0;
BA_ "GenSigTimeoutTime_IDCM" SG_ 250 APM_FailureType 0;
BA_ "GenSigTimeoutTime_ECM" SG_ 250 APM_FailureReason 0;
BA_ "GenSigTimeoutTime_BPCM" SG_ 250 APM_FailureReason 0;
BA_ "GenSigTimeoutTime_SGCP" SG_ 250 APM_FailureReason 0;
BA_ "GenSigTimeoutTime_MCPB" SG_ 250 APM_FailureReason 0;
BA_ "GenSigTimeoutTime_MCPA" SG_ 250 APM_FailureReason 0;
BA_ "GenSigTimeoutTime_IDCM" SG_ 250 APM_FailureReason 0;
BA_ "GenSigTimeoutTime_ECM" SG_ 250 APM_EstPwrLoss 0;
BA_ "GenSigTimeoutTime_BPCM" SG_ 250 APM_EstPwrLoss 0;
BA_ "GenSigTimeoutTime_SGCP" SG_ 250 APM_EstPwrLoss 0;
BA_ "GenSigTimeoutTime_MCPB" SG_ 250 APM_EstPwrLoss 0;
BA_ "GenSigTimeoutTime_MCPA" SG_ 250 APM_EstPwrLoss 0;
BA_ "GenSigTimeoutTime_IDCM" SG_ 250 APM_EstPwrLoss 0;
BA_ "GenSigTimeoutTime_ECM" SG_ 250 APM_DeratingReason 0;
BA_ "GenSigTimeoutTime_BPCM" SG_ 250 APM_DeratingReason 0;
BA_ "GenSigTimeoutTime_SGCP" SG_ 250 APM_DeratingReason 0;
BA_ "GenSigTimeoutTime_MCPB" SG_ 250 APM_DeratingReason 0;
BA_ "GenSigTimeoutTime_MCPA" SG_ 250 APM_DeratingReason 0;
BA_ "GenSigTimeoutTime_IDCM" SG_ 250 APM_DeratingReason 0;
BA_ "GenSigTimeoutTime_ECM" SG_ 250 APM_DeratingPower 0;
BA_ "GenSigTimeoutTime_BPCM" SG_ 250 APM_DeratingPower 0;
BA_ "GenSigTimeoutTime_SGCP" SG_ 250 APM_DeratingPower 0;
BA_ "GenSigTimeoutTime_MCPB" SG_ 250 APM_DeratingPower 0;
BA_ "GenSigTimeoutTime_MCPA" SG_ 250 APM_DeratingPower 0;
BA_ "GenSigTimeoutTime_IDCM" SG_ 250 APM_DeratingPower 0;
BA_ "GenSigTimeoutTime_ECM" SG_ 250 APM_UtilPctOfDCDC 0;
BA_ "GenSigTimeoutTime_BPCM" SG_ 250 APM_UtilPctOfDCDC 0;
BA_ "GenSigTimeoutTime_SGCP" SG_ 250 APM_UtilPctOfDCDC 0;
BA_ "GenSigTimeoutTime_MCPB" SG_ 250 APM_UtilPctOfDCDC 0;
BA_ "GenSigTimeoutTime_MCPA" SG_ 250 APM_UtilPctOfDCDC 0;
BA_ "GenSigTimeoutTime_ECM" SG_ 250 APM_TempColdPlate 0;
BA_ "GenSigTimeoutTime_BPCM" SG_ 250 APM_TempColdPlate 0;
BA_ "GenSigStartValue" SG_ 250 APM_TempColdPlate 25;
BA_ "GenSigTimeoutTime_SGCP" SG_ 250 APM_TempColdPlate 0;
BA_ "GenSigTimeoutTime_MCPB" SG_ 250 APM_TempColdPlate 0;
BA_ "GenSigTimeoutTime_MCPA" SG_ 250 APM_TempColdPlate 0;
BA_ "GenSigTimeoutTime_IDCM" SG_ 250 APM_TempColdPlate 0;
BA_ "GenSigTimeoutTime_ECM" SG_ 250 APM_PowerLimitMode 0;
BA_ "GenSigTimeoutTime_BPCM" SG_ 250 APM_PowerLimitMode 0;
BA_ "GenSigTimeoutTime_SGCP" SG_ 250 APM_PowerLimitMode 0;
BA_ "GenSigTimeoutTime_MCPB" SG_ 250 APM_PowerLimitMode 0;
BA_ "GenSigTimeoutTime_MCPA" SG_ 250 APM_PowerLimitMode 0;
BA_ "GenSigTimeoutTime_IDCM" SG_ 250 APM_PowerLimitMode 0;
BA_ "GenSigTimeoutTime_ECM" SG_ 250 APM_OutputPower 0;
BA_ "GenSigTimeoutTime_BPCM" SG_ 250 APM_OutputPower 0;
BA_ "GenSigTimeoutTime_SGCP" SG_ 250 APM_OutputPower 0;
BA_ "GenSigTimeoutTime_MCPB" SG_ 250 APM_OutputPower 0;
BA_ "GenSigTimeoutTime_MCPA" SG_ 250 APM_OutputPower 0;
BA_ "GenSigTimeoutTime_IDCM" SG_ 250 APM_OutputPower 0;
BA_ "GenSigTimeoutTime_SGCP" SG_ 250 APM_InputPower 0;
BA_ "GenSigTimeoutTime_MCPB" SG_ 250 APM_InputPower 0;
BA_ "GenSigTimeoutTime_MCPA" SG_ 250 APM_InputPower 0;
BA_ "GenSigTimeoutTime_IDCM" SG_ 250 APM_InputPower 0;
BA_ "GenSigTimeoutTime_ECM" SG_ 250 APM_InputPower 0;
BA_ "GenSigTimeoutTime_BPCM" SG_ 250 APM_InputPower 0;
BA_ "GenSigTimeoutTime_ECM" SG_ 250 APM_IdcHvSetPFdbk 0;
BA_ "GenSigTimeoutTime_BPCM" SG_ 250 APM_IdcHvSetPFdbk 0;
BA_ "GenSigStartValue" SG_ 250 APM_IdcHvSetPFdbk 1021;
BA_ "GenSigTimeoutTime_SGCP" SG_ 250 APM_IdcHvSetPFdbk 0;
BA_ "GenSigTimeoutTime_MCPB" SG_ 250 APM_IdcHvSetPFdbk 0;
BA_ "GenSigTimeoutTime_MCPA" SG_ 250 APM_IdcHvSetPFdbk 0;
BA_ "GenSigTimeoutTime_IDCM" SG_ 250 APM_IdcHvSetPFdbk 0;
BA_ "GenSigTimeoutTime_ECM" SG_ 250 APM_HvVsetPFdbk 0;
BA_ "GenSigTimeoutTime_BPCM" SG_ 250 APM_HvVsetPFdbk 0;
BA_ "GenSigTimeoutTime_SGCP" SG_ 250 APM_HvVsetPFdbk 0;
BA_ "GenSigTimeoutTime_MCPB" SG_ 250 APM_HvVsetPFdbk 0;
BA_ "GenSigTimeoutTime_MCPA" SG_ 250 APM_HvVsetPFdbk 0;
BA_ "GenSigTimeoutTime_IDCM" SG_ 250 APM_HvVsetPFdbk 0;
BA_ "GenSigTimeoutTime_ECM" SG_ 250 APM_HvOverVStatus 0;
BA_ "GenSigTimeoutTime_BPCM" SG_ 250 APM_HvOverVStatus 0;
BA_ "GenSigTimeoutTime_SGCP" SG_ 250 APM_HvOverVStatus 0;
BA_ "GenSigTimeoutTime_MCPB" SG_ 250 APM_HvOverVStatus 0;
BA_ "GenSigTimeoutTime_MCPA" SG_ 250 APM_HvOverVStatus 0;
BA_ "GenSigTimeoutTime_IDCM" SG_ 250 APM_HvOverVStatus 0;
BA_ "GenSigTimeoutTime_SGCP" SG_ 544 TCP_Communication_Terminated 0;
BA_ "GenSigTimeoutTime_MCPB" SG_ 544 TCP_Communication_Terminated 0;
BA_ "GenSigTimeoutTime_MCPA" SG_ 544 TCP_Communication_Terminated 0;
BA_ "GenSigTimeoutTime_IDCM" SG_ 544 TCP_Communication_Terminated 0;
BA_ "GenSigTimeoutTime_ECM" SG_ 544 OBCM_CP1Sts 0;
BA_ "GenSigTimeoutTime_BPCM" SG_ 544 OBCM_CP1Sts 0;
BA_ "GenSigTimeoutTime_SGCP" SG_ 544 OBCM_CP1Sts 0;
BA_ "GenSigTimeoutTime_MCPB" SG_ 544 OBCM_CP1Sts 0;
BA_ "GenSigTimeoutTime_MCPA" SG_ 544 OBCM_CP1Sts 0;
BA_ "GenSigTimeoutTime_IDCM" SG_ 544 OBCM_CP1Sts 0;
BA_ "GenSigTimeoutTime_IDCM" SG_ 544 TxGBTMessageResponse 0;
BA_ "GenSigTimeoutTime_ECM" SG_ 544 TxGBTMessageResponse 0;
BA_ "GenSigTimeoutTime_BPCM" SG_ 544 TxGBTMessageResponse 0;
BA_ "GenSigTimeoutTime_SGCP" SG_ 544 TxGBTMessageResponse 0;
BA_ "GenSigTimeoutTime_MCPB" SG_ 544 TxGBTMessageResponse 0;
BA_ "GenSigTimeoutTime_MCPA" SG_ 544 TxGBTMessageResponse 0;
BA_ "GenSigTimeoutTime_ECM" SG_ 544 TxGBTMessageRequest 0;
BA_ "GenSigTimeoutTime_BPCM" SG_ 544 TxGBTMessageRequest 0;
BA_ "GenSigTimeoutTime_SGCP" SG_ 544 TxGBTMessageRequest 0;
BA_ "GenSigTimeoutTime_MCPB" SG_ 544 TxGBTMessageRequest 0;
BA_ "GenSigTimeoutTime_MCPA" SG_ 544 TxGBTMessageRequest 0;
BA_ "GenSigTimeoutTime_IDCM" SG_ 544 TxGBTMessageRequest 0;
BA_ "GenSigTimeoutTime_ECM" SG_ 544 OBCM_Timeout 0;
BA_ "GenSigTimeoutTime_BPCM" SG_ 544 OBCM_Timeout 0;
BA_ "GenSigTimeoutTime_SGCP" SG_ 544 OBCM_Timeout 0;
BA_ "GenSigTimeoutTime_MCPB" SG_ 544 OBCM_Timeout 0;
BA_ "GenSigTimeoutTime_MCPA" SG_ 544 OBCM_Timeout 0;
BA_ "GenSigTimeoutTime_IDCM" SG_ 544 OBCM_Timeout 0;
BA_ "GenSigTimeoutTime_ECM" SG_ 544 EVCC_FailureSts 0;
BA_ "GenSigTimeoutTime_BPCM" SG_ 544 EVCC_FailureSts 0;
BA_ "GenSigTimeoutTime_SGCP" SG_ 544 EVCC_FailureSts 0;
BA_ "GenSigTimeoutTime_MCPB" SG_ 544 EVCC_FailureSts 0;
BA_ "GenSigTimeoutTime_MCPA" SG_ 544 EVCC_FailureSts 0;
BA_ "GenSigTimeoutTime_IDCM" SG_ 544 EVCC_FailureSts 0;
BA_ "GenSigTimeoutTime_ECM" SG_ 544 CC2_VoltageValue 0;
BA_ "GenSigTimeoutTime_BPCM" SG_ 544 CC2_VoltageValue 0;
BA_ "GenSigTimeoutTime_SGCP" SG_ 544 CC2_VoltageValue 0;
BA_ "GenSigTimeoutTime_MCPB" SG_ 544 CC2_VoltageValue 0;
BA_ "GenSigTimeoutTime_MCPA" SG_ 544 CC2_VoltageValue 0;
BA_ "GenSigTimeoutTime_IDCM" SG_ 544 CC2_VoltageValue 0;
BA_ "GenSigTimeoutTime_ECM" SG_ 544 CC2VoltDetError 0;
BA_ "GenSigTimeoutTime_BPCM" SG_ 544 CC2VoltDetError 0;
BA_ "GenSigStartValue" SG_ 544 CC2VoltDetError 2;
BA_ "GenSigTimeoutTime_SGCP" SG_ 544 CC2VoltDetError 0;
BA_ "GenSigTimeoutTime_MCPB" SG_ 544 CC2VoltDetError 0;
BA_ "GenSigTimeoutTime_MCPA" SG_ 544 CC2VoltDetError 0;
BA_ "GenSigTimeoutTime_IDCM" SG_ 544 CC2VoltDetError 0;
BA_ "GenSigTimeoutTime_MCPA" SG_ 544 OBCM_CSSts 0;
BA_ "GenSigTimeoutTime_IDCM" SG_ 544 OBCM_CSSts 0;
BA_ "GenSigTimeoutTime_ECM" SG_ 1031 EVSENominalVoltage 0;
BA_ "GenSigTimeoutTime_BPCM" SG_ 1031 EVSENominalVoltage 0;
BA_ "GenSigTimeoutTime_SGCP" SG_ 1031 EVSENominalVoltage 0;
BA_ "GenSigTimeoutTime_MCPB" SG_ 1031 EVSENominalVoltage 0;
BA_ "GenSigTimeoutTime_MCPA" SG_ 1031 EVSENominalVoltage 0;
BA_ "GenSigTimeoutTime_IDCM" SG_ 1031 EVSENominalVoltage 0;
BA_ "GenSigTimeoutTime_ECM" SG_ 1031 AC_LnHi 0;
BA_ "GenSigTimeoutTime_BPCM" SG_ 1031 AC_LnHi 0;
BA_ "GenSigTimeoutTime_SGCP" SG_ 1031 AC_LnHi 0;
BA_ "GenSigTimeoutTime_MCPB" SG_ 1031 AC_LnHi 0;
BA_ "GenSigTimeoutTime_MCPA" SG_ 1031 AC_LnHi 0;
BA_ "GenSigTimeoutTime_IDCM" SG_ 1031 AC_LnHi 0;
BA_ "GenSigTimeoutTime_ECM" SG_ 1031 RCD 0;
BA_ "GenSigTimeoutTime_BPCM" SG_ 1031 RCD 0;
BA_ "GenSigTimeoutTime_SGCP" SG_ 1031 RCD 0;
BA_ "GenSigTimeoutTime_MCPB" SG_ 1031 RCD 0;
BA_ "GenSigTimeoutTime_MCPA" SG_ 1031 RCD 0;
BA_ "GenSigTimeoutTime_IDCM" SG_ 1031 RCD 0;
BA_ "GenSigTimeoutTime_MCPA" SG_ 1031 EVSEMaxCurrent 0;
BA_ "GenSigTimeoutTime_IDCM" SG_ 1031 EVSEMaxCurrent 0;
BA_ "GenSigTimeoutTime_ECM" SG_ 1031 EVSEMaxCurrent 0;
BA_ "GenSigTimeoutTime_BPCM" SG_ 1031 EVSEMaxCurrent 0;
BA_ "GenSigTimeoutTime_SGCP" SG_ 1031 EVSEMaxCurrent 0;
BA_ "GenSigTimeoutTime_MCPB" SG_ 1031 EVSEMaxCurrent 0;
BA_ "GenSigTimeoutTime_ECM" SG_ 1031 Supported_ProtocolName 0;
BA_ "GenSigTimeoutTime_BPCM" SG_ 1031 Supported_ProtocolName 0;
BA_ "GenSigTimeoutTime_SGCP" SG_ 1031 Supported_ProtocolName 0;
BA_ "GenSigTimeoutTime_MCPB" SG_ 1031 Supported_ProtocolName 0;
BA_ "GenSigTimeoutTime_MCPA" SG_ 1031 Supported_ProtocolName 0;
BA_ "GenSigTimeoutTime_IDCM" SG_ 1031 Supported_ProtocolName 0;
BA_ "GenSigTimeoutTime_ECM" SG_ 1031 MessageCounter_HV_CHARGER1 0;
BA_ "GenSigTimeoutTime_BPCM" SG_ 1031 MessageCounter_HV_CHARGER1 0;
BA_ "GenSigTimeoutTime_SGCP" SG_ 1031 MessageCounter_HV_CHARGER1 0;
BA_ "GenSigTimeoutTime_MCPB" SG_ 1031 MessageCounter_HV_CHARGER1 0;
BA_ "GenSigTimeoutTime_MCPA" SG_ 1031 MessageCounter_HV_CHARGER1 0;
BA_ "GenSigTimeoutTime_IDCM" SG_ 1031 MessageCounter_HV_CHARGER1 0;
BA_ "GenSigTimeoutTime_ECM" SG_ 1031 EVCC_FailureReason 0;
BA_ "GenSigTimeoutTime_BPCM" SG_ 1031 EVCC_FailureReason 0;
BA_ "GenSigTimeoutTime_SGCP" SG_ 1031 EVCC_FailureReason 0;
BA_ "GenSigTimeoutTime_MCPB" SG_ 1031 EVCC_FailureReason 0;
BA_ "GenSigTimeoutTime_MCPA" SG_ 1031 EVCC_FailureReason 0;
BA_ "GenSigTimeoutTime_IDCM" SG_ 1031 EVCC_FailureReason 0;
BA_ "GenSigTimeoutTime_ECM" SG_ 1031 CRC_HV_CHARGER1 0;
BA_ "GenSigTimeoutTime_BPCM" SG_ 1031 CRC_HV_CHARGER1 0;
BA_ "GenSigTimeoutTime_SGCP" SG_ 1031 CRC_HV_CHARGER1 0;
BA_ "GenSigTimeoutTime_MCPB" SG_ 1031 CRC_HV_CHARGER1 0;
BA_ "GenSigTimeoutTime_MCPA" SG_ 1031 CRC_HV_CHARGER1 0;
BA_ "GenSigTimeoutTime_IDCM" SG_ 1031 CRC_HV_CHARGER1 0;
BA_ "GenSigTimeoutTime_ECM" SG_ 1031 BatterySideVoltage 0;
BA_ "GenSigTimeoutTime_BPCM" SG_ 1031 BatterySideVoltage 0;
BA_ "GenSigTimeoutTime_SGCP" SG_ 1031 BatterySideVoltage 0;
BA_ "GenSigTimeoutTime_MCPB" SG_ 1031 BatterySideVoltage 0;
BA_ "GenSigTimeoutTime_MCPA" SG_ 1031 BatterySideVoltage 0;
BA_ "GenSigTimeoutTime_IDCM" SG_ 1031 BatterySideVoltage 0;
BA_ "GenSigTimeoutTime_ECM" SG_ 1031 AC_LnLow 0;
BA_ "GenSigTimeoutTime_BPCM" SG_ 1031 AC_LnLow 0;
BA_ "GenSigTimeoutTime_SGCP" SG_ 1031 AC_LnLow 0;
BA_ "GenSigTimeoutTime_MCPB" SG_ 1031 AC_LnLow 0;
BA_ "GenSigTimeoutTime_MCPA" SG_ 1031 AC_LnLow 0;
BA_ "GenSigTimeoutTime_IDCM" SG_ 1031 AC_LnLow 0;
BA_ "GenSigTimeoutTime_ECM" SG_ 544 CRC_OV2 0;
BA_ "GenSigTimeoutTime_BPCM" SG_ 544 CRC_OV2 0;
BA_ "GenSigTimeoutTime_SGCP" SG_ 544 CRC_OV2 0;
BA_ "GenSigTimeoutTime_MCPB" SG_ 544 CRC_OV2 0;
BA_ "GenSigTimeoutTime_MCPA" SG_ 544 CRC_OV2 0;
BA_ "GenSigTimeoutTime_IDCM" SG_ 544 CRC_OV2 0;
BA_ "GenSigTimeoutTime_ECM" SG_ 544 GBT_EVSE_Charge_Permitting 0;
BA_ "GenSigTimeoutTime_BPCM" SG_ 544 GBT_EVSE_Charge_Permitting 0;
BA_ "GenSigTimeoutTime_SGCP" SG_ 544 GBT_EVSE_Charge_Permitting 0;
BA_ "GenSigTimeoutTime_MCPB" SG_ 544 GBT_EVSE_Charge_Permitting 0;
BA_ "GenSigTimeoutTime_MCPA" SG_ 544 GBT_EVSE_Charge_Permitting 0;
BA_ "GenSigTimeoutTime_IDCM" SG_ 544 GBT_EVSE_Charge_Permitting 0;
BA_ "GenSigTimeoutTime_ECM" SG_ 544 MessageCounter_OV2 0;
BA_ "GenSigTimeoutTime_BPCM" SG_ 544 MessageCounter_OV2 0;
BA_ "GenSigTimeoutTime_SGCP" SG_ 544 MessageCounter_OV2 0;
BA_ "GenSigTimeoutTime_MCPB" SG_ 544 MessageCounter_OV2 0;
BA_ "GenSigTimeoutTime_MCPA" SG_ 544 MessageCounter_OV2 0;
BA_ "GenSigTimeoutTime_IDCM" SG_ 544 MessageCounter_OV2 0;
BA_ "GenSigTimeoutTime_ECM" SG_ 260 INVRRInterlockSts 0;
BA_ "GenSigTimeoutTime_BPCM" SG_ 260 INVRRInterlockSts 0;
BA_ "GenSigTimeoutTime_SGCP" SG_ 260 INVRRInterlockSts 0;
BA_ "GenSigTimeoutTime_ECM" SG_ 1031 Supported_VerNumberMajor 0;
BA_ "GenSigTimeoutTime_BPCM" SG_ 1031 Supported_VerNumberMajor 0;
BA_ "GenSigTimeoutTime_SGCP" SG_ 1031 Supported_VerNumberMajor 0;
BA_ "GenSigTimeoutTime_MCPB" SG_ 1031 Supported_VerNumberMajor 0;
BA_ "GenSigTimeoutTime_MCPA" SG_ 1031 Supported_VerNumberMajor 0;
BA_ "GenSigTimeoutTime_IDCM" SG_ 1031 Supported_VerNumberMajor 0;
BA_ "GenSigTimeoutTime_ECM" SG_ 1031 Supported_SchemaID 0;
BA_ "GenSigTimeoutTime_BPCM" SG_ 1031 Supported_SchemaID 0;
BA_ "GenSigTimeoutTime_SGCP" SG_ 1031 Supported_SchemaID 0;
BA_ "GenSigTimeoutTime_MCPB" SG_ 1031 Supported_SchemaID 0;
BA_ "GenSigTimeoutTime_MCPA" SG_ 1031 Supported_SchemaID 0;
BA_ "GenSigTimeoutTime_IDCM" SG_ 1031 Supported_SchemaID 0;
BA_ "GenSigTimeoutTime_ECM" SG_ 1031 Supported_VerNumberMinor 0;
BA_ "GenSigTimeoutTime_BPCM" SG_ 1031 Supported_VerNumberMinor 0;
BA_ "GenSigTimeoutTime_SGCP" SG_ 1031 Supported_VerNumberMinor 0;
BA_ "GenSigTimeoutTime_MCPB" SG_ 1031 Supported_VerNumberMinor 0;
BA_ "GenSigTimeoutTime_MCPA" SG_ 1031 Supported_VerNumberMinor 0;
BA_ "GenSigTimeoutTime_IDCM" SG_ 1031 Supported_VerNumberMinor 0;
BA_ "GenSigTimeoutTime_ECM" SG_ 1031 AC_HighLoadWarning 0;
BA_ "GenSigTimeoutTime_BPCM" SG_ 1031 AC_HighLoadWarning 0;
BA_ "GenSigTimeoutTime_SGCP" SG_ 1031 AC_HighLoadWarning 0;
BA_ "GenSigTimeoutTime_MCPB" SG_ 1031 AC_HighLoadWarning 0;
BA_ "GenSigTimeoutTime_MCPA" SG_ 1031 AC_HighLoadWarning 0;
BA_ "GenSigTimeoutTime_IDCM" SG_ 1031 AC_HighLoadWarning 0;
BA_ "GenSigTimeoutTime_ECM" SG_ 1031 BatterySideCurrent 0;
BA_ "GenSigTimeoutTime_BPCM" SG_ 1031 BatterySideCurrent 0;
BA_ "GenSigTimeoutTime_SGCP" SG_ 1031 BatterySideCurrent 0;
BA_ "GenSigTimeoutTime_MCPB" SG_ 1031 BatterySideCurrent 0;
BA_ "GenSigTimeoutTime_MCPA" SG_ 1031 BatterySideCurrent 0;
BA_ "GenSigTimeoutTime_IDCM" SG_ 1031 BatterySideCurrent 0;
BA_ "GenSigTimeoutTime_ECM" SG_ 1031 AC_Present 0;
BA_ "GenSigTimeoutTime_BPCM" SG_ 1031 AC_Present 0;
BA_ "GenSigTimeoutTime_SGCP" SG_ 1031 AC_Present 0;
BA_ "GenSigTimeoutTime_MCPB" SG_ 1031 AC_Present 0;
BA_ "GenSigTimeoutTime_MCPA" SG_ 1031 AC_Present 0;
BA_ "GenSigTimeoutTime_IDCM" SG_ 1031 AC_Present 0;
BA_ "GenSigTimeoutTime_ECM" SG_ 1031 ControlPilotSts 0;
BA_ "GenSigTimeoutTime_BPCM" SG_ 1031 ControlPilotSts 0;
BA_ "GenSigTimeoutTime_SGCP" SG_ 1031 ControlPilotSts 0;
BA_ "GenSigTimeoutTime_MCPB" SG_ 1031 ControlPilotSts 0;
BA_ "GenSigTimeoutTime_MCPA" SG_ 1031 ControlPilotSts 0;
BA_ "GenSigTimeoutTime_IDCM" SG_ 1031 ControlPilotSts 0;
BA_ "GenSigTimeoutTime_ECM" SG_ 1031 ChargeEnableSts 0;
BA_ "GenSigTimeoutTime_BPCM" SG_ 1031 ChargeEnableSts 0;
BA_ "GenSigTimeoutTime_SGCP" SG_ 1031 ChargeEnableSts 0;
BA_ "GenSigTimeoutTime_MCPB" SG_ 1031 ChargeEnableSts 0;
BA_ "GenSigTimeoutTime_MCPA" SG_ 1031 ChargeEnableSts 0;
BA_ "GenSigTimeoutTime_IDCM" SG_ 1031 ChargeEnableSts 0;
BA_ "GenSigTimeoutTime_ECM" SG_ 1031 ChargeCurrentAvailable 0;
BA_ "GenSigTimeoutTime_BPCM" SG_ 1031 ChargeCurrentAvailable 0;
BA_ "GenSigTimeoutTime_SGCP" SG_ 1031 ChargeCurrentAvailable 0;
BA_ "GenSigTimeoutTime_MCPB" SG_ 1031 ChargeCurrentAvailable 0;
BA_ "GenSigTimeoutTime_MCPA" SG_ 1031 ChargeCurrentAvailable 0;
BA_ "GenSigTimeoutTime_IDCM" SG_ 1031 ChargeCurrentAvailable 0;
BA_ "GenSigTimeoutTime_ECM" SG_ 1031 ChargeCurrent 0;
BA_ "GenSigTimeoutTime_BPCM" SG_ 1031 ChargeCurrent 0;
BA_ "GenSigTimeoutTime_SGCP" SG_ 1031 ChargeCurrent 0;
BA_ "GenSigTimeoutTime_MCPB" SG_ 1031 ChargeCurrent 0;
BA_ "GenSigTimeoutTime_MCPA" SG_ 1031 ChargeCurrent 0;
BA_ "GenSigTimeoutTime_IDCM" SG_ 1031 ChargeCurrent 0;
BA_ "GenSigTimeoutTime_ECM" SG_ 1031 AC_Side_Curr1 0;
BA_ "GenSigTimeoutTime_BPCM" SG_ 1031 AC_Side_Curr1 0;
BA_ "GenSigStartValue" SG_ 1031 AC_Side_Curr1 1000;
BA_ "GenSigTimeoutTime_SGCP" SG_ 1031 AC_Side_Curr1 0;
BA_ "GenSigTimeoutTime_MCPB" SG_ 1031 AC_Side_Curr1 0;
BA_ "GenSigTimeoutTime_MCPA" SG_ 1031 AC_Side_Curr1 0;
BA_ "GenSigTimeoutTime_IDCM" SG_ 1031 AC_Side_Curr1 0;
BA_ "GenSigTimeoutTime_ECM" SG_ 1031 ProximitySts 0;
BA_ "GenSigTimeoutTime_BPCM" SG_ 1031 ProximitySts 0;
BA_ "GenSigStartValue" SG_ 1031 ProximitySts 1;
BA_ "GenSigTimeoutTime_SGCP" SG_ 1031 ProximitySts 0;
BA_ "GenSigTimeoutTime_MCPB" SG_ 1031 ProximitySts 0;
BA_ "GenSigTimeoutTime_MCPA" SG_ 1031 ProximitySts 0;
BA_ "GenSigTimeoutTime_IDCM" SG_ 1031 ProximitySts 0;
BA_ "GenSigTimeoutTime_ECM" SG_ 1031 OBCM_SlacSts 0;
BA_ "GenSigTimeoutTime_BPCM" SG_ 1031 OBCM_SlacSts 0;
BA_ "GenSigTimeoutTime_SGCP" SG_ 1031 OBCM_SlacSts 0;
BA_ "GenSigTimeoutTime_MCPB" SG_ 1031 OBCM_SlacSts 0;
BA_ "GenSigTimeoutTime_MCPA" SG_ 1031 OBCM_SlacSts 0;
BA_ "GenSigTimeoutTime_IDCM" SG_ 1031 OBCM_SlacSts 0;
BA_ "GenSigTimeoutTime_MCPB" SG_ 1031 OBCM_SdpSts 0;
BA_ "GenSigTimeoutTime_MCPA" SG_ 1031 OBCM_SdpSts 0;
BA_ "GenSigTimeoutTime_IDCM" SG_ 1031 OBCM_SdpSts 0;
BA_ "GenSigTimeoutTime_ECM" SG_ 1031 OBCM_SdpSts 0;
BA_ "GenSigTimeoutTime_BPCM" SG_ 1031 OBCM_SdpSts 0;
BA_ "GenSigTimeoutTime_SGCP" SG_ 1031 OBCM_SdpSts 0;
BA_ "GenSigTimeoutTime_BPCM" SG_ 1031 OBCInterlockSts 0;
BA_ "GenSigTimeoutTime_MCPB" SG_ 1031 OBCInterlockSts 0;
BA_ "GenSigTimeoutTime_MCPA" SG_ 1031 OBCInterlockSts 0;
BA_ "GenSigTimeoutTime_IDCM" SG_ 1031 OBCInterlockSts 0;
BA_ "GenSigTimeoutTime_ECM" SG_ 1031 OBC_DeratingReason 0;
BA_ "GenSigTimeoutTime_BPCM" SG_ 1031 OBC_DeratingReason 0;
BA_ "GenSigTimeoutTime_SGCP" SG_ 1031 OBC_DeratingReason 0;
BA_ "GenSigTimeoutTime_MCPB" SG_ 1031 OBC_DeratingReason 0;
BA_ "GenSigTimeoutTime_MCPA" SG_ 1031 OBC_DeratingReason 0;
BA_ "GenSigTimeoutTime_IDCM" SG_ 1031 OBC_DeratingReason 0;
BA_ "GenSigTimeoutTime_ECM" SG_ 1031 J1772_State 0;
BA_ "GenSigTimeoutTime_BPCM" SG_ 1031 J1772_State 0;
BA_ "GenSigTimeoutTime_SGCP" SG_ 1031 J1772_State 0;
BA_ "GenSigTimeoutTime_MCPB" SG_ 1031 J1772_State 0;
BA_ "GenSigTimeoutTime_MCPA" SG_ 1031 J1772_State 0;
BA_ "GenSigTimeoutTime_IDCM" SG_ 1031 J1772_State 0;
BA_ "GenSigTimeoutTime_ECM" SG_ 1031 J1772_S2_Sts 0;
BA_ "GenSigTimeoutTime_BPCM" SG_ 1031 J1772_S2_Sts 0;
BA_ "GenSigTimeoutTime_SGCP" SG_ 1031 J1772_S2_Sts 0;
BA_ "GenSigTimeoutTime_MCPB" SG_ 1031 J1772_S2_Sts 0;
BA_ "GenSigTimeoutTime_MCPA" SG_ 1031 J1772_S2_Sts 0;
BA_ "GenSigTimeoutTime_IDCM" SG_ 1031 J1772_S2_Sts 0;
BA_ "GenSigTimeoutTime_ECM" SG_ 1031 InputVoltage_isAC 0;
BA_ "GenSigTimeoutTime_BPCM" SG_ 1031 InputVoltage_isAC 0;
BA_ "GenSigStartValue" SG_ 1031 InputVoltage_isAC 1;
BA_ "GenSigTimeoutTime_SGCP" SG_ 1031 InputVoltage_isAC 0;
BA_ "GenSigTimeoutTime_MCPB" SG_ 1031 InputVoltage_isAC 0;
BA_ "GenSigTimeoutTime_MCPA" SG_ 1031 InputVoltage_isAC 0;
BA_ "GenSigTimeoutTime_IDCM" SG_ 1031 InputVoltage_isAC 0;
BA_ "GenSigTimeoutTime_ECM" SG_ 1031 InputVoltage_is60Hz 0;
BA_ "GenSigTimeoutTime_BPCM" SG_ 1031 InputVoltage_is60Hz 0;
BA_ "GenSigStartValue" SG_ 1031 InputVoltage_is60Hz 1;
BA_ "GenSigTimeoutTime_SGCP" SG_ 1031 InputVoltage_is60Hz 0;
BA_ "GenSigTimeoutTime_MCPB" SG_ 1031 InputVoltage_is60Hz 0;
BA_ "GenSigTimeoutTime_MCPA" SG_ 1031 InputVoltage_is60Hz 0;
BA_ "GenSigTimeoutTime_IDCM" SG_ 1031 InputVoltage_is60Hz 0;
BA_ "GenSigTimeoutTime_ECM" SG_ 1031 HV_Overvoltage 0;
BA_ "GenSigTimeoutTime_BPCM" SG_ 1031 HV_Overvoltage 0;
BA_ "GenSigTimeoutTime_SGCP" SG_ 1031 HV_Overvoltage 0;
BA_ "GenSigTimeoutTime_MCPB" SG_ 1031 HV_Overvoltage 0;
BA_ "GenSigTimeoutTime_MCPA" SG_ 1031 HV_Overvoltage 0;
BA_ "GenSigTimeoutTime_IDCM" SG_ 1031 HV_Overvoltage 0;
BA_ "GenSigTimeoutTime_ECM" SG_ 1031 HV_Overcurrent 0;
BA_ "GenSigTimeoutTime_BPCM" SG_ 1031 HV_Overcurrent 0;
BA_ "GenSigTimeoutTime_SGCP" SG_ 1031 HV_Overcurrent 0;
BA_ "GenSigTimeoutTime_MCPB" SG_ 1031 HV_Overcurrent 0;
BA_ "GenSigTimeoutTime_MCPA" SG_ 1031 HV_Overcurrent 0;
BA_ "GenSigTimeoutTime_IDCM" SG_ 1031 HV_Overcurrent 0;
BA_ "GenSigTimeoutTime_ECM" SG_ 260 InvRR_DerateReason 0;
BA_ "GenSigTimeoutTime_BPCM" SG_ 260 InvRR_DerateReason 0;
BA_ "GenSigTimeoutTime_SGCP" SG_ 260 InvRR_DerateReason 0;
BA_ "GenSigTimeoutTime_MCPB" SG_ 260 InvRR_DerateReason 0;
BA_ "GenSigTimeoutTime_MCPA" SG_ 260 InvRR_DerateReason 0;
BA_ "GenSigTimeoutTime_IDCM" SG_ 260 InvRR_DerateReason 0;
BA_ "GenSigTimeoutTime_ECM" SG_ 260 MCPB_TorqAchieved_AEMD 0;
BA_ "GenSigTimeoutTime_BPCM" SG_ 260 MCPB_TorqAchieved_AEMD 0;
BA_ "GenSigStartValue" SG_ 260 MCPB_TorqAchieved_AEMD 4096;
BA_ "GenSigTimeoutTime_SGCP" SG_ 260 MCPB_TorqAchieved_AEMD 0;
BA_ "GenSigTimeoutTime_MCPB" SG_ 260 MCPB_TorqAchieved_AEMD 0;
BA_ "GenSigTimeoutTime_MCPA" SG_ 260 MCPB_TorqAchieved_AEMD 0;
BA_ "GenSigTimeoutTime_IDCM" SG_ 260 MCPB_TorqAchieved_AEMD 0;
BA_ "GenSigTimeoutTime_SGCP" SG_ 260 MCPB_Spd_Lim 0;
BA_ "GenSigTimeoutTime_MCPB" SG_ 260 MCPB_Spd_Lim 0;
BA_ "GenSigTimeoutTime_MCPA" SG_ 260 MCPB_Spd_Lim 0;
BA_ "GenSigTimeoutTime_IDCM" SG_ 260 MCPB_Spd_Lim 0;
BA_ "GenSigTimeoutTime_ECM" SG_ 260 MCPB_Spd_Lim 0;
BA_ "GenSigTimeoutTime_BPCM" SG_ 260 MCPB_Spd_Lim 0;
BA_ "GenSigTimeoutTime_ECM" SG_ 260 MCPB_RPM_V 0;
BA_ "GenSigTimeoutTime_BPCM" SG_ 260 MCPB_RPM_V 0;
BA_ "GenSigTimeoutTime_SGCP" SG_ 260 MCPB_RPM_V 0;
BA_ "GenSigTimeoutTime_MCPB" SG_ 260 MCPB_RPM_V 0;
BA_ "GenSigTimeoutTime_MCPA" SG_ 260 MCPB_RPM_V 0;
BA_ "GenSigTimeoutTime_IDCM" SG_ 260 MCPB_RPM_V 0;
BA_ "GenSigTimeoutTime_ECM" SG_ 260 MCPB_MtrMinCpbltyTrq 0;
BA_ "GenSigTimeoutTime_BPCM" SG_ 260 MCPB_MtrMinCpbltyTrq 0;
BA_ "GenSigStartValue" SG_ 260 MCPB_MtrMinCpbltyTrq 4096;
BA_ "GenSigTimeoutTime_SGCP" SG_ 260 MCPB_MtrMinCpbltyTrq 0;
BA_ "GenSigTimeoutTime_MCPB" SG_ 260 MCPB_MtrMinCpbltyTrq 0;
BA_ "GenSigTimeoutTime_MCPA" SG_ 260 MCPB_MtrMinCpbltyTrq 0;
BA_ "GenSigTimeoutTime_IDCM" SG_ 260 MCPB_MtrMinCpbltyTrq 0;
BA_ "GenSigTimeoutTime_ECM" SG_ 260 InvRR_ACVoltage 0;
BA_ "GenSigTimeoutTime_BPCM" SG_ 260 InvRR_ACVoltage 0;
BA_ "GenSigTimeoutTime_SGCP" SG_ 260 InvRR_ACVoltage 0;
BA_ "GenSigTimeoutTime_MCPB" SG_ 260 InvRR_ACVoltage 0;
BA_ "GenSigTimeoutTime_MCPA" SG_ 260 InvRR_ACVoltage 0;
BA_ "GenSigTimeoutTime_IDCM" SG_ 260 InvRR_ACVoltage 0;
BA_ "GenSigTimeoutTime_ECM" SG_ 260 MC_PRR1 0;
BA_ "GenSigTimeoutTime_SGCP" SG_ 260 MC_PRR1 0;
BA_ "GenSigTimeoutTime_MCPB" SG_ 260 MC_PRR1 0;
BA_ "GenSigTimeoutTime_MCPA" SG_ 260 MC_PRR1 0;
BA_ "GenSigTimeoutTime_IDCM" SG_ 260 MC_PRR1 0;
BA_ "GenSigTimeoutTime_BPCM" SG_ 260 InvRR_CoolantTemp 0;
BA_ "GenSigTimeoutTime_SGCP" SG_ 260 InvRR_CoolantTemp 0;
BA_ "GenSigTimeoutTime_MCPB" SG_ 260 InvRR_CoolantTemp 0;
BA_ "GenSigTimeoutTime_MCPA" SG_ 260 InvRR_CoolantTemp 0;
BA_ "GenSigTimeoutTime_IDCM" SG_ 260 InvRR_CoolantTemp 0;
BA_ "GenSigTimeoutTime_ECM" SG_ 260 InvRR_CoolantTemp 0;
BA_ "GenSigTimeoutTime_MCPB" SG_ 260 MCPB_SPT_Stat 0;
BA_ "GenSigTimeoutTime_MCPA" SG_ 260 MCPB_SPT_Stat 0;
BA_ "GenSigTimeoutTime_IDCM" SG_ 260 MCPB_SPT_Stat 0;
BA_ "GenSigTimeoutTime_ECM" SG_ 260 MCPB_MtrMaxCpbltyTrq 0;
BA_ "GenSigTimeoutTime_BPCM" SG_ 260 MCPB_MtrMaxCpbltyTrq 0;
BA_ "GenSigStartValue" SG_ 260 MCPB_MtrMaxCpbltyTrq 4096;
BA_ "GenSigTimeoutTime_SGCP" SG_ 260 MCPB_MtrMaxCpbltyTrq 0;
BA_ "GenSigTimeoutTime_MCPB" SG_ 260 MCPB_MtrMaxCpbltyTrq 0;
BA_ "GenSigTimeoutTime_MCPA" SG_ 260 MCPB_MtrMaxCpbltyTrq 0;
BA_ "GenSigTimeoutTime_IDCM" SG_ 260 MCPB_MtrMaxCpbltyTrq 0;
BA_ "GenSigTimeoutTime_ECM" SG_ 260 MCPB_MtrIndex 0;
BA_ "GenSigTimeoutTime_BPCM" SG_ 260 MCPB_MtrIndex 0;
BA_ "GenSigTimeoutTime_SGCP" SG_ 260 MCPB_MtrIndex 0;
BA_ "GenSigTimeoutTime_MCPB" SG_ 260 MCPB_MtrIndex 0;
BA_ "GenSigTimeoutTime_MCPA" SG_ 260 MCPB_MtrIndex 0;
BA_ "GenSigTimeoutTime_IDCM" SG_ 260 MCPB_MtrIndex 0;
BA_ "GenSigTimeoutTime_ECM" SG_ 260 MCPB_MinTorq 0;
BA_ "GenSigTimeoutTime_BPCM" SG_ 260 MCPB_MinTorq 0;
BA_ "GenSigStartValue" SG_ 260 MCPB_MinTorq 4096;
BA_ "GenSigTimeoutTime_SGCP" SG_ 260 MCPB_MinTorq 0;
BA_ "GenSigTimeoutTime_MCPB" SG_ 260 MCPB_MinTorq 0;
BA_ "GenSigTimeoutTime_MCPA" SG_ 260 MCPB_MinTorq 0;
BA_ "GenSigTimeoutTime_IDCM" SG_ 260 MCPB_MinTorq 0;
BA_ "GenSigTimeoutTime_ECM" SG_ 260 MCPB_MaxTorq 0;
BA_ "GenSigTimeoutTime_BPCM" SG_ 260 MCPB_MaxTorq 0;
BA_ "GenSigStartValue" SG_ 260 MCPB_MaxTorq 4096;
BA_ "GenSigTimeoutTime_SGCP" SG_ 260 MCPB_MaxTorq 0;
BA_ "GenSigTimeoutTime_MCPB" SG_ 260 MCPB_MaxTorq 0;
BA_ "GenSigTimeoutTime_MCPA" SG_ 260 MCPB_MaxTorq 0;
BA_ "GenSigTimeoutTime_IDCM" SG_ 260 MCPB_MaxTorq 0;
BA_ "GenSigTimeoutTime_ECM" SG_ 260 MCPB_Invrtr_State 0;
BA_ "GenSigTimeoutTime_BPCM" SG_ 260 MCPB_Invrtr_State 0;
BA_ "GenSigTimeoutTime_SGCP" SG_ 260 MCPB_Invrtr_State 0;
BA_ "GenSigTimeoutTime_MCPB" SG_ 260 MCPB_Invrtr_State 0;
BA_ "GenSigTimeoutTime_MCPA" SG_ 260 MCPB_Invrtr_State 0;
BA_ "GenSigTimeoutTime_IDCM" SG_ 260 MCPB_Invrtr_State 0;
BA_ "GenSigTimeoutTime_ECM" SG_ 260 MCPB_HV_CnctrOpn_Req 0;
BA_ "GenSigTimeoutTime_BPCM" SG_ 260 MCPB_HV_CnctrOpn_Req 0;
BA_ "GenSigTimeoutTime_SGCP" SG_ 260 MCPB_HV_CnctrOpn_Req 0;
BA_ "GenSigTimeoutTime_MCPB" SG_ 260 MCPB_HV_CnctrOpn_Req 0;
BA_ "GenSigTimeoutTime_MCPA" SG_ 260 MCPB_HV_CnctrOpn_Req 0;
BA_ "GenSigTimeoutTime_IDCM" SG_ 260 MCPB_HV_CnctrOpn_Req 0;
BA_ "GenSigTimeoutTime_ECM" SG_ 260 MCPB_Dschrge_Status 0;
BA_ "GenSigTimeoutTime_BPCM" SG_ 260 MCPB_Dschrge_Status 0;
BA_ "GenSigTimeoutTime_SGCP" SG_ 260 MCPB_Dschrge_Status 0;
BA_ "GenSigTimeoutTime_MCPB" SG_ 260 MCPB_Dschrge_Status 0;
BA_ "GenSigTimeoutTime_MCPA" SG_ 260 MCPB_Dschrge_Status 0;
BA_ "GenSigTimeoutTime_IDCM" SG_ 260 MCPB_Dschrge_Status 0;
BA_ "GenSigTimeoutTime_ECM" SG_ 260 MCPB_DeratingFactor 0;
BA_ "GenSigTimeoutTime_BPCM" SG_ 260 MCPB_DeratingFactor 0;
BA_ "GenSigTimeoutTime_SGCP" SG_ 260 MCPB_DeratingFactor 0;
BA_ "GenSigTimeoutTime_MCPB" SG_ 260 MCPB_DeratingFactor 0;
BA_ "GenSigTimeoutTime_MCPA" SG_ 260 MCPB_DeratingFactor 0;
BA_ "GenSigTimeoutTime_IDCM" SG_ 260 MCPB_DeratingFactor 0;
BA_ "GenSigTimeoutTime_ECM" SG_ 260 MCPB_DC_Volt_V 0;
BA_ "GenSigTimeoutTime_BPCM" SG_ 260 MCPB_DC_Volt_V 0;
BA_ "GenSigTimeoutTime_SGCP" SG_ 260 MCPB_DC_Volt_V 0;
BA_ "GenSigTimeoutTime_MCPB" SG_ 260 MCPB_DC_Volt_V 0;
BA_ "GenSigTimeoutTime_MCPA" SG_ 260 MCPB_DC_Volt_V 0;
BA_ "GenSigTimeoutTime_IDCM" SG_ 260 MCPB_DC_Volt_V 0;
BA_ "GenSigTimeoutTime_ECM" SG_ 260 MCPB_DC_Current_V 0;
BA_ "GenSigTimeoutTime_BPCM" SG_ 260 MCPB_DC_Current_V 0;
BA_ "GenSigTimeoutTime_SGCP" SG_ 260 MCPB_DC_Current_V 0;
BA_ "GenSigTimeoutTime_MCPB" SG_ 260 MCPB_DC_Current_V 0;
BA_ "GenSigTimeoutTime_MCPA" SG_ 260 MCPB_DC_Current_V 0;
BA_ "GenSigTimeoutTime_IDCM" SG_ 260 MCPB_DC_Current_V 0;
BA_ "GenSigTimeoutTime_ECM" SG_ 260 MCPB_DC_Current 0;
BA_ "GenSigStartValue" SG_ 260 MCPB_DC_Current 16384;
BA_ "GenSigTimeoutTime_SGCP" SG_ 260 MCPB_DC_Current 0;
BA_ "GenSigTimeoutTime_MCPB" SG_ 260 MCPB_DC_Current 0;
BA_ "GenSigTimeoutTime_MCPA" SG_ 260 MCPB_DC_Current 0;
BA_ "GenSigTimeoutTime_IDCM" SG_ 260 MCPB_DC_Current 0;
BA_ "GenSigTimeoutTime_ECM" SG_ 260 MCPB_CpbltySpdDivVolt 0;
BA_ "GenSigTimeoutTime_BPCM" SG_ 260 MCPB_CpbltySpdDivVolt 0;
BA_ "GenSigTimeoutTime_SGCP" SG_ 260 MCPB_CpbltySpdDivVolt 0;
BA_ "GenSigTimeoutTime_MCPB" SG_ 260 MCPB_CpbltySpdDivVolt 0;
BA_ "GenSigTimeoutTime_MCPA" SG_ 260 MCPB_CpbltySpdDivVolt 0;
BA_ "GenSigTimeoutTime_IDCM" SG_ 260 MCPB_CpbltySpdDivVolt 0;
BA_ "GenSigTimeoutTime_ECM" SG_ 260 MCPB_AccelRawV 0;
BA_ "GenSigTimeoutTime_BPCM" SG_ 260 MCPB_AccelRawV 0;
BA_ "GenSigTimeoutTime_SGCP" SG_ 260 MCPB_AccelRawV 0;
BA_ "GenSigTimeoutTime_MCPB" SG_ 260 MCPB_AccelRawV 0;
BA_ "GenSigTimeoutTime_MCPA" SG_ 260 MCPB_AccelRawV 0;
BA_ "GenSigTimeoutTime_IDCM" SG_ 260 MCPB_AccelRawV 0;
BA_ "GenSigTimeoutTime_ECM" SG_ 260 MCPB_AccelRaw 0;
BA_ "GenSigTimeoutTime_BPCM" SG_ 260 MCPB_AccelRaw 0;
BA_ "GenSigTimeoutTime_SGCP" SG_ 260 MCPB_AccelRaw 0;
BA_ "GenSigTimeoutTime_MCPB" SG_ 260 MCPB_AccelRaw 0;
BA_ "GenSigTimeoutTime_MCPA" SG_ 260 MCPB_AccelRaw 0;
BA_ "GenSigTimeoutTime_IDCM" SG_ 260 MCPB_AccelRaw 0;
BA_ "GenSigTimeoutTime_ECM" SG_ 260 MCPB_6SO_Status 0;
BA_ "GenSigTimeoutTime_BPCM" SG_ 260 MCPB_6SO_Status 0;
BA_ "GenSigTimeoutTime_SGCP" SG_ 260 MCPB_6SO_Status 0;
BA_ "GenSigTimeoutTime_MCPB" SG_ 260 MCPB_6SO_Status 0;
BA_ "GenSigTimeoutTime_MCPA" SG_ 260 MCPB_6SO_Status 0;
BA_ "GenSigTimeoutTime_IDCM" SG_ 260 MCPB_6SO_Status 0;
BA_ "GenSigTimeoutTime_ECM" SG_ 260 MCPB_3PS_Pos 0;
BA_ "GenSigTimeoutTime_BPCM" SG_ 260 MCPB_3PS_Pos 0;
BA_ "GenSigTimeoutTime_SGCP" SG_ 260 MCPB_3PS_Pos 0;
BA_ "GenSigTimeoutTime_MCPB" SG_ 260 MCPB_3PS_Pos 0;
BA_ "GenSigTimeoutTime_MCPA" SG_ 260 MCPB_3PS_Pos 0;
BA_ "GenSigTimeoutTime_IDCM" SG_ 260 MCPB_3PS_Pos 0;
BA_ "GenSigTimeoutTime_MCPA" SG_ 2654486617 CBV_bit4_ActiveWakeupBit_1E384059 0;
BA_ "GenSigTimeoutTime_IDCM" SG_ 2654486617 CBV_bit4_ActiveWakeupBit_1E384059 0;
BA_ "GenSigTimeoutTime_EVCU2" SG_ 2654486617 CBV_bit4_ActiveWakeupBit_1E384059 0;
BA_ "GenSigTimeoutTime_EVCU2" SG_ 2654486617 CBV_bit3_NMCoordinatorBit_1E384059 0;
BA_ "GenSigTimeoutTime_ECM" SG_ 2654486617 CBV_bit3_NMCoordinatorBit_1E384059 0;
BA_ "GenSigTimeoutTime_BPCM" SG_ 2654486617 CBV_bit3_NMCoordinatorBit_1E384059 0;
BA_ "GenSigTimeoutTime_SGCP" SG_ 2654486617 CBV_bit3_NMCoordinatorBit_1E384059 0;
BA_ "GenSigTimeoutTime_MCPB" SG_ 2654486617 CBV_bit3_NMCoordinatorBit_1E384059 0;
BA_ "GenSigTimeoutTime_MCPA" SG_ 2654486617 CBV_bit3_NMCoordinatorBit_1E384059 0;
BA_ "GenSigTimeoutTime_IDCM" SG_ 2654486617 CBV_bit3_NMCoordinatorBit_1E384059 0;
BA_ "GenSigTimeoutTime_ECM" SG_ 2564485653 N_PDU_18DAF215 0;
BA_ "GenSigTimeoutTime_BPCM" SG_ 2564485653 N_PDU_18DAF215 0;
BA_ "GenSigTimeoutTime_SGCP" SG_ 2564485653 N_PDU_18DAF215 0;
BA_ "GenSigTimeoutTime_MCPB" SG_ 2564485653 N_PDU_18DAF215 0;
BA_ "GenSigTimeoutTime_MCPA" SG_ 2564485653 N_PDU_18DAF215 0;
BA_ "GenSigTimeoutTime_IDCM" SG_ 2564485653 N_PDU_18DAF215 0;
BA_ "GenSigTimeoutTime_EVCU2" SG_ 2564485653 N_PDU_18DAF215 0;
BA_ "GenSigTimeoutTime_ECM" SG_ 2564682261 N_PDU_18DDF215 0;
BA_ "GenSigTimeoutTime_BPCM" SG_ 2564682261 N_PDU_18DDF215 0;
BA_ "GenSigTimeoutTime_SGCP" SG_ 2564682261 N_PDU_18DDF215 0;
BA_ "GenSigTimeoutTime_MCPB" SG_ 2564682261 N_PDU_18DDF215 0;
BA_ "GenSigTimeoutTime_MCPA" SG_ 2564682261 N_PDU_18DDF215 0;
BA_ "GenSigTimeoutTime_IDCM" SG_ 2564682261 N_PDU_18DDF215 0;
BA_ "GenSigTimeoutTime_EVCU2" SG_ 2564682261 N_PDU_18DDF215 0;
BA_ "GenSigTimeoutTime_ECM" SG_ 2564682005 N_PDU_18DDF115 0;
BA_ "GenSigTimeoutTime_BPCM" SG_ 2564682005 N_PDU_18DDF115 0;
BA_ "GenSigTimeoutTime_SGCP" SG_ 2564682005 N_PDU_18DDF115 0;
BA_ "GenSigTimeoutTime_MCPB" SG_ 2564682005 N_PDU_18DDF115 0;
BA_ "GenSigTimeoutTime_MCPA" SG_ 2564682005 N_PDU_18DDF115 0;
BA_ "GenSigTimeoutTime_IDCM" SG_ 2564682005 N_PDU_18DDF115 0;
BA_ "GenSigTimeoutTime_EVCU2" SG_ 2564682005 N_PDU_18DDF115 0;
BA_ "GenSigTimeoutTime_SGCP" SG_ 2654486617 CBV_bit2_1E384059 0;
BA_ "GenSigTimeoutTime_MCPB" SG_ 2654486617 CBV_bit2_1E384059 0;
BA_ "GenSigTimeoutTime_MCPA" SG_ 2654486617 CBV_bit2_1E384059 0;
BA_ "GenSigTimeoutTime_IDCM" SG_ 2654486617 CBV_bit2_1E384059 0;
BA_ "GenSigTimeoutTime_EVCU2" SG_ 2654486617 CBV_bit2_1E384059 0;
BA_ "GenSigTimeoutTime_ECM" SG_ 2654486617 CBV_bit2_1E384059 0;
BA_ "GenSigTimeoutTime_BPCM" SG_ 2654486617 CBV_bit2_1E384059 0;
BA_ "GenSigTimeoutTime_ECM" SG_ 2654486617 CBV_bit1_1E384059 0;
BA_ "GenSigTimeoutTime_BPCM" SG_ 2654486617 CBV_bit1_1E384059 0;
BA_ "GenSigTimeoutTime_SGCP" SG_ 2654486617 CBV_bit1_1E384059 0;
BA_ "GenSigTimeoutTime_MCPB" SG_ 2654486617 CBV_bit1_1E384059 0;
BA_ "GenSigTimeoutTime_MCPA" SG_ 2654486617 CBV_bit1_1E384059 0;
BA_ "GenSigTimeoutTime_IDCM" SG_ 2654486617 CBV_bit1_1E384059 0;
BA_ "GenSigTimeoutTime_EVCU2" SG_ 2654486617 CBV_bit1_1E384059 0;
BA_ "GenSigTimeoutTime_ECM" SG_ 2654486617 CBV_bit0_RepeatMessageRequestBit_1E384059 0;
BA_ "GenSigTimeoutTime_BPCM" SG_ 2654486617 CBV_bit0_RepeatMessageRequestBit_1E384059 0;
BA_ "GenSigTimeoutTime_SGCP" SG_ 2654486617 CBV_bit0_RepeatMessageRequestBit_1E384059 0;
BA_ "GenSigTimeoutTime_MCPB" SG_ 2654486617 CBV_bit0_RepeatMessageRequestBit_1E384059 0;
BA_ "GenSigTimeoutTime_MCPA" SG_ 2654486617 CBV_bit0_RepeatMessageRequestBit_1E384059 0;
BA_ "GenSigTimeoutTime_IDCM" SG_ 2654486617 CBV_bit0_RepeatMessageRequestBit_1E384059 0;
BA_ "GenSigTimeoutTime_EVCU2" SG_ 2654486617 CBV_bit0_RepeatMessageRequestBit_1E384059 0;
BA_ "GenSigTimeoutTime_ECM" SG_ 2654486617 SourceNodeIdentifier_1E384059 0;
BA_ "GenSigTimeoutTime_BPCM" SG_ 2654486617 SourceNodeIdentifier_1E384059 0;
BA_ "GenSigTimeoutTime_SGCP" SG_ 2654486617 SourceNodeIdentifier_1E384059 0;
BA_ "GenSigTimeoutTime_MCPB" SG_ 2654486617 SourceNodeIdentifier_1E384059 0;
BA_ "GenSigTimeoutTime_MCPA" SG_ 2654486617 SourceNodeIdentifier_1E384059 0;
BA_ "GenSigTimeoutTime_IDCM" SG_ 2654486617 SourceNodeIdentifier_1E384059 0;
BA_ "GenSigTimeoutTime_EVCU2" SG_ 2654486617 SourceNodeIdentifier_1E384059 0;
BA_ "GenSigTimeoutTime_ECM" SG_ 496 MessageCounter_PARK_DATA 0;
BA_ "GenSigTimeoutTime_BPCM" SG_ 496 MessageCounter_PARK_DATA 0;
BA_ "GenSigTimeoutTime_SGCP" SG_ 496 MessageCounter_PARK_DATA 0;
BA_ "GenSigTimeoutTime_MCPB" SG_ 496 MessageCounter_PARK_DATA 0;
BA_ "GenSigTimeoutTime_MCPA" SG_ 496 MessageCounter_PARK_DATA 0;
BA_ "GenSigTimeoutTime_IDCM" SG_ 496 MessageCounter_PARK_DATA 0;
BA_ "GenSigTimeoutTime_ECM" SG_ 496 Plock_MotorPosSts 0;
BA_ "GenSigTimeoutTime_BPCM" SG_ 496 Plock_MotorPosSts 0;
BA_ "GenSigTimeoutTime_SGCP" SG_ 496 Plock_MotorPosSts 0;
BA_ "GenSigTimeoutTime_MCPB" SG_ 496 Plock_MotorPosSts 0;
BA_ "GenSigTimeoutTime_MCPA" SG_ 496 Plock_MotorPosSts 0;
BA_ "GenSigTimeoutTime_IDCM" SG_ 496 Plock_MotorPosSts 0;
BA_ "GenSigTimeoutTime_ECM" SG_ 496 Plock_PosSensor 0;
BA_ "GenSigTimeoutTime_BPCM" SG_ 496 Plock_PosSensor 0;
BA_ "GenSigTimeoutTime_SGCP" SG_ 496 Plock_PosSensor 0;
BA_ "GenSigTimeoutTime_MCPB" SG_ 496 Plock_PosSensor 0;
BA_ "GenSigTimeoutTime_MCPA" SG_ 496 Plock_PosSensor 0;
BA_ "GenSigTimeoutTime_IDCM" SG_ 496 Plock_PosSensor 0;
BA_ "GenSigTimeoutTime_ECM" SG_ 496 PlockFailSts 0;
BA_ "GenSigTimeoutTime_BPCM" SG_ 496 PlockFailSts 0;
BA_ "GenSigTimeoutTime_SGCP" SG_ 496 PlockFailSts 0;
BA_ "GenSigTimeoutTime_MCPB" SG_ 496 PlockFailSts 0;
BA_ "GenSigTimeoutTime_MCPA" SG_ 496 PlockFailSts 0;
BA_ "GenSigTimeoutTime_IDCM" SG_ 496 PlockFailSts 0;
BA_ "GenSigTimeoutTime_ECM" SG_ 496 CRC_PARK_DATA 0;
BA_ "GenSigTimeoutTime_BPCM" SG_ 496 CRC_PARK_DATA 0;
BA_ "GenSigTimeoutTime_SGCP" SG_ 496 CRC_PARK_DATA 0;
BA_ "GenSigTimeoutTime_MCPB" SG_ 496 CRC_PARK_DATA 0;
BA_ "GenSigTimeoutTime_MCPA" SG_ 496 CRC_PARK_DATA 0;
BA_ "GenSigTimeoutTime_IDCM" SG_ 496 CRC_PARK_DATA 0;
BA_ "GenSigTimeoutTime_ECM" SG_ 496 Plock_fdbk_sts 0;
BA_ "GenSigTimeoutTime_BPCM" SG_ 496 Plock_fdbk_sts 0;
BA_ "GenSigTimeoutTime_SGCP" SG_ 496 Plock_fdbk_sts 0;
BA_ "GenSigTimeoutTime_MCPB" SG_ 496 Plock_fdbk_sts 0;
BA_ "GenSigTimeoutTime_MCPA" SG_ 496 Plock_fdbk_sts 0;
BA_ "GenSigTimeoutTime_IDCM" SG_ 496 Plock_fdbk_sts 0;
BA_ "GenSigTimeoutTime_ECM" SG_ 496 MPR_PosSensor 0;
BA_ "GenSigTimeoutTime_BPCM" SG_ 496 MPR_PosSensor 0;
BA_ "GenSigTimeoutTime_SGCP" SG_ 496 MPR_PosSensor 0;
BA_ "GenSigTimeoutTime_MCPB" SG_ 496 MPR_PosSensor 0;
BA_ "GenSigTimeoutTime_MCPA" SG_ 496 MPR_PosSensor 0;
BA_ "GenSigTimeoutTime_IDCM" SG_ 496 MPR_PosSensor 0;
BA_ "GenSigTimeoutTime_ECM" SG_ 2564485397 N_PDU_18DAF115 0;
BA_ "GenSigTimeoutTime_BPCM" SG_ 2564485397 N_PDU_18DAF115 0;
BA_ "GenSigTimeoutTime_SGCP" SG_ 2564485397 N_PDU_18DAF115 0;
BA_ "GenSigTimeoutTime_MCPB" SG_ 2564485397 N_PDU_18DAF115 0;
BA_ "GenSigTimeoutTime_MCPA" SG_ 2564485397 N_PDU_18DAF115 0;
BA_ "GenSigTimeoutTime_IDCM" SG_ 2564485397 N_PDU_18DAF115 0;
BA_ "GenSigTimeoutTime_EVCU2" SG_ 2564485397 N_PDU_18DAF115 0;
BA_ "GenSigTimeoutTime_MCPB" SG_ 260 INVRRInterlockSts 0;
BA_ "GenSigTimeoutTime_MCPA" SG_ 260 INVRRInterlockSts 0;
BA_ "GenSigTimeoutTime_IDCM" SG_ 260 INVRRInterlockSts 0;
BA_ "GenSigTimeoutTime_ECM" SG_ 260 InvRR_DC_Voltage 0;
BA_ "GenSigTimeoutTime_BPCM" SG_ 260 InvRR_DC_Voltage 0;
BA_ "GenSigTimeoutTime_SGCP" SG_ 260 InvRR_DC_Voltage 0;
BA_ "GenSigTimeoutTime_MCPB" SG_ 260 InvRR_DC_Voltage 0;
BA_ "GenSigTimeoutTime_MCPA" SG_ 260 InvRR_DC_Voltage 0;
BA_ "GenSigTimeoutTime_IDCM" SG_ 260 InvRR_DC_Voltage 0;
BA_ "GenSigTimeoutTime_ECM" SG_ 260 MCPB_Torque_Achieved_V 0;
BA_ "GenSigTimeoutTime_BPCM" SG_ 260 MCPB_Torque_Achieved_V 0;
BA_ "GenSigTimeoutTime_SGCP" SG_ 260 MCPB_Torque_Achieved_V 0;
BA_ "GenSigTimeoutTime_MCPB" SG_ 260 MCPB_Torque_Achieved_V 0;
BA_ "GenSigTimeoutTime_MCPA" SG_ 260 MCPB_Torque_Achieved_V 0;
BA_ "GenSigTimeoutTime_IDCM" SG_ 260 MCPB_Torque_Achieved_V 0;
BA_ "GenSigTimeoutTime_ECM" SG_ 260 MCPB_TorqAchieved_AEMD_V 0;
BA_ "GenSigTimeoutTime_BPCM" SG_ 260 MCPB_TorqAchieved_AEMD_V 0;
BA_ "GenSigTimeoutTime_SGCP" SG_ 260 MCPB_TorqAchieved_AEMD_V 0;
BA_ "GenSigTimeoutTime_MCPB" SG_ 260 MCPB_TorqAchieved_AEMD_V 0;
BA_ "GenSigTimeoutTime_MCPA" SG_ 260 MCPB_TorqAchieved_AEMD_V 0;
BA_ "GenSigTimeoutTime_IDCM" SG_ 260 MCPB_TorqAchieved_AEMD_V 0;
BA_ "GenSigTimeoutTime_ECM" SG_ 260 MCPB_Torque_Achieved 0;
BA_ "GenSigTimeoutTime_BPCM" SG_ 260 MCPB_Torque_Achieved 0;
BA_ "GenSigStartValue" SG_ 260 MCPB_Torque_Achieved 4096;
BA_ "GenSigTimeoutTime_SGCP" SG_ 260 MCPB_Torque_Achieved 0;
BA_ "GenSigTimeoutTime_MCPB" SG_ 260 MCPB_Torque_Achieved 0;
BA_ "GenSigTimeoutTime_MCPA" SG_ 260 MCPB_Torque_Achieved 0;
BA_ "GenSigTimeoutTime_IDCM" SG_ 260 MCPB_Torque_Achieved 0;
BA_ "GenSigTimeoutTime_ECM" SG_ 260 RPM_MCPB 0;
BA_ "GenSigTimeoutTime_BPCM" SG_ 260 RPM_MCPB 0;
BA_ "GenSigStartValue" SG_ 260 RPM_MCPB 32768;
BA_ "GenSigTimeoutTime_SGCP" SG_ 260 RPM_MCPB 0;
BA_ "GenSigTimeoutTime_MCPB" SG_ 260 RPM_MCPB 0;
BA_ "GenSigTimeoutTime_MCPA" SG_ 260 RPM_MCPB 0;
BA_ "GenSigTimeoutTime_IDCM" SG_ 260 RPM_MCPB 0;
BA_ "GenSigTimeoutTime_ECM" SG_ 260 CRC_PRR1 0;
BA_ "GenSigTimeoutTime_SGCP" SG_ 260 CRC_PRR1 0;
BA_ "GenSigTimeoutTime_MCPB" SG_ 260 CRC_PRR1 0;
BA_ "GenSigTimeoutTime_MCPA" SG_ 260 CRC_PRR1 0;
BA_ "GenSigTimeoutTime_IDCM" SG_ 260 CRC_PRR1 0;
BA_ "GenSigTimeoutTime_ECM" SG_ 260 MCPB_SPT_Stat 0;
BA_ "GenSigTimeoutTime_BPCM" SG_ 260 MCPB_SPT_Stat 0;
BA_ "GenSigTimeoutTime_SGCP" SG_ 260 MCPB_SPT_Stat 0;
BA_ "GenSigTimeoutTime_ECM" SG_ 105 PIMRR_CoolantFlow 0;
BA_ "GenSigTimeoutTime_BPCM" SG_ 105 PIMRR_CoolantFlow 0;
BA_ "GenSigSendType" SG_ 105 PIMRR_CoolantFlow 3;
BA_ "GenSigTimeoutTime_MCPB" SG_ 105 PIMRR_CoolantFlow 0;
BA_ "GenSigTimeoutTime_MCPA" SG_ 105 PIMRR_CoolantFlow 0;
BA_ "GenSigTimeoutTime_IDCM" SG_ 105 PIMRR_CoolantFlow 0;
BA_ "GenSigTimeoutTime_EVCU2" SG_ 105 PIMRR_CoolantFlow 0;
BA_ "GenSigTimeoutTime_SGCP" SG_ 300 AEMD_Cutoff_FreqLow_MCPA 0;
BA_ "GenSigTimeoutTime_MCPB" SG_ 300 AEMD_Cutoff_FreqLow_MCPA 0;
BA_ "GenSigTimeoutTime_IDCM" SG_ 300 AEMD_Cutoff_FreqLow_MCPA 0;
BA_ "GenSigTimeoutTime_EVCU2" SG_ 300 AEMD_Cutoff_FreqLow_MCPA 0;
BA_ "GenSigTimeoutTime_ECM" SG_ 546 GBT_Desired_SOC_Reached 0;
BA_ "GenSigTimeoutTime_BPCM" SG_ 546 GBT_Desired_SOC_Reached 0;
BA_ "GenSigTimeoutTime_SGCP" SG_ 546 GBT_Desired_SOC_Reached 0;
BA_ "GenSigTimeoutTime_MCPB" SG_ 546 GBT_Desired_SOC_Reached 0;
BA_ "GenSigTimeoutTime_MCPA" SG_ 546 GBT_Desired_SOC_Reached 0;
BA_ "GenSigTimeoutTime_EVCU2" SG_ 546 GBT_Desired_SOC_Reached 0;
BA_ "GenSigTimeoutTime_ECM" SG_ 546 GBT_Charger_Active_Interruption 0;
BA_ "GenSigTimeoutTime_BPCM" SG_ 546 GBT_Charger_Active_Interruption 0;
BA_ "GenSigTimeoutTime_ECM" SG_ 546 MessageCounter_VO2 0;
BA_ "GenSigTimeoutTime_SGCP" SG_ 546 MessageCounter_VO2 0;
BA_ "GenSigTimeoutTime_MCPB" SG_ 546 MessageCounter_VO2 0;
BA_ "GenSigTimeoutTime_MCPA" SG_ 546 MessageCounter_VO2 0;
BA_ "GenSigTimeoutTime_EVCU2" SG_ 546 MessageCounter_VO2 0;
BA_ "GenSigTimeoutTime_ECM" SG_ 546 BMS_HV_Trac_Bus_Sts_VDCM 0;
BA_ "GenSigTimeoutTime_SGCP" SG_ 546 BMS_HV_Trac_Bus_Sts_VDCM 0;
BA_ "GenSigTimeoutTime_EVCU2" SG_ 546 BMS_HV_Trac_Bus_Sts_VDCM 0;
BA_ "GenSigTimeoutTime_ECM" SG_ 546 BMS_HV_TractionBusVoltage_VDCM 0;
BA_ "GenSigTimeoutTime_SGCP" SG_ 546 BMS_HV_TractionBusVoltage_VDCM 0;
BA_ "GenSigTimeoutTime_EVCU2" SG_ 546 BMS_HV_TractionBusVoltage_VDCM 0;
BA_ "GenSigTimeoutTime_ECM" SG_ 546 BMS_Max_Cell_Volt_Allowed_VDCM 0;
BA_ "GenSigTimeoutTime_BPCM" SG_ 546 BMS_Max_Cell_Volt_Allowed_VDCM 0;
BA_ "GenSigTimeoutTime_SGCP" SG_ 546 BMS_Max_Cell_Volt_Allowed_VDCM 0;
BA_ "GenSigTimeoutTime_MCPB" SG_ 546 BMS_Max_Cell_Volt_Allowed_VDCM 0;
BA_ "GenSigTimeoutTime_MCPA" SG_ 546 BMS_Max_Cell_Volt_Allowed_VDCM 0;
BA_ "GenSigTimeoutTime_EVCU2" SG_ 546 BMS_Max_Cell_Volt_Allowed_VDCM 0;
BA_ "GenSigTimeoutTime_ECM" SG_ 546 BMS_Max_Pk_Volt_Allowed_VDCM 0;
BA_ "GenSigTimeoutTime_BPCM" SG_ 546 BMS_Max_Pk_Volt_Allowed_VDCM 0;
BA_ "GenSigTimeoutTime_SGCP" SG_ 546 BMS_Max_Pk_Volt_Allowed_VDCM 0;
BA_ "GenSigTimeoutTime_MCPB" SG_ 546 BMS_Max_Pk_Volt_Allowed_VDCM 0;
BA_ "GenSigTimeoutTime_MCPA" SG_ 546 BMS_Max_Pk_Volt_Allowed_VDCM 0;
BA_ "GenSigTimeoutTime_EVCU2" SG_ 546 BMS_Max_Pk_Volt_Allowed_VDCM 0;
BA_ "GenSigTimeoutTime_ECM" SG_ 546 BMS_HV_Temperature_Max_VDCM 0;
BA_ "GenSigTimeoutTime_BPCM" SG_ 546 BMS_HV_Temperature_Max_VDCM 0;
BA_ "GenSigTimeoutTime_SGCP" SG_ 546 BMS_HV_Temperature_Max_VDCM 0;
BA_ "GenSigTimeoutTime_MCPB" SG_ 546 BMS_HV_Temperature_Max_VDCM 0;
BA_ "GenSigTimeoutTime_MCPA" SG_ 546 BMS_HV_Temperature_Max_VDCM 0;
BA_ "GenSigTimeoutTime_EVCU2" SG_ 546 BMS_HV_Temperature_Max_VDCM 0;
BA_ "GenSigTimeoutTime_ECM" SG_ 546 BMS_HV_SOC_AccuracySts_VDCM 0;
BA_ "GenSigTimeoutTime_BPCM" SG_ 546 BMS_HV_SOC_AccuracySts_VDCM 0;
BA_ "GenSigSendType" SG_ 546 BMS_HV_SOC_AccuracySts_VDCM 3;
BA_ "GenSigTimeoutTime_SGCP" SG_ 546 BMS_HV_SOC_AccuracySts_VDCM 0;
BA_ "GenSigTimeoutTime_MCPB" SG_ 546 BMS_HV_SOC_AccuracySts_VDCM 0;
BA_ "GenSigTimeoutTime_MCPA" SG_ 546 BMS_HV_SOC_AccuracySts_VDCM 0;
BA_ "GenSigTimeoutTime_EVCU2" SG_ 546 BMS_HV_SOC_AccuracySts_VDCM 0;
BA_ "GenSigTimeoutTime_MCPA" SG_ 546 BMS_HV_Temperature_Min_VDCM 0;
BA_ "GenSigTimeoutTime_EVCU2" SG_ 546 BMS_HV_Temperature_Min_VDCM 0;
BA_ "GenSigTimeoutTime_ECM" SG_ 546 BMS_HV_Temperature_Min_VDCM 0;
BA_ "GenSigTimeoutTime_BPCM" SG_ 546 BMS_HV_Temperature_Min_VDCM 0;
BA_ "GenSigTimeoutTime_SGCP" SG_ 546 BMS_HV_Temperature_Min_VDCM 0;
BA_ "GenSigTimeoutTime_MCPB" SG_ 546 BMS_HV_Temperature_Min_VDCM 0;
BA_ "GenSigTimeoutTime_ECM" SG_ 546 BMS_HV_Trac_Main_Contac_Sts_VDCM 0;
BA_ "GenSigTimeoutTime_SGCP" SG_ 546 BMS_HV_Trac_Main_Contac_Sts_VDCM 0;
BA_ "GenSigTimeoutTime_EVCU2" SG_ 546 BMS_HV_Trac_Main_Contac_Sts_VDCM 0;
BA_ "GenSigTimeoutTime_ECM" SG_ 546 BMS_HV_NumCellMinTemp_VDCM 0;
BA_ "GenSigTimeoutTime_BPCM" SG_ 546 BMS_HV_NumCellMinTemp_VDCM 0;
BA_ "GenSigTimeoutTime_SGCP" SG_ 546 BMS_HV_NumCellMinTemp_VDCM 0;
BA_ "GenSigTimeoutTime_MCPB" SG_ 546 BMS_HV_NumCellMinTemp_VDCM 0;
BA_ "GenSigTimeoutTime_MCPA" SG_ 546 BMS_HV_NumCellMinTemp_VDCM 0;
BA_ "GenSigTimeoutTime_EVCU2" SG_ 546 BMS_HV_NumCellMinTemp_VDCM 0;
BA_ "GenSigTimeoutTime_ECM" SG_ 546 BMS_HV_Common_Contactor_Sts_VDCM 0;
BA_ "GenSigTimeoutTime_SGCP" SG_ 546 BMS_HV_Common_Contactor_Sts_VDCM 0;
BA_ "GenSigTimeoutTime_EVCU2" SG_ 546 BMS_HV_Common_Contactor_Sts_VDCM 0;
BA_ "GenSigTimeoutTime_ECM" SG_ 546 BMS_HV_High_Temp_Thrsh_VDCM 0;
BA_ "GenSigTimeoutTime_BPCM" SG_ 546 BMS_HV_High_Temp_Thrsh_VDCM 0;
BA_ "GenSigTimeoutTime_SGCP" SG_ 546 BMS_HV_High_Temp_Thrsh_VDCM 0;
BA_ "GenSigTimeoutTime_MCPB" SG_ 546 BMS_HV_High_Temp_Thrsh_VDCM 0;
BA_ "GenSigTimeoutTime_MCPA" SG_ 546 BMS_HV_High_Temp_Thrsh_VDCM 0;
BA_ "GenSigTimeoutTime_EVCU2" SG_ 546 BMS_HV_High_Temp_Thrsh_VDCM 0;
BA_ "GenSigTimeoutTime_SGCP" SG_ 546 BMS_HV_InternalVoltage_VDCM 0;
BA_ "GenSigTimeoutTime_EVCU2" SG_ 546 BMS_HV_InternalVoltage_VDCM 0;
BA_ "GenSigTimeoutTime_ECM" SG_ 546 CRC_VO2 0;
BA_ "GenSigTimeoutTime_SGCP" SG_ 546 CRC_VO2 0;
BA_ "GenSigTimeoutTime_MCPB" SG_ 546 CRC_VO2 0;
BA_ "GenSigTimeoutTime_MCPA" SG_ 546 CRC_VO2 0;
BA_ "GenSigTimeoutTime_EVCU2" SG_ 546 CRC_VO2 0;
BA_ "GenSigTimeoutTime_ECM" SG_ 546 CPIM_Over_Temperature 0;
BA_ "GenSigTimeoutTime_BPCM" SG_ 546 CPIM_Over_Temperature 0;
BA_ "GenSigTimeoutTime_SGCP" SG_ 546 CPIM_Over_Temperature 0;
BA_ "GenSigTimeoutTime_MCPB" SG_ 546 CPIM_Over_Temperature 0;
BA_ "GenSigTimeoutTime_MCPA" SG_ 546 CPIM_Over_Temperature 0;
BA_ "GenSigTimeoutTime_EVCU2" SG_ 546 CPIM_Over_Temperature 0;
BA_ "GenSigStartValue" SG_ 546 VDCM_BattFullSOC_prc 100;
BA_ "GenSigTimeoutTime_SGCP" SG_ 546 VDCM_BattFullSOC_prc 0;
BA_ "GenSigTimeoutTime_MCPB" SG_ 546 VDCM_BattFullSOC_prc 0;
BA_ "GenSigTimeoutTime_MCPA" SG_ 546 VDCM_BattFullSOC_prc 0;
BA_ "GenSigTimeoutTime_EVCU2" SG_ 546 VDCM_BattFullSOC_prc 0;
BA_ "GenSigTimeoutTime_ECM" SG_ 546 CPIM_Error 0;
BA_ "GenSigTimeoutTime_BPCM" SG_ 546 CPIM_Error 0;
BA_ "GenSigTimeoutTime_SGCP" SG_ 546 CPIM_Error 0;
BA_ "GenSigTimeoutTime_MCPB" SG_ 546 CPIM_Error 0;
BA_ "GenSigTimeoutTime_MCPA" SG_ 546 CPIM_Error 0;
BA_ "GenSigTimeoutTime_EVCU2" SG_ 546 CPIM_Error 0;
BA_ "GenSigTimeoutTime_ECM" SG_ 546 VDCM_ChrgCurrDeviationErr 0;
BA_ "GenSigTimeoutTime_BPCM" SG_ 546 VDCM_ChrgCurrDeviationErr 0;
BA_ "GenSigTimeoutTime_SGCP" SG_ 546 VDCM_ChrgCurrDeviationErr 0;
BA_ "GenSigTimeoutTime_MCPB" SG_ 546 VDCM_ChrgCurrDeviationErr 0;
BA_ "GenSigTimeoutTime_MCPA" SG_ 546 VDCM_ChrgCurrDeviationErr 0;
BA_ "GenSigTimeoutTime_EVCU2" SG_ 546 VDCM_ChrgCurrDeviationErr 0;
BA_ "GenSigTimeoutTime_ECM" SG_ 546 VDCM_ChrgCompleteReason 0;
BA_ "GenSigTimeoutTime_BPCM" SG_ 546 VDCM_ChrgCompleteReason 0;
BA_ "GenSigTimeoutTime_SGCP" SG_ 546 VDCM_ChrgCompleteReason 0;
BA_ "GenSigTimeoutTime_MCPB" SG_ 546 VDCM_ChrgCompleteReason 0;
BA_ "GenSigTimeoutTime_MCPA" SG_ 546 VDCM_ChrgCompleteReason 0;
BA_ "GenSigTimeoutTime_EVCU2" SG_ 546 VDCM_ChrgCompleteReason 0;
BA_ "GenSigTimeoutTime_ECM" SG_ 546 ReadyToChargeState 0;
BA_ "GenSigTimeoutTime_BPCM" SG_ 546 ReadyToChargeState 0;
BA_ "GenSigTimeoutTime_SGCP" SG_ 546 ReadyToChargeState 0;
BA_ "GenSigTimeoutTime_MCPB" SG_ 546 ReadyToChargeState 0;
BA_ "GenSigTimeoutTime_MCPA" SG_ 546 ReadyToChargeState 0;
BA_ "GenSigTimeoutTime_EVCU2" SG_ 546 ReadyToChargeState 0;
BA_ "GenSigTimeoutTime_ECM" SG_ 546 HCP_SessionStopCmd 0;
BA_ "GenSigTimeoutTime_BPCM" SG_ 546 HCP_SessionStopCmd 0;
BA_ "GenSigTimeoutTime_SGCP" SG_ 546 HCP_SessionStopCmd 0;
BA_ "GenSigTimeoutTime_MCPB" SG_ 546 HCP_SessionStopCmd 0;
BA_ "GenSigTimeoutTime_MCPA" SG_ 546 HCP_SessionStopCmd 0;
BA_ "GenSigTimeoutTime_EVCU2" SG_ 546 HCP_SessionStopCmd 0;
BA_ "GenSigTimeoutTime_ECM" SG_ 546 HCP_DC_Retry 0;
BA_ "GenSigTimeoutTime_BPCM" SG_ 546 HCP_DC_Retry 0;
BA_ "GenSigTimeoutTime_SGCP" SG_ 546 HCP_DC_Retry 0;
BA_ "GenSigTimeoutTime_MCPB" SG_ 546 HCP_DC_Retry 0;
BA_ "GenSigTimeoutTime_MCPA" SG_ 546 HCP_DC_Retry 0;
BA_ "GenSigTimeoutTime_EVCU2" SG_ 546 HCP_DC_Retry 0;
BA_ "GenSigTimeoutTime_ECM" SG_ 546 DCChrg_BatSideCurrent_VDCM 0;
BA_ "GenSigTimeoutTime_BPCM" SG_ 546 DCChrg_BatSideCurrent_VDCM 0;
BA_ "GenSigStartValue" SG_ 546 DCChrg_BatSideCurrent_VDCM 50;
BA_ "GenSigTimeoutTime_SGCP" SG_ 546 DCChrg_BatSideCurrent_VDCM 0;
BA_ "GenSigTimeoutTime_MCPB" SG_ 546 DCChrg_BatSideCurrent_VDCM 0;
BA_ "GenSigTimeoutTime_MCPA" SG_ 546 DCChrg_BatSideCurrent_VDCM 0;
BA_ "GenSigTimeoutTime_EVCU2" SG_ 546 DCChrg_BatSideCurrent_VDCM 0;
BA_ "GenSigTimeoutTime_ECM" SG_ 546 VDCM_CellVoltIsOOR 0;
BA_ "GenSigTimeoutTime_BPCM" SG_ 546 VDCM_CellVoltIsOOR 0;
BA_ "GenSigTimeoutTime_SGCP" SG_ 546 VDCM_CellVoltIsOOR 0;
BA_ "GenSigTimeoutTime_MCPB" SG_ 546 VDCM_CellVoltIsOOR 0;
BA_ "GenSigTimeoutTime_MCPA" SG_ 546 VDCM_CellVoltIsOOR 0;
BA_ "GenSigTimeoutTime_EVCU2" SG_ 546 VDCM_CellVoltIsOOR 0;
BA_ "GenSigTimeoutTime_ECM" SG_ 546 VDCM_BattTempIsOOR 0;
BA_ "GenSigTimeoutTime_BPCM" SG_ 546 VDCM_BattTempIsOOR 0;
BA_ "GenSigTimeoutTime_SGCP" SG_ 546 VDCM_BattTempIsOOR 0;
BA_ "GenSigTimeoutTime_MCPB" SG_ 546 VDCM_BattTempIsOOR 0;
BA_ "GenSigTimeoutTime_MCPA" SG_ 546 VDCM_BattTempIsOOR 0;
BA_ "GenSigTimeoutTime_EVCU2" SG_ 546 VDCM_BattTempIsOOR 0;
BA_ "GenSigTimeoutTime_ECM" SG_ 546 VDCM_ChargeCurrIsOOR 0;
BA_ "GenSigTimeoutTime_BPCM" SG_ 546 VDCM_ChargeCurrIsOOR 0;
BA_ "GenSigTimeoutTime_SGCP" SG_ 546 VDCM_ChargeCurrIsOOR 0;
BA_ "GenSigTimeoutTime_MCPB" SG_ 546 VDCM_ChargeCurrIsOOR 0;
BA_ "GenSigTimeoutTime_MCPA" SG_ 546 VDCM_ChargeCurrIsOOR 0;
BA_ "GenSigTimeoutTime_EVCU2" SG_ 546 VDCM_ChargeCurrIsOOR 0;
BA_ "GenSigTimeoutTime_ECM" SG_ 546 VDCM_ChrgMode_Req 0;
BA_ "GenSigTimeoutTime_BPCM" SG_ 546 VDCM_ChrgMode_Req 0;
BA_ "GenSigTimeoutTime_SGCP" SG_ 546 VDCM_ChrgMode_Req 0;
BA_ "GenSigTimeoutTime_MCPB" SG_ 546 VDCM_ChrgMode_Req 0;
BA_ "GenSigTimeoutTime_MCPA" SG_ 546 VDCM_ChrgMode_Req 0;
BA_ "GenSigTimeoutTime_EVCU2" SG_ 546 VDCM_ChrgMode_Req 0;
BA_ "GenSigTimeoutTime_BPCM" SG_ 2651930712 Digit_02_MCPA 0;
BA_ "GenSigTimeoutTime_SGCP" SG_ 2651930712 Digit_02_MCPA 0;
BA_ "GenSigTimeoutTime_MCPB" SG_ 2651930712 Digit_02_MCPA 0;
BA_ "GenSigTimeoutTime_MCPA" SG_ 2651930712 Digit_02_MCPA 0;
BA_ "GenSigTimeoutTime_IDCM" SG_ 2651930712 Digit_02_MCPA 0;
BA_ "GenSigTimeoutTime_ECM" SG_ 2651930712 Digit_02_MCPA 0;
BA_ "GenSigTimeoutTime_ECM" SG_ 2651930712 Digit_01_MCPA 0;
BA_ "GenSigTimeoutTime_BPCM" SG_ 2651930712 Digit_01_MCPA 0;
BA_ "GenSigSendType" SG_ 2651930712 Digit_01_MCPA 1;
BA_ "GenSigTimeoutTime_SGCP" SG_ 2651930712 Digit_01_MCPA 0;
BA_ "GenSigTimeoutTime_MCPB" SG_ 2651930712 Digit_01_MCPA 0;
BA_ "GenSigTimeoutTime_MCPA" SG_ 2651930712 Digit_01_MCPA 0;
BA_ "GenSigTimeoutTime_IDCM" SG_ 2651930712 Digit_01_MCPA 0;
BA_ "GenSigTimeoutTime_ECM" SG_ 2651930712 Digit_06_MCPA 0;
BA_ "GenSigTimeoutTime_BPCM" SG_ 2651930712 Digit_06_MCPA 0;
BA_ "GenSigTimeoutTime_ECM" SG_ 2651930712 Digit_04_MCPA 0;
BA_ "GenSigTimeoutTime_BPCM" SG_ 2651930712 Digit_04_MCPA 0;
BA_ "GenSigTimeoutTime_SGCP" SG_ 2651930712 Digit_04_MCPA 0;
BA_ "GenSigTimeoutTime_MCPB" SG_ 2651930712 Digit_04_MCPA 0;
BA_ "GenSigTimeoutTime_MCPA" SG_ 2651930712 Digit_04_MCPA 0;
BA_ "GenSigTimeoutTime_IDCM" SG_ 2651930712 Digit_04_MCPA 0;
BA_ "GenSigTimeoutTime_ECM" SG_ 2651930712 Digit_03_MCPA 0;
BA_ "GenSigTimeoutTime_BPCM" SG_ 2651930712 Digit_03_MCPA 0;
BA_ "GenSigTimeoutTime_SGCP" SG_ 2651930712 Digit_03_MCPA 0;
BA_ "GenSigTimeoutTime_MCPB" SG_ 2651930712 Digit_03_MCPA 0;
BA_ "GenSigTimeoutTime_MCPA" SG_ 2651930712 Digit_03_MCPA 0;
BA_ "GenSigTimeoutTime_IDCM" SG_ 2651930712 Digit_03_MCPA 0;
BA_ "GenSigTimeoutTime_ECM" SG_ 2651930712 Digit_08_MCPA 0;
BA_ "GenSigTimeoutTime_BPCM" SG_ 2651930712 Digit_08_MCPA 0;
BA_ "GenSigTimeoutTime_SGCP" SG_ 2651930712 Digit_08_MCPA 0;
BA_ "GenSigTimeoutTime_MCPB" SG_ 2651930712 Digit_08_MCPA 0;
BA_ "GenSigTimeoutTime_MCPA" SG_ 2651930712 Digit_08_MCPA 0;
BA_ "GenSigTimeoutTime_IDCM" SG_ 2651930712 Digit_08_MCPA 0;
BA_ "GenSigTimeoutTime_ECM" SG_ 2651930712 Digit_07_MCPA 0;
BA_ "GenSigTimeoutTime_BPCM" SG_ 2651930712 Digit_07_MCPA 0;
BA_ "GenSigTimeoutTime_SGCP" SG_ 2651930712 Digit_07_MCPA 0;
BA_ "GenSigTimeoutTime_MCPB" SG_ 2651930712 Digit_07_MCPA 0;
BA_ "GenSigTimeoutTime_MCPA" SG_ 2651930712 Digit_07_MCPA 0;
BA_ "GenSigTimeoutTime_IDCM" SG_ 2651930712 Digit_07_MCPA 0;
BA_ "GenSigTimeoutTime_ECM" SG_ 250 APM_CtrlSts_Fbk 0;
BA_ "GenSigTimeoutTime_BPCM" SG_ 250 APM_CtrlSts_Fbk 0;
BA_ "GenSigTimeoutTime_SGCP" SG_ 250 APM_CtrlSts_Fbk 0;
BA_ "GenSigTimeoutTime_MCPB" SG_ 250 APM_CtrlSts_Fbk 0;
BA_ "GenSigTimeoutTime_MCPA" SG_ 250 APM_CtrlSts_Fbk 0;
BA_ "GenSigTimeoutTime_IDCM" SG_ 250 APM_CtrlSts_Fbk 0;
BA_ "GenSigTimeoutTime_ECM" SG_ 250 APM_DeratingModeStatus 0;
BA_ "GenSigTimeoutTime_BPCM" SG_ 250 APM_DeratingModeStatus 0;
BA_ "GenSigTimeoutTime_SGCP" SG_ 250 APM_DeratingModeStatus 0;
BA_ "GenSigTimeoutTime_MCPB" SG_ 250 APM_DeratingModeStatus 0;
BA_ "GenSigTimeoutTime_MCPA" SG_ 250 APM_DeratingModeStatus 0;
BA_ "GenSigTimeoutTime_IDCM" SG_ 250 APM_DeratingModeStatus 0;
BA_ "GenSigTimeoutTime_ECM" SG_ 250 APM_CurrentLimitMode 0;
BA_ "GenSigTimeoutTime_BPCM" SG_ 250 APM_CurrentLimitMode 0;
BA_ "GenSigTimeoutTime_SGCP" SG_ 250 APM_CurrentLimitMode 0;
BA_ "GenSigTimeoutTime_MCPB" SG_ 250 APM_CurrentLimitMode 0;
BA_ "GenSigTimeoutTime_MCPA" SG_ 250 APM_CurrentLimitMode 0;
BA_ "GenSigTimeoutTime_IDCM" SG_ 250 APM_CurrentLimitMode 0;
VAL_ 1031 AC_Side_Volt3 8191 "SNA";
VAL_ 1031 AC_Side_Volt2 8191 "SNA";
VAL_ 1031 AC_Side_Volt1 8191 "SNA";
VAL_ 1031 AC_Side_Curr3 2047 "SNA";
VAL_ 1031 AC_Side_Curr2 2047 "SNA";
VAL_ 1031 AC_Side_Curr1 2047 "SNA";
VAL_ 260 INVRRInterlockSts 0 "Not_Performed" 1 "OK" 2 "Fail" 3 "Invalid";
VAL_ 260 InvRR_DC_Voltage 1023 "SNA";
VAL_ 1031 InputCurrentAvailable 511 "SNA";
VAL_ 1031 ProximitySts 0 "PROX_LO" 1 "Prox_Out" 2 "Prox_In" 3 "Prox_Un" 4 "VOOR" 5 "PROX_HI";
VAL_ 1031 OBCM_SlacSts 0 "SLAC_NOT_PERFORMED" 1 "EVSE_FOUND" 2 "EVSE_NOT_FOUND" 3 "FAILURE";
VAL_ 1031 OBCM_SdpSts 0 "SPD_NOT_PERFORMED" 1 "CONN_ESTABLISHED" 2 "CONN_NOT_ESTABLISHED" 3 "FAILURE";
VAL_ 1031 OBCInterlockSts 0 "Not_Performed" 1 "OK" 2 "Fail" 3 "Invalid";
VAL_ 1031 OBC_DeratingReason 0 "No_Derating" 1 "High_Temp_Derating" 2 "Low_Temp_Derating" 3 "Input_Voltage_Limit" 4 "Input_Current_Limit" 5 "Output_Voltage_Limit" 6 "Output_Current_Limit" 7 "Internal_Fault_Derating" 8 "High_Charge_Inlet_Temperature";
VAL_ 1031 J1772_State 0 "STATE_A" 1 "STATE_B" 2 "STATE_C" 3 "STATE_D" 4 "STATE_E" 5 "STATE_F" 7 "SNA";
VAL_ 1031 J1772_S2_Sts 0 "Open" 1 "Closed";
VAL_ 1031 ControlPilotSts 0 "NO_EVSE" 1 "CP_DET" 2 "VOOR" 3 "EVSE_NO_AC" 4 "HW_FAULT" 5 "EVSE_FAULT";
VAL_ 1031 ChargeEnableSts 0 "NotCharging" 1 "Charging" 3 "SNA";
VAL_ 1031 ChargeCurrentAvailable 1023 "SNA";
VAL_ 1031 ChargeCurrent 1023 "SNA";
VAL_ 1031 BatterySideCurrent 2047 "SNA";
VAL_ 1031 AC_Present 0 "AC not detected" 1 "AC detected";
VAL_ 250 APM_Water_Temp 255 "SNA";
VAL_ 250 APM_RecoveryAction 1 "APM_Not_working" 2 "APM_safe_state" 3 "APM_safe_state_and_not_working" 4 "APM_voltage_control_mode" 5 "APM_wake_up_loss" 6 "APM_safe_state_and_voltage_control_mode" 8 "Wake_up_loss" 16 "Eeprom_loss";
VAL_ 250 APM_PSFB_Temp2 4095 "SNA";
VAL_ 250 APM_PSFB_Temp1 4095 "SNA";
VAL_ 250 APM_LV_V_Fbk 4095 "SNA";
VAL_ 250 APM_LV_I_Fbk 4095 "SNA";
VAL_ 250 APM_HV_V_Fbk 4095 "SNA";
VAL_ 250 APM_HV_I_Fbk 4095 "SNA";
VAL_ 250 APM_Buck_Temp 4095 "SNA";
VAL_ 546 VDCM_EV_Batt_Max_T_Limit 255 "SNA";
VAL_ 546 VDCM_ChrgMode_Req 0 "init" 1 "constant voltage charge" 2 "constant curent charge" 255 "SNA";
VAL_ 546 VDCM_ChrgCurrDeviationErr 0 "Charge Current  OK" 1 "Charge current in error";
VAL_ 546 VDCM_ChrgCompleteReason 0 "SOC_tgt_reached" 1 "Vcell_tgt_reached" 2 "Vbat_tgt_reached" 3 "User_req";
VAL_ 546 VDCM_BattUnderVolt 0 "Voltage OK" 1 "Battery Under Voltage";
VAL_ 546 VDCM_BattOverVolt 0 "Voltage OK" 1 "Battery Over Voltage";
VAL_ 546 VDCM_BattFullSOC_prc 255 "SNA";
VAL_ 546 CPIM_Over_Temperature 0 "Battery_OK" 1 "Over_temperature";
VAL_ 546 CPIM_Error 0 "CPIM_OK" 1 "CPIM_error";
VAL_ 260 InvRR_DerateReason 0 "Reason1" 1 "Reason2" 2 "Reason3" 3 "Reason4" 4 "Reason5" 5 "Reason6" 6 "Reason7" 7 "Reason8" 8 "Reason9" 9 "Reason10" 10 "Reason11" 11 "Reason12" 12 "Reason13" 13 "Reason14" 14 "Reason15" 15 "Reason16";
VAL_ 260 InvRR_ACVoltage 1023 "SNA";
VAL_ 544 Plug_Locked_by_EVSE 0 "EVSE_Not_Locked" 1 "EVSE_Locked" 2 "Init" 3 "SNA";
VAL_ 544 HVCMS_EVSEID 4294967295 "SNA";
VAL_ 544 ExtChargerSts 0 "Standby" 1 "Charging" 2 "Init" 3 "SNA";
VAL_ 544 EVSE_Error 0 "No_Error" 1 "Error" 2 "Init" 3 "SNA";
VAL_ 544 EVSE_ChrgStopControl 0 "No_Chrg_Stp_Cntrl" 1 "Chrg_Stop_Cntrl" 2 "Init" 3 "SNA";
VAL_ 544 Charger_WeldingDetectAvail 0 "Not_Available" 1 "Available" 2 "Init" 3 "SNA";
VAL_ 544 Charger_StndbyReqReason 0 "SetUpCond_Reached" 1 "BMS_Req" 2 "Charger_Fault" 3 "User_Req" 6 "Init" 7 "SNA";
VAL_ 544 Charger_StndbyReq 0 "Stnby_Not_Requested" 1 "Stnby_Requested" 2 "Init" 3 "SNA";
VAL_ 544 Charger_FaultStates 0 "NoFault" 1 "EmergencyShdwnFault" 2 "UnableToSupplyReqPower" 3 "OverTemperature" 4 "InnerOverTemperature" 5 "AbnormalVoltage" 6 "CurrentNotMatching" 7 "ConnectorFault" 8 "OtherFault" 14 "Init" 15 "SNA";
VAL_ 544 CC2VoltDetError 0 "Volt_Det_ok" 1 "Volt_Det_Error" 2 "Init" 3 "SNA";
VAL_ 1790 BMS_HV_SOC_AccuracySts 0 "Invalid" 1 "High_Accuracy_SOC" 2 "Low_Accuracy_SOC" 3 "SNA";
VAL_ 105 T7_CoolantTempVldty 0 "Valid" 1 "Not_Valid";
VAL_ 105 PwrElecSnsr_TEMP 255 "SNA";
VAL_ 105 PwrElecPmp_TEMP 255 "SNA";
VAL_ 105 ClrLgsDiagInfo 0 "FALSE" 1 "TRUE";
VAL_ 546 WeldCheck_Complete 0 "FALSE" 1 "TRUE";
VAL_ 546 VDCM_SOCIsOOR 0 "Normal" 1 "Too_Low" 2 "Too High" 3 "SNA";
VAL_ 546 VDCM_ChargeCurrIsOOR 0 "Normal" 1 "Too_Low" 2 "Too High" 3 "SNA";
VAL_ 546 VDCM_CellVoltIsOOR 0 "Normal" 1 "Too_Low" 2 "Too High" 3 "SNA";
VAL_ 546 VDCM_BattTempIsOOR 0 "Normal" 1 "Too_Low" 2 "Too High" 3 "SNA";
VAL_ 546 ReadyToChargeState 0 "FALSE" 1 "TRUE";
VAL_ 546 HCP_SessionStopCmd 0 "FALSE" 1 "TRUE";
VAL_ 546 HCP_DC_Retry 0 "No_Rety_Command" 1 "SupportedAppProtocolReq" 2 "SessionSetupRrq" 3 "ServiceDiscoveryReq." 4 "ServicePaymentSelectionReq" 5 "Contract_AuthenticationReq" 6 "ChargeParameterDiscoveryReq" 7 "CableCheckReq" 8 "Pre_ChargeReq" 9 "PowerDeliveryReq_Precharge" 10 "CurrentDemandReq" 11 "PowerDeliveryReq_EnergyTransfer" 12 "WeldingDetectionReq" 13 "SessionStopReq" 31 "SNA";
VAL_ 546 BMS_Max_Pk_Volt_Allowed_VDCM 1023 "SNA";
VAL_ 546 BMS_Max_Cell_Volt_Allowed_Vldty 0 "Valid" 1 "Not_Valid";
VAL_ 546 BMS_Max_Cell_Volt_Allowed_VDCM 8191 "SNA";
VAL_ 546 BMS_HV_Trac_PreCha_Contac_Sts_V 0 "Open" 1 "Closed" 3 "Error_Stuck_Open" 4 "Error_Stuck_Closed" 7 "SNA";
VAL_ 546 BMS_HV_Trac_Main_Contac_Sts_VDCM 0 "Open" 1 "Closed" 3 "Error_Stuck_Open" 4 "Error_Stuck_Closed" 7 "SNA";
VAL_ 546 BMS_HV_Temperature_Min_VDCM 2047 "SNA";
VAL_ 546 BMS_HV_Temperature_Max_VDCM 2047 "SNA";
VAL_ 546 BMS_HV_SOC_AccuracySts_VDCM 0 "Invalid" 1 "High_Accuracy_SOC" 2 "Low_Accuracy_SOC" 3 "SNA";
VAL_ 546 BMS_HV_NumCellMinTemp_VDCM 511 "SNA";
VAL_ 546 BMS_HV_NumCellMaxVolt_VDCM 255 "SNA";
VAL_ 546 BMS_HV_NumCellMaxTemp_VDCM 511 "SNA";
VAL_ 546 BMS_HV_InternalVoltage_VDCM 8191 "SNA";
VAL_ 546 BMS_HV_Common_Contactor_Sts_VDCM 0 "Open" 1 "Closed" 2 "Error_Stuck_Open" 3 "Error_Stuck_Closed" 7 "SNA";
VAL_ 546 BMS_HV_Battery_GFD_Sts_VDCM 0 "GFD_Not_Performed" 1 "GFD_OK" 2 "GFD_Fail" 3 "GFD_INVALID_meas_noise";
VAL_ 546 BMS_HV_BatIntrlk_InternalStat_V 0 "Not_Performed" 1 "OK" 2 "Fail" 3 "Invalid";
VAL_ 546 BMS_HV_AC_Char_Main_Contac_Sts_ 0 "Open" 1 "Closed" 3 "Error_Stuck_Open" 4 "Error_Stuck_Closed" 7 "SNA";
VAL_ 546 BMS_Cell_Volt_Min_Vldty_VDCM 0 "Valid" 1 "Not_Valid";
VAL_ 546 BMS_Cell_Volt_Min_VDCM 8191 "SNA";
VAL_ 546 BMS_Cell_Volt_Max_Vldty_VDCM 0 "Valid" 1 "Not_Valid";
VAL_ 546 BMS_Cell_Volt_Max_VDCM 8191 "SNA";
VAL_ 260 MCPB_Torque_Achieved_V 0 "Valid" 1 "Invalid";
VAL_ 260 MCPB_TorqAchieved_AEMD_V 0 "Valid" 1 "Invalid";
VAL_ 260 MCPB_RPM_V 0 "Valid" 1 "Invalid";
VAL_ 260 MCPB_MtrMinCpbltyTrq 8191 "SNA";
VAL_ 260 MCPB_MtrMaxCpbltyTrq 8191 "SNA";
VAL_ 260 MCPB_MtrIndex 31 "SNA";
VAL_ 260 MCPB_MinTorq 8191 "SNA";
VAL_ 260 MCPB_MaxTorq 8191 "SNA";
VAL_ 260 MCPB_Invrtr_State 0 "NORMAL_POWER_STAGE_OFF " 1 "NORMAL_POWER_STAGE_ON " 2 "NORMAL_POWER_STAGE_OVERRIDE" 3 "ACTIVE_DISCHARGE " 4 "INVERTER_FAULTED " 5 "NORMAL_POWER_STAGE_OFF_HV_RQD" 6 "NORMAL_VC_PRIMING" 7 "NORMAL_VC_ON";
VAL_ 260 MCPB_HV_CnctrOpn_Req 0 "False" 1 "True";
VAL_ 260 MCPB_Dschrge_Status 0 "AD_INDETERMINATE" 1 "AD_INPROGRESS" 2 "AD_COMPLETE" 3 "AD_FAILED";
VAL_ 260 MCPB_DeratingFactor 63 "SNA";
VAL_ 260 MCPB_DC_Volt_V 0 "Valid" 1 "Invalid";
VAL_ 260 MCPB_DC_Current_V 0 "Valid" 1 "Invalid";
VAL_ 260 MCPB_CpbltySpdDivVolt 65535 "SNA";
VAL_ 260 MCPB_AccelRawV 0 "Valid" 1 "Invalid";
VAL_ 260 MCPB_6SO_Status 0 "3PS" 1 "6SO" 2 "Switching" 3 "SNA";
VAL_ 260 MCPB_3PS_Pos 0 "False" 1 "True";
VAL_ 496 PlockFailSts 0 "Fault_Not_Present" 1 "Derating" 2 "Retrying" 3 "Non recoverable critical fault" 7 "SNA";
VAL_ 496 Plock_PosSensor 0 "Init" 1 "Unknown" 2 "Engaged" 3 "Between Engaged and Disengaged" 4 "Tooth to Tooth" 5 "Disengaged" 7 "SNA";
VAL_ 496 Plock_MotorPosSts 0 "Init" 1 "Unknown" 2 "Engaged Endstop" 3 "Engaged" 4 "Between Engaged and Disengaged" 5 "Disengaged" 6 "Disengaged Endstop" 7 "SNA";
VAL_ 496 MPR_PosSensor 0 "Init" 1 "Unknown" 2 "Engaged" 3 "Disengaged" 7 "SNA";
VAL_ 544 OBCM_CSSts 0 "CS_IN" 1 "CS_OUT" 2 "CS_FAIL";
VAL_ 544 OBCM_CP3Sts 0 "Charge permission disabled" 1 "Charge permission enabled" 3 "HW_Fault";
VAL_ 544 OBCM_CP2Sts 0 "EVSE_not_ready" 1 "EVSE_ready" 2 "VOOR" 3 "HW_Fault";
VAL_ 544 OBCM_CCSts 0 "CC_LO" 1 "CC_OUT" 2 "CC_IN" 3 "CC_HI" 4 "CC_FAIL";
VAL_ 544 OBCM_APAMSts 0 "APAM_Off" 1 "APAM_On" 2 "HW_Failure";
VAL_ 1454 MCPB_Service_Lamp_Request 0 "False" 1 "True";
VAL_ 1062 MCPA_Temp 255 "SNA";
VAL_ 1062 MCPA_Rotor_Temperature 255 "SNA";
VAL_ 1062 MCPA_Inverter_Temp 255 "SNA";
VAL_ 1062 MCPA_Control_Board_Temperature 255 "SNA";
VAL_ 1062 CLrDiagInfo_MCPA 0 "False" 1 "True";
VAL_ 1444 MCPA_Service_Lamp_Request 0 "False" 1 "True";
VAL_ 300 Mtr_6SO_Request_MCPB 0 "False" 1 "True";
VAL_ 300 Mtr_6SO_Request_MCPA 0 "False" 1 "True";
VAL_ 300 ModeCommand_MCPB 0 "Inverter_Disabled" 1 "Torque_Control" 2 "Speed_Control" 3 "Active_Discharge" 4 "Disable_Immediate" 5 "Voltage_Control" 6 "Rapid_Shutdown" 7 "Shutdown_Initiated" 8 "ROL_Routine" 9 "Active_Short_Circuit" 15 "SNA";
VAL_ 300 ModeCommand_MCPA 0 "Inverter_Disabled" 1 "Torque_Control" 2 "Speed_Control" 3 "Active_Discharge" 4 "Disable_Immediate" 5 "Voltage_Control" 6 "0x6 Rapid_Shutdown" 7 "Shutdown_Initiated" 8 "ROL_Routine" 9 "Active_Short_Circuit" 15 "SNA";
VAL_ 1031 Supported_VerNumberMinor 0 "No_Version" 1 "Version_1" 2 "Version_2" 7 "SNA";
VAL_ 1031 Supported_VerNumberMajor 0 "No_Version" 1 "Version_1" 2 "Version_2" 7 "SNA";
VAL_ 1031 Supported_SchemaID 0 "No_Schema_ID" 1 "Schema_ID_1" 2 "Schema_ID_2" 3 "Schema_ID_3" 7 "SNA";
VAL_ 1031 Supported_ProtocolName 0 "No_Protocol" 1 "ISO_Gen2" 2 "ISO_Gen1" 3 "DIN" 7 "SNA";
VAL_ 2654486617 CBV_bit3_NMCoordinatorBit_1E384059 0 "Start of synchronized shutdown is not requested by main coordinator" 1 "Start of synchronized shutdown is requested by main coordinator";
VAL_ 2654486617 CBV_bit4_ActiveWakeupBit_1E384059 0 "PassiveWakeup" 1 "ActiveWakeup";
VAL_ 2654486617 CBV_bit6_PartialNtwInfBit_1E384059 0 "NM PDU contains no Partial Network request information" 1 "NM PDU contains Partial Network request information";
VAL_ 2654486617 CBV_bit0_RepeatMessageRequestBit_1E384059 0 "Repeat Message State not requested" 1 "Repeat Message State requested";
VAL_ 1031 EVCC_FailureReason 0 "None" 1 "SLAC_Failed." 2 "SECCDiscoverProtocol_Failed" 3 "TransportLayer_Failed" 4 "SupportAppProtocol_Failed" 5 "SessionSetup_Failed" 6 "Session Discover_Failed" 7 "ReadContrCertChain_Failed" 8 "ServiceDetail_Failed" 9 "PaymentServiceSelection_Failed" 10 "ReadRootCerts_Failed" 11 "ReadProvCert_Failed" 12 "CertificateInstallation_Failed" 13 "CertificateUpdate_Failed" 14 "PaymentDetails_Failed" 15 "Authorization_Failed" 16 "ChargeParameterDiscovery_Failed" 17 "PowerDelivery_Failed" 18 "MeteringReceipt_Failed" 19 "ChargingStatus_Failed" 20 "CableCheck_Failed" 21 "Precharge_Failed" 22 "CurrentDemand_Failed" 23 "WeldingDetection_Failed." 24 "SessionStop_Failed." 25 "StopCommunicationSession_Failed." 26 "IPAddressWaitTime" 27 "Sequence Performancetime." 28 "CommunicationSetupTime" 29 "ReadyToChargeTime" 30 "AuthorizationOngoinTime" 31 "ChrgParaDiscoveryOngoingTime" 32 "CableCheckOngoingTime." 33 "PrechargeOngoingTime." 34 "Init_ContractSelectionFailed" 35 "SDP_NoSharedSecurityOption." 36 "SDP_InvalidEnergyTransferMode." 37 "SD_NoSharedPaymentOption" 38 "SD_NoContractAndNoCertSrvcAvail" 39 "SrvcDet_NoContr_InstallSrvcAvail" 40 "TLS_Failed" 41 "V2G_Cert_Invalid" 63 "SNA";
VAL_ 1031 BatterySideVoltage 16383 "SNA";
VAL_ 1031 AC_LnLow 0 "voltage_in_range" 1 "voltage_above_threshold";
VAL_ 1031 AC_LnHi 0 "voltage_in_range" 1 "voltage_above_threshold";
VAL_ 1790 HEV_OnRq_BPCM 0 "FALSE" 1 "TRUE";
VAL_ 250 APM_UtilPctOfDCDC 127 "SNA";
VAL_ 250 APM_TempColdPlate 254 "Failure" 255 "SNA";
VAL_ 250 APM_OutputPower 1023 "SNA";
VAL_ 250 APM_InputPower 1023 "SNA";
VAL_ 250 APM_IdcHvSetPFdbk 1023 "SNA";
VAL_ 250 APM_HvVsetPFdbk 511 "SNA";
VAL_ 250 APM_FailureType 0 "No_failure" 1 "Failure_chargingInhibited" 2 "Failure_chargingAllowed" 3 "SNA";
VAL_ 250 APM_FailureReason 0 "No_Failure" 1 "Fail_high_voltage_at_HV" 2 "Fail_low_voltage_at_HV" 3 "Fail_high_voltage_at_LV" 4 "Fail_low_voltage_at_LV" 5 "Fail_high_PCB_temperature" 6 "Fail_high_DCB_temperature" 7 "Fail_high_cur_at_LV" 8 "Fail_high_cur_at_HV" 9 "Fail_short_circ_at_LV" 10 "Fail_short_circ_at_HV" 11 "Fail_open_circ_at_LV" 12 "Fail_open_circ_at_HV" 13 "Fail_init_failure" 14 "Fail_wake_up_issue" 15 "Fail_internal_hardware" 16 "Fail_bat_feed_low" 17 "Fail_bat_feed_high" 18 "Fail_Aux_OV" 19 "Fail_Aux_UV" 20 "Fail_HVIL_fault" 21 "Fail_LOC_with_HCP" 22 "Fail_LOC_with_BPCM" 23 "Fail_cont_not_closed" 24 "Fail_SBC_fault" 25 "Memory_Fail" 26 "Implausible_data_from_HCP" 27 "Implausible_data_from_BPCM" 28 "CAN_bus_off" 29 "Fail_temp_diff_is_high" 30 "Fail_high_voltage_diff_is_high" 31 "Fail_for_other_reason" 32 "LOC_ORC" 33 "Implausble_data_ORC" 63 "SNA";
VAL_ 250 APM_EstPwrLoss 255 "SNA";
VAL_ 250 APM_DeratingReason 0 "No_derating" 1 "high_temp_De_rating" 2 "low_temp_De_rating" 3 "OverVolt_HV_De_rating" 4 "lowVolt_HV_De_rating" 5 "highVolt_LV_De_rating" 6 "lowVolt_LV_De_rating" 7 "highCurrent_LV_Current_limit" 8 "internal_HD_fail_De_rating" 9 "high_current_HV_De_rating" 31 "SNA";
VAL_ 250 APM_DeratingModeStatus 0 "No_derating" 1 "Derating_Initialized" 2 "Derating_Initialized_Failure" 3 "Derating_Mode" 7 "SNA";
VAL_ 250 APM_CtrlSts_Fbk 0 "IDLE" 1 "Buck_CV_voltage" 2 "Buck_CC_current_control" 3 "APM_Temporary_Fault" 4 "Buck_Special" 6 "PreCharge" 7 "DisCharge" 8 "OFF" 9 "Derating" 10 "APM_Critical_Fault" 15 "SNA";
VAL_ 546 BMS_HV_Char_PreCha_Contac_Sts_V 0 "Open" 1 "Closed" 3 "Error_Stuck_Open" 4 "Error_Stuck_Closed" 7 "SNA";
VAL_ 546 BMS_HV_Char_Main_Contac_Sts_VDCM 0 "Open" 1 "Closed" 3 "Error_Stuck_Open" 4 "Error_Stuck_Closed" 7 "SNA";
VAL_ 2654486616 CBV_bit0_RepeatMessageRequestBit_1E384058 0 "Repeat Message State not requested" 1 "Repeat Message State requested";
VAL_ 2654486616 CBV_bit3_NMCoordinatorBit_1E384058 0 "Start of synchronized shutdown is not requested by main coordinator" 1 "Start of synchronized shutdown is requested by main coordinator";
VAL_ 2654486616 CBV_bit4_ActiveWakeupBit_1E384058 0 "PassiveWakeup" 1 "ActiveWakeup";
VAL_ 2654486616 CBV_bit6_PartialNtwInfBit_1E384058 0 "NM PDU contains no Partial Network request information" 1 "NM PDU contains Partial Network request information";
VAL_ 546 BMS_HV_TractionBusVoltage_VDCM 1023 "SNA";
VAL_ 546 BMS_HV_Trac_Bus_Sts_VDCM 0 "OPEN" 1 "CLOSED" 2 "PRECHARGING" 3 "PRECHARGING FAILED" 4 "PRECHARGING INHIBITED" 7 "SNA";
VAL_ 546 BMS_HV_ChargingBusVoltage_VDCM 1023 "SNA";
VAL_ 546 BMS_HV_Char_Bus_Sts_VDCM 0 "OPEN" 1 "CLOSED" 2 "PRECHARGING" 3 "PRECHARGING FAILED" 4 "PRECHARGING INHIBITED" 7 "SNA";
VAL_ 546 BMS_HV_BatState_VDCM 0 "Sleep" 1 "Initialization" 2 "Idle" 3 "Bus_Acv_Deac" 5 "Ready_Main" 6 "Ready_Aux" 7 "Ready_Full" 10 "Deactivation" 13 "Powerlatch" 14 "Service_Mode" 15 "CRITICAL_ERROR";
VAL_ 546 BMS_HV_BatActualPower_VDCM 32767 "SNA";
VAL_ 260 InvRR_CoolantTemp 2047 "SNA";
VAL_ 544 TCP_Communication_Terminated 0 "FALSE" 1 "TRUE";
VAL_ 544 OBCM_CP1Sts 0 "NO_EVSE" 1 "CP_DET" 2 "VOOR" 3 "EVSE_NO_AC" 4 "HW_FAULT";
VAL_ 244 ImpactHardwireV 0 "Fail_Not_Present" 1 "Fail_Present";
VAL_ 244 ImpactHardwire 0 "Not_Actuate" 1 "Actuate";
VAL_ 260 MCPB_SPT_Stat 0 "Undetermined " 1 "Passed" 2 "Failed";
VAL_ 544 TxGBTMessageResponse 0 "EVSE_Not_Connected" 1 "CHM" 2 "CRM.BMS cant be recognized" 3 "CRM.BMS recognized" 4 "CML" 5 "CRO.Charger not ready" 6 "CRO.Charger ready" 7 "CCS" 8 "CST" 9 "CSD" 31 "SNA";
VAL_ 544 TxGBTMessageRequest 0 "EVSE_Not_Connected" 1 "BHM" 2 "BRM" 3 "BCP" 4 "BRO_BMS_Not_Ready" 5 "BRO_BMS_Ready" 6 "BCL" 7 "BCS" 8 "BSM" 9 "BST" 10 "BSD" 31 "SNA";
VAL_ 544 OBCM_Timeout 0 "False" 1 "True";
VAL_ 544 EVCC_FailureSts 0 "No_Failure" 1 "Failure";
VAL_ 544 CC2_VoltageValue 255 "SNA";
VAL_ 546 VDCM_ChargingPermitting 0 "Forbidden" 1 "Permissive";
VAL_ 546 GBT_Target_Voltage_Reached 0 "Not_Reached" 1 "Reached" 2 "SNA";
VAL_ 546 GBT_Target_Cell_Voltage_Reached 0 "Not_Reached" 1 "Reached" 2 "SNA";
VAL_ 546 GBT_Ready_to_Charge 0 "False" 1 "True";
VAL_ 546 GBT_Desired_SOC_Reached 0 "Not_Reached" 1 "Reached" 2 "SNA";
VAL_ 546 GBT_Charger_Active_Interruption 0 "No_Charger_Interruption" 1 "Charger_Interruption" 2 "SNA";
VAL_ 544 GBT_EVSE_Charge_Permitting 0 "Pause" 1 "Permissive";
VAL_ 300 AEMD_Sclr_Gn_MCPB 511 "SNA";
VAL_ 300 AEMD_Sclr_Gn_MCPA 511 "SNA";
VAL_ 250 APM_DeratingPower 63 "SNA";
VAL_ 496 Plock_fdbk_sts 0 "Init" 1 "Engaging" 2 "Engaged" 3 "Disengaging" 4 "Disengaged" 5 "Fault" 7 "SNA";
VAL_ 1031 RCD 0 "No_Error" 1 "Error";
VAL_ 1031 EVSENominalVoltage 1023 "SNA";
VAL_ 1031 EVSEMaxCurrent 511 "SNA";
VAL_ 1062 MCPA_PIM_DC_Side_Busbar_Temp 255 "SNA";
SIG_GROUP_ 244 BATTERY_HV_Pkt 1 : ImpactHardwireV ImpactHardwire;
SIG_GROUP_ 250 APM_VDCM_Pkt 1 : APM_Water_Temp APM_RecoveryAction APM_PSFB_Temp2 APM_PSFB_Temp1 APM_LV_V_Fbk APM_LV_I_Fbk APM_HV_V_Fbk APM_HV_I_Fbk APM_Buck_Temp APM_UtilPctOfDCDC APM_TempColdPlate APM_PowerLimitMode APM_OutputPower APM_InputPower APM_IdcHvSetPFdbk APM_HvVsetPFdbk APM_HvOverVStatus APM_FailureType APM_FailureReason APM_EstPwrLoss APM_DeratingReason APM_DeratingModeStatus APM_CurrentLimitMode APM_CtrlSts_Fbk MessageCounter_APM_VDCM CRC_APM_VDCM APM_DeratingPower;
SIG_GROUP_ 496 PARK_DATA_Pkt 1 : MessageCounter_PARK_DATA CRC_PARK_DATA PlockFailSts Plock_PosSensor Plock_MotorPosSts MPR_PosSensor Plock_fdbk_sts;
SIG_GROUP_ 544 OBCM_VDCM2_Pkt 1 : Plug_Locked_by_EVSE HVCMS_EVSEID ExtChargerSts EVSE_Error EVSE_ChrgStopControl Charger_WeldingDetectAvail Charger_StndbyReqReason Charger_StndbyReq Charger_FaultStates CC2VoltDetError OBCM_CSSts OBCM_CP3Sts OBCM_CP2Sts OBCM_CCSts OBCM_APAMSts TCP_Communication_Terminated OBCM_CP1Sts TxGBTMessageResponse TxGBTMessageRequest OBCM_Timeout EVCC_FailureSts CC2_VoltageValue GBT_EVSE_Charge_Permitting MessageCounter_OV2 CRC_OV2 EVSE_NotificationMaxDelay;
SIG_GROUP_ 1454 MCPB_DATA_Pkt 1 : MCPB_Service_Lamp_Request;
SIG_GROUP_ 1444 MCPA_DATA_Pkt 1 : MCPA_Service_Lamp_Request;
SIG_GROUP_ 1790 BATTERY_HV2_Pkt 1 : BMS_HV_SOC_AccuracySts BMS_HV_Low_Temp_Thrsh BMS_HV_High_Temp_Thrsh HVBatCell_Voltage_Low_Thrsh HVBatCell_Voltage_High_Thrsh HEV_OnRq_BPCM BMS_HV_SOC_Min BMS_HV_SOC_Max;
SIG_GROUP_ 260 PIM_RR_Pkt 1 : INVRRInterlockSts InvRR_DC_Voltage InvRR_DerateReason InvRR_ACVoltage RPM_MCPB MCPB_Torque_Achieved_V MCPB_Torque_Achieved MCPB_TorqAchieved_AEMD_V MCPB_TorqAchieved_AEMD MCPB_Spd_Lim MCPB_RPM_V MCPB_MtrMinCpbltyTrq MCPB_MtrMaxCpbltyTrq MCPB_MtrIndex MCPB_MinTorq MCPB_MaxTorq MCPB_Invrtr_State MCPB_HV_CnctrOpn_Req MCPB_Dschrge_Status MCPB_DeratingFactor MCPB_DC_Volt_V MCPB_DC_Current_V MCPB_DC_Current MCPB_CpbltySpdDivVolt MCPB_AccelRawV MCPB_AccelRaw MCPB_6SO_Status MCPB_3PS_Pos MC_PRR1 InvRR_CoolantTemp CRC_PRR1 MCPB_SPT_Stat;
SIG_GROUP_ 1062 MCPA_DATA2_Pkt 1 : MCPA_Temp MCPA_Rotor_Temperature MCPA_Inverter_Temp MCPA_Control_Board_Temperature CLrDiagInfo_MCPA MessageCounter_MCPA_DATA2 CRC_MCPA_DATA2 MCPA_PIM_DC_Side_Busbar_Temp MCPA_Service_Lamp_Request_2;
SIG_GROUP_ 1031 HV_CHARGER1_Pkt 1 : InputCurrentAvailable AC_Side_Volt3 AC_Side_Volt2 AC_Side_Volt1 AC_Side_Curr3 AC_Side_Curr2 AC_Side_Curr1 ProximitySts OBCM_SlacSts OBCM_SdpSts OBCInterlockSts OBC_DeratingReason J1772_State J1772_S2_Sts InputVoltage_isAC InputVoltage_is60Hz HV_Overvoltage HV_Overcurrent ControlPilotSts ChargeEnableSts ChargeCurrentAvailable ChargeCurrent BatterySideCurrent AC_Present AC_HighLoadWarning Supported_VerNumberMinor Supported_VerNumberMajor Supported_SchemaID Supported_ProtocolName MessageCounter_HV_CHARGER1 EVCC_FailureReason CRC_HV_CHARGER1 BatterySideVoltage AC_LnLow AC_LnHi RCD EVSENominalVoltage EVSEMaxCurrent;
SIG_GROUP_ 300 INVTARGET1_Pkt 1 : UDCMax_Unlim_MCPB UDCMax_Unlim_MCPA TqGrdtLim_MCPB TqGrdtLim_MCPA TorqueCommand_MCPB TorqueCommand_MCPA TargetMotorRPM_MCPB TargetMotorRPM_MCPA SpdGrdtLim_MCPB SpdGrdtLim_MCPA Mtr_6SO_Request_MCPB Mtr_6SO_Request_MCPA ModeCommand_MCPB ModeCommand_MCPA MessageCounter_INVTARGET1 CRC_INVTARGET1 AEMD_MinOffset_MCPB AEMD_MinOffset_MCPA AEMD_MaxOffset_MCPB AEMD_MaxOffset_MCPA AEMD_Sclr_Gn_MCPB AEMD_Sclr_Gn_MCPA AEMD_Cutoff_FreqHigh_MCPB AEMD_Cutoff_FreqHigh_MCPA Pwr_Electronics_Loop_FlwRate_MC AEMD_Cutoff_FreqLow_MCPB AEMD_Cutoff_FreqLow_MCPA Pwr_Elec_Loop_FlwRate_MC;
